VERSION ""

NS_ :

BS_:

BU_: PFAF_HS LVMPC_HS DCDC_HS AMP_HS VICM2_HS FICM_HS ARS_HS MCP_B_HS MCP_A_HS ICCM_OBD_HS SAS_HS ACCM_HS VLBS_HS EBCM_OBD_HS EDI_HS HPCC_HS VITM_OBD_HS PTAM_HS OBCM_HS VICM_HS HCP_HS FDCM_HS APPS_HS ICCM_HS EOCM_F_HS GPCM_HS FSCM_ITBC_HS SCM_HS ITBC_HS VCM_HS HMIM_HS FCP_HS VES_HS Dummy_HS MCP_C_HS RWS_HS ONSTAR_HS EPS_HS TestTool_HS MCP_HS BCP_HS ALC_HS AHL_AFL_HS SADS_HS EPB_HS FSCM_HS AFS_HS FCM_HS TCCM_HS RDCM_HS PTO_HS PCM_HS EBCM_HS ACC_HS BCM_HS TCM_HS ECM_HS

BO_ 417 ETEI_Engine_General_Status: 7 ECM_HS
  SG_ EngCrsCntrlMode: 29|3@0+ (1,0) [0|7] "" TCM_HS
  SG_ EngPstOxgSnsDgAstRq: 31|1@0+ (1,0) [0|1] "" TCM_HS
  SG_ CrsCtrlCnstSpdAct: 26|1@0+ (1,0) [0|1] "" TCM_HS
  SG_ WrmUpShftPtrnRq: 25|1@0+ (1,0) [0|1] "" TCM_HS
  SG_ EngIdlSpdRdcdRng: 39|8@0+ (8,0) [0|2040] "rpm" BCP_HS TCM_HS
  SG_ EngAlwCltAdp: 24|1@0+ (1,0) [0|1] "" TCM_HS
  SG_ BsTrgtEngIdlSpd: 47|8@0+ (8,0) [0|2040] "rpm" TCM_HS
  SG_ AccPdlPosPcntFullRngV: 17|1@0+ (1,0) [0|1] "" TCM_HS
  SG_ AccPdlPosPcntFullRng: 55|8@0+ (0.39215702,0) [0|100.00004] "%" TCM_HS
  SG_ DslPrtFltrIdlRgtnMdReq: 20|1@0+ (1,0) [0|1] "" TCM_HS
  SG_ DslPartFltrClngAlgActM: 18|1@0+ (1,0) [0|1] "" TCM_HS
  SG_ DslPartFltrClngAlgAct: 19|1@0+ (1,0) [0|1] "" TCM_HS
  SG_ EngCylDeactMd: 9|2@0+ (1,0) [0|3] "" BCP_HS
  SG_ ACCmCltEngd: 13|1@0+ (1,0) [0|1] "" TCM_HS
  SG_ ParkNeutralSwStatV: 21|1@0+ (1,0) [0|1] "" TCM_HS
  SG_ ParkNeutralSwStat: 22|1@0+ (1,0) [0|1] "" TCM_HS
  SG_ EngColdHiIdleActive: 23|1@0+ (1,0) [0|1] "" TCM_HS
  SG_ EngCyDactTqSmtAct: 6|1@0+ (1,0) [0|1] "" TCM_HS
  SG_ EngBrkStat: 15|2@0+ (1,0) [0|3] "" TCM_HS
  SG_ TracCntlSysPwrtrnInhbt: 12|1@0+ (1,0) [0|1] "" TCM_HS
  SG_ EngMtlProtAtv: 11|1@0+ (1,0) [0|1] "" TCM_HS
  SG_ EngDgTrqCnvClUnlkRqd: 7|1@0+ (1,0) [0|1] "" TCM_HS
  SG_ EngCyldrDeactReqd: 10|1@0+ (1,0) [0|1] "" TCM_HS
  SG_ ETGRReqdGear: 3|4@0+ (1,0) [0|15] "" TCM_HS
  SG_ ETGRReqType: 5|2@0+ (1,0) [0|3] "" TCM_HS

BO_ 1233 PPEI_Engine_General_Status_5: 8 ECM_HS
  SG_ EngShtdwnAct: 48|1@0+ (1,0) [0|1] "" Vector__XXX
  SG_ EngShtdwnPndgIO: 49|1@0+ (1,0) [0|1] "" FCP_HS ONSTAR_HS BCM_HS
  SG_ FuelFltChgNwIO: 51|1@0+ (1,0) [0|1] "" FCP_HS ONSTAR_HS BCM_HS
  SG_ PTExPrtclFltrWrn2IO: 50|1@0+ (1,0) [0|1] "" PTO_HS FCP_HS ONSTAR_HS BCM_HS
  SG_ PTHiElecLdReqd: 52|1@0+ (1,0) [0|1] "" BCM_HS
  SG_ PTExPrtclFltrWrnIO: 53|1@0+ (1,0) [0|1] "" PTO_HS FCP_HS ONSTAR_HS BCM_HS
  SG_ AirCndOffIO: 0|1@0+ (1,0) [0|1] "" BCM_HS
  SG_ DslGlwPlgIO: 55|1@0+ (1,0) [0|1] "" BCM_HS
  SG_ StgDisIO: 30|1@0+ (1,0) [0|1] "" BCM_HS
  SG_ RdcdPwrIO: 31|1@0+ (1,0) [0|1] "" FCP_HS ONSTAR_HS BCM_HS
  SG_ FuelTotCap: 27|12@0+ (0.125,0) [0|511.875] "liters" EDI_HS LVMPC_HS BCM_HS
  SG_ FlLvlPctV: 28|1@0+ (1,0) [0|1] "" EDI_HS LVMPC_HS AHL_AFL_HS PTO_HS FICM_HS BCM_HS
  SG_ FlLvlPct: 47|8@0+ (0.39215702,0) [0|100.00004] "%" EDI_HS LVMPC_HS PTO_HS AHL_AFL_HS FICM_HS BCM_HS
  SG_ EngWtrInFlIO: 54|1@0+ (1,0) [0|1] "" FCP_HS ONSTAR_HS BCM_HS
  SG_ EngOilTmpV: 7|1@0+ (1,0) [0|1] "" EDI_HS LVMPC_HS EPS_HS BCM_HS
  SG_ EngOilTmp: 15|8@0+ (1,-40) [-40|215] "deg C" EDI_HS LVMPC_HS EPS_HS BCM_HS
  SG_ EngOilPrsV: 6|1@0+ (1,0) [0|1] "" EDI_HS LVMPC_HS PTO_HS BCM_HS
  SG_ EngOilPrsLwIO: 5|1@0+ (1,0) [0|1] "" PTO_HS FCP_HS ONSTAR_HS BCM_HS
  SG_ EngOilPrs: 23|8@0+ (4,0) [0|1020] "kPa" EDI_HS LVMPC_HS PTO_HS BCM_HS
  SG_ EngOilLvlLwIO: 4|1@0+ (1,0) [0|1] "" PTO_HS FCP_HS ONSTAR_HS BCM_HS
  SG_ EngOilChngIO: 3|1@0+ (1,0) [0|1] "" BCM_HS
  SG_ EngHt_StpEngIO: 1|1@0+ (1,0) [0|1] "" PTO_HS FCP_HS ONSTAR_HS BCM_HS
  SG_ EngHotFuelEnrchmntIO: 2|1@0+ (1,0) [0|1] "" FCP_HS ONSTAR_HS BCM_HS
  SG_ CkFlFilrCapIO: 29|1@0+ (1,0) [0|1] "" BCM_HS

BO_ 1217 PPEI_Engine_General_Status_4: 8 ECM_HS
  SG_ LegPstDTCClrDrvCyCm: 40|1@0+ (1,0) [0|1] "" VICM2_HS EBCM_OBD_HS EBCM_HS VICM_HS OBCM_HS VITM_OBD_HS BCP_HS ICCM_OBD_HS ICCM_HS FSCM_ITBC_HS FSCM_HS TCM_HS
  SG_ LegDiagColdStCndMet: 47|1@0+ (1,0) [0|1] "" VICM2_HS FICM_HS ICCM_OBD_HS ICCM_HS FSCM_ITBC_HS FSCM_HS MCP_HS EBCM_OBD_HS EBCM_HS OBCM_HS BCP_HS TCCM_HS VITM_OBD_HS VICM_HS TCM_HS
  SG_ LegDiagColdStCndFltPr: 46|1@0+ (1,0) [0|1] "" VICM2_HS FICM_HS ICCM_OBD_HS ICCM_HS FSCM_ITBC_HS FSCM_HS MCP_HS EBCM_OBD_HS EBCM_HS OBCM_HS TCCM_HS VITM_OBD_HS VICM_HS TCM_HS BCP_HS
  SG_ EngEconMdCmnd: 44|1@0+ (1,0) [0|1] "" TCM_HS
  SG_ DslExhFldRmngDstHRsV: 41|1@0+ (1,0) [0|1] "" BCM_HS FCP_HS ONSTAR_HS
  SG_ DslExhFldRmngDstHRs: 54|15@0+ (2,0) [0|65534] "km" BCM_HS FCP_HS ONSTAR_HS
  SG_ EngOilHotIO: 45|1@0+ (1,0) [0|1] "" BCM_HS
  SG_ OAT_PT_EstV: 3|1@0+ (1,0) [0|1] "" FICM_HS TCM_HS TCCM_HS AHL_AFL_HS HCP_HS BCP_HS RDCM_HS BCM_HS EBCM_OBD_HS EBCM_HS
  SG_ LegDiagStndCndMet: 2|1@0+ (1,0) [0|1] "" VICM2_HS FICM_HS MCP_HS EBCM_OBD_HS EBCM_HS OBCM_HS VITM_OBD_HS VICM_HS BCP_HS FCP_HS ONSTAR_HS ICCM_OBD_HS ICCM_HS FSCM_ITBC_HS FSCM_HS TCM_HS TCCM_HS
  SG_ LegDiagStndCndFltPr: 1|1@0+ (1,0) [0|1] "" VICM2_HS FICM_HS MCP_HS EBCM_OBD_HS EBCM_HS VITM_OBD_HS VICM_HS OBCM_HS BCP_HS ICCM_OBD_HS ICCM_HS FSCM_ITBC_HS FSCM_HS TCM_HS TCCM_HS
  SG_ OAT_PT_EstM: 4|1@0+ (1,0) [0|1] "" FICM_HS HCP_HS TCM_HS TCCM_HS AHL_AFL_HS BCP_HS RDCM_HS BCM_HS EBCM_OBD_HS EBCM_HS
  SG_ OAT_PT_Est: 39|8@0+ (0.5,-40) [-40|87.5] "deg C" FICM_HS TCM_HS TCCM_HS AHL_AFL_HS HCP_HS BCP_HS RDCM_HS BCM_HS EBCM_OBD_HS EBCM_HS
  SG_ EngWrmUpAch: 0|1@0+ (1,0) [0|1] "" FICM_HS MCP_HS VITM_OBD_HS EBCM_OBD_HS EBCM_HS VICM_HS OBCM_HS BCP_HS ICCM_OBD_HS ICCM_HS FSCM_ITBC_HS FSCM_HS TCM_HS TCCM_HS
  SG_ EngIntAirTmpV: 5|1@0+ (1,0) [0|1] "" EDI_HS ICCM_OBD_HS ICCM_HS RDCM_HS VICM2_HS FICM_HS VICM_HS EBCM_OBD_HS EBCM_HS FCP_HS ONSTAR_HS SADS_HS BCP_HS TCCM_HS HCP_HS BCM_HS
  SG_ EngIntAirTmp: 31|8@0+ (1,-40) [-40|215] "deg C" EDI_HS ICCM_OBD_HS ICCM_HS RDCM_HS VICM2_HS FICM_HS VICM_HS EBCM_OBD_HS EBCM_HS FCP_HS ONSTAR_HS SADS_HS BCP_HS TCCM_HS HCP_HS BCM_HS
  SG_ EngCltTmpV: 6|1@0+ (1,0) [0|1] "" EDI_HS LVMPC_HS EPS_HS VCM_HS FICM_HS ICCM_OBD_HS ICCM_HS FSCM_HS VICM_HS FCP_HS ONSTAR_HS SADS_HS HCP_HS BCP_HS VICM2_HS BCM_HS EBCM_OBD_HS EBCM_HS
  SG_ EngCltTmp: 23|8@0+ (1,-40) [-40|215] "deg C" EDI_HS LVMPC_HS EPS_HS VCM_HS FICM_HS ICCM_OBD_HS ICCM_HS FSCM_HS VICM_HS FCP_HS ONSTAR_HS SADS_HS HCP_HS BCP_HS VICM2_HS BCM_HS EBCM_OBD_HS EBCM_HS
  SG_ BarPrsAbsV: 7|1@0+ (1,0) [0|1] "" EDI_HS VICM_HS FICM_HS EBCM_OBD_HS EBCM_HS BCP_HS HCP_HS ICCM_OBD_HS ICCM_HS FSCM_ITBC_HS FSCM_HS BCM_HS
  SG_ BarPrsAbs: 15|8@0+ (0.5,0) [0|127.5] "kPa" EDI_HS VICM_HS FICM_HS EBCM_OBD_HS EBCM_HS BCP_HS HCP_HS ICCM_OBD_HS ICCM_HS FSCM_ITBC_HS FSCM_HS BCM_HS

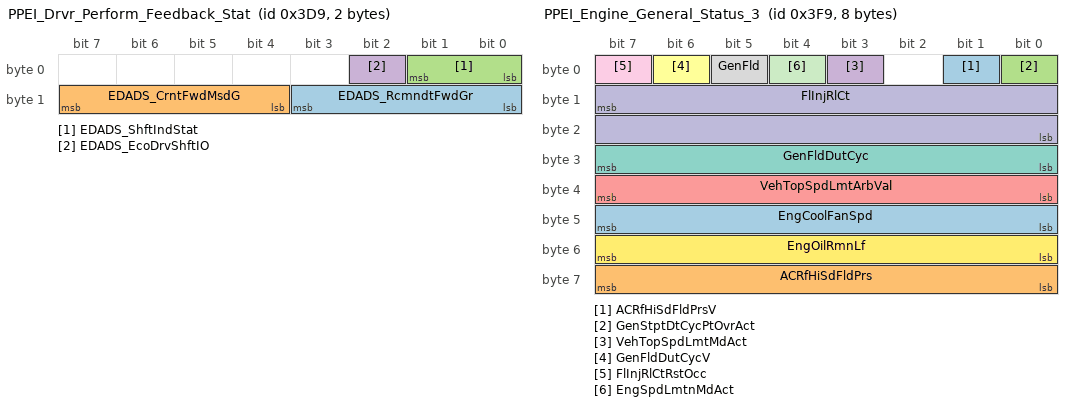
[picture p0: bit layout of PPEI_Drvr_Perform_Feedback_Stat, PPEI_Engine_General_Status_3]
BO_ 985 PPEI_Drvr_Perform_Feedback_Stat: 2 ECM_HS
  SG_ EDADS_RcmndtFwdGr: 11|4@0+ (1,0) [0|15] "" BCM_HS
  SG_ EDADS_CrntFwdMsdG: 15|4@0+ (1,0) [0|15] "" BCM_HS
  SG_ EDADS_ShftIndStat: 1|2@0+ (1,0) [0|3] "" BCM_HS
  SG_ EDADS_EcoDrvShftIO: 2|1@0+ (1,0) [0|1] "" BCM_HS

BO_ 1017 PPEI_Engine_General_Status_3: 8 ECM_HS
  SG_ ACRfHiSdFldPrsV: 1|1@0+ (1,0) [0|1] "" VICM2_HS ICCM_OBD_HS ICCM_HS FSCM_HS VICM_HS FCP_HS ONSTAR_HS BCM_HS
  SG_ ACRfHiSdFldPrs: 63|8@0+ (14,0) [0|3570] "kPaG" VICM2_HS ICCM_OBD_HS ICCM_HS FSCM_HS VICM_HS FCP_HS ONSTAR_HS BCM_HS
  SG_ GenStptDtCycPtOvrAct: 0|1@0+ (1,0) [0|1] "" BCM_HS
  SG_ VehTopSpdLmtMdAct: 3|1@0+ (1,0) [0|1] "" PTO_HS BCM_HS
  SG_ VehTopSpdLmtArbVal: 39|8@0+ (2,0) [0|510] "km / h" PTO_HS BCM_HS
  SG_ GenFldDutCycV: 6|1@0+ (1,0) [0|1] "" BCM_HS
  SG_ GenFldDutCyc: 31|8@0+ (0.39215702,0) [0|100.00004] "%" BCM_HS
  SG_ GenFld: 5|1@0+ (1,0) [0|1] "" FCP_HS ONSTAR_HS AFS_HS BCM_HS
  SG_ FlInjRlCtRstOcc: 7|1@0+ (1,0) [0|1] "" VICM_HS FCP_HS ONSTAR_HS BCM_HS
  SG_ FlInjRlCt: 15|16@0+ (3.05176e-05,0) [0|1.9999709] "liters" VICM_HS FCP_HS ONSTAR_HS BCM_HS
  SG_ EngSpdLmtnMdAct: 4|1@0+ (1,0) [0|1] "" BCM_HS
  SG_ EngOilRmnLf: 55|8@0+ (0.39215702,0) [0|100.00004] "%" BCM_HS
  SG_ EngCoolFanSpd: 47|8@0+ (0.39215702,0) [0|100.00004] "%" VICM_HS VICM2_HS ICCM_OBD_HS ICCM_HS FSCM_HS BCM_HS

BO_ 977 PPEI_Engine_General_Status_2: 8 ECM_HS
  SG_ AutoMdSpdLmtStat: 6|2@0+ (1,0) [0|3] "" BCM_HS
  SG_ FuelFltLifRstPerf: 38|1@0+ (1,0) [0|1] "" FCP_HS ONSTAR_HS BCM_HS
  SG_ SpdLmtrSpdWrngAct: 4|1@0+ (1,0) [0|1] "" TCM_HS BCM_HS
  SG_ CrsCntlDrSelSpdAct: 39|1@0+ (1,0) [0|1] "" BCM_HS
  SG_ ACCmpNrmLdGrdAld: 63|8@0+ (0.1,0) [0|25.5] "dm3/m/s" BCM_HS
  SG_ ACCompCmnd: 37|1@0+ (1,0) [0|1] "" VICM2_HS ICCM_OBD_HS ICCM_HS FSCM_HS BCM_HS
  SG_ EngBstPrsIndV: 23|1@0+ (1,0) [0|1] "" LVMPC_HS BCM_HS
  SG_ EngBstPrsInd: 55|8@0+ (0.39215702,0) [0|100.00004] "%" LVMPC_HS BCM_HS
  SG_ EngOilLifRstPerf: 36|1@0+ (1,0) [0|1] "" BCM_HS
  SG_ ThrPosV: 7|1@0+ (1,0) [0|1] "" EDI_HS ACC_HS EOCM_F_HS SADS_HS BCM_HS
  SG_ ThrPos: 15|8@0+ (0.39215702,0) [0|100.00004] "%" EDI_HS ACC_HS EOCM_F_HS SADS_HS BCM_HS
  SG_ InstFuelConsmpRate: 35|12@0+ (0.025000002,0) [0|102.375] "ltrs/hr" EDI_HS BCM_HS
  SG_ EngOilStrvtnIO: 21|1@0+ (1,0) [0|1] "" BCM_HS
  SG_ EngNEmsnsRelMalfAct: 3|1@0+ (1,0) [0|1] "" BCM_HS
  SG_ EngEmsRelMalfIndReq: 2|3@0+ (1,0) [0|7] "" BCM_HS
  SG_ EngCstFlCutAct: 22|1@0+ (1,0) [0|1] "" TCM_HS VICM_HS BCP_HS BCM_HS
  SG_ CrsSpdLmtrDrvSelSpd: 19|12@0+ (0.0625,0) [0|255.9375] "km / h" TCM_HS BCM_HS

BO_ 201 PPEI_Engine_General_Status_1: 8 ECM_HS
  SG_ PrsElvtdIdlCntlStat: 49|1@0+ (1,0) [0|1] "" BCM_HS
  SG_ Eng12vStrtrMtrCmmdOn: 53|1@0+ (1,0) [0|1] "" BCM_HS DCDC_HS RDCM_HS MCP_C_HS FICM_HS TCM_HS HCP_HS BCP_HS MCP_B_HS MCP_A_HS EPB_HS EBCM_OBD_HS EBCM_HS TCCM_HS VES_HS EPS_HS
  SG_ EngCntrlRunCrnkTrmSt: 52|1@0+ (1,0) [0|1] "" MCP_C_HS TCM_HS EBCM_OBD_HS EBCM_HS MCP_B_HS MCP_A_HS HCP_HS BCP_HS VITM_OBD_HS VICM_HS OBCM_HS FSCM_ITBC_HS ACCM_HS VICM2_HS FSCM_HS ICCM_OBD_HS ICCM_HS FICM_HS
  SG_ EngAirIntBstPrV: 51|1@0+ (1,0) [0|1] "" EDI_HS LVMPC_HS FICM_HS BCM_HS
  SG_ EngAirIntBstPr: 63|8@0- (1,0) [-128|127] "kPaG" EDI_HS LVMPC_HS FICM_HS BCM_HS
  SG_ SpdLmtrSpdWrngEnbld: 47|1@0+ (1,0) [0|1] "" PTO_HS BCM_HS
  SG_ EngCylDactEvntPndg: 54|1@0+ (1,0) [0|1] "" ICCM_OBD_HS ICCM_HS FSCM_ITBC_HS FSCM_HS AMP_HS
  SG_ EngCylDeactMd: 43|2@0+ (1,0) [0|3] "" FSCM_ITBC_HS FSCM_HS ICCM_OBD_HS ICCM_HS AMP_HS BCM_HS
  SG_ RmVhStrtEngRng: 55|1@0+ (1,0) [0|1] "" EBCM_OBD_HS EBCM_HS TCCM_HS BCP_HS HCP_HS EPB_HS BCM_HS
  SG_ PFEngSpdCmndSpcd: 45|1@0+ (1,0) [0|1] "" BCM_HS PTO_HS
  SG_ DrThrtlOvrrdDetProtVal: 25|2@0+ (1,0) [0|3] "" ACC_HS EBCM_OBD_HS EBCM_HS
  SG_ DrThrtlOvrdDetAlvRlCnt: 27|2@0+ (1,0) [0|3] "" EBCM_OBD_HS EBCM_HS ACC_HS
  SG_ PltfrmEngSpdCmdInhtRq: 44|1@0+ (1,0) [0|1] "" BCM_HS PTO_HS
  SG_ PT_BrkPedDscrtInpStatV: 41|1@0+ (1,0) [0|1] "" TCCM_HS BCP_HS PTO_HS ACC_HS EBCM_OBD_HS EBCM_HS
  SG_ PT_BrkPedDscrtInpStat: 40|1@0+ (1,0) [0|1] "" TCCM_HS BCP_HS PTO_HS ACC_HS EBCM_OBD_HS EBCM_HS
  SG_ AccActPos: 39|8@0+ (0.39215702,0) [0|100.00004] "%" LVMPC_HS EDI_HS ICCM_OBD_HS ICCM_HS VICM_HS PTAM_HS HCP_HS EBCM_OBD_HS EBCM_HS BCP_HS AHL_AFL_HS AFS_HS EPB_HS SADS_HS RDCM_HS BCM_HS TCM_HS TCCM_HS
  SG_ CrsCntEnbld: 29|1@0+ (1,0) [0|1] "" PTO_HS ACC_HS EOCM_F_HS BCM_HS
  SG_ CrsCntAtv: 30|1@0+ (1,0) [0|1] "" EBCM_OBD_HS EBCM_HS RDCM_HS PTO_HS BCP_HS EPB_HS BCM_HS TCM_HS
  SG_ DrvThrottlOvrrdDet: 28|1@0+ (1,0) [0|1] "" PTO_HS ACC_HS EBCM_OBD_HS EBCM_HS BCM_HS
  SG_ PT_CrnkAct: 6|1@0+ (1,0) [0|1] "" VCM_HS FICM_HS VES_HS EPS_HS EBCM_OBD_HS EBCM_HS HCP_HS PTO_HS BCP_HS ICCM_OBD_HS ICCM_HS FSCM_ITBC_HS FSCM_HS
  SG_ PTRunAbrt: 4|1@0+ (1,0) [0|1] "" BCP_HS BCM_HS
  SG_ PTO_PT_RunAbrtd: 3|1@0+ (1,0) [0|1] "" PTO_HS BCM_HS
  SG_ PTCrnkAbrted: 5|1@0+ (1,0) [0|1] "" BCP_HS PTO_HS BCM_HS
  SG_ EngSpdStat: 1|2@0+ (1,0) [0|3] "" PFAF_HS PTO_HS AHL_AFL_HS VICM2_HS FICM_HS AMP_HS VICM_HS VES_HS EPS_HS PTAM_HS TCCM_HS BCP_HS ICCM_OBD_HS ICCM_HS FSCM_ITBC_HS FSCM_HS RDCM_HS EBCM_OBD_HS EBCM_HS EPB_HS ACC_HS BCM_HS SADS_HS
  SG_ EngSpd: 15|16@0+ (0.25,0) [0|16383.75] "rpm" PFAF_HS EDI_HS LVMPC_HS DCDC_HS PTO_HS AHL_AFL_HS VICM2_HS EOCM_F_HS FICM_HS AMP_HS FCP_HS ONSTAR_HS VICM_HS PTAM_HS VES_HS EPS_HS TCCM_HS HCP_HS BCP_HS ICCM_OBD_HS ICCM_HS FSCM_ITBC_HS FSCM_HS EPB_HS RDCM_HS AFS_HS EBCM_OBD_HS EBCM_HS ACC_HS BCM_HS SADS_HS
  SG_ EngRunAtv: 7|1@0+ (1,0) [0|1] "" DCDC_HS VCM_HS RDCM_HS ARS_HS AMP_HS VICM2_HS ACC_HS VICM_HS APPS_HS EOCM_F_HS BCP_HS FCP_HS ONSTAR_HS FSCM_ITBC_HS FSCM_HS ICCM_OBD_HS ICCM_HS ALC_HS VES_HS EPS_HS EBCM_OBD_HS EBCM_HS AHL_AFL_HS EPB_HS SADS_HS AFS_HS BCM_HS TCCM_HS
  SG_ EngIdlAtv: 2|1@0+ (1,0) [0|1] "" PTO_HS FICM_HS AMP_HS EPB_HS BCM_HS
  SG_ AccActPosV: 31|1@0+ (1,0) [0|1] "" LVMPC_HS EDI_HS ICCM_OBD_HS ICCM_HS VICM_HS PTAM_HS HCP_HS EBCM_OBD_HS EBCM_HS BCP_HS AHL_AFL_HS EPB_HS AFS_HS SADS_HS BCM_HS RDCM_HS TCM_HS TCCM_HS

BO_ 501 PPEI_Trans_General_Status_2: 8 ECM_HS
  SG_ EngRecDwnshftIO: 54|1@0+ (1,0) [0|1] "" BCM_HS
  SG_ TrnsPattSelEcnMdOCm: 52|1@0+ (1,0) [0|1] "" ICCM_OBD_HS ICCM_HS PCM_HS ECM_HS
  SG_ CltStartSwAtvV: 38|1@0+ (1,0) [0|1] "" TCCM_HS PTAM_HS RDCM_HS BCM_HS
  SG_ CltStartSwAtv: 37|1@0+ (1,0) [0|1] "" TCCM_HS PTAM_HS BCM_HS RDCM_HS
  SG_ CltchPdlActPosV: 55|1@0+ (1,0) [0|1] "" TCCM_HS LVMPC_HS EDI_HS EBCM_OBD_HS EBCM_HS ICCM_OBD_HS ICCM_HS ECM_HS PTAM_HS EPB_HS RDCM_HS
  SG_ CltchPdlActPos: 63|8@0+ (0.39215702,0) [0|100.00004] "%" TCCM_HS LVMPC_HS EDI_HS EBCM_OBD_HS EBCM_HS ICCM_OBD_HS ICCM_HS ECM_HS PTAM_HS EPB_HS RDCM_HS
  SG_ TrnsEngdStateV: 50|1@0+ (1,0) [0|1] "" ICCM_OBD_HS ICCM_HS BCP_HS ACC_HS EBCM_OBD_HS EBCM_HS EPB_HS SADS_HS RDCM_HS AFS_HS AHL_AFL_HS BCM_HS
  SG_ TrnsEngdState: 49|2@0+ (1,0) [0|3] "" ICCM_OBD_HS ICCM_HS BCP_HS ACC_HS EBCM_OBD_HS EBCM_HS EPB_HS SADS_HS RDCM_HS AFS_HS AHL_AFL_HS BCM_HS
  SG_ TrnsShftLvrLckRqd: 47|1@0+ (1,0) [0|1] "" ICCM_OBD_HS ICCM_HS BCM_HS
  SG_ TransTUDMdStat: 41|2@0+ (1,0) [0|3] "" ICCM_OBD_HS ICCM_HS EBCM_OBD_HS EBCM_HS BCP_HS ACC_HS EOCM_F_HS BCM_HS PCM_HS ECM_HS
  SG_ TrnCrpMdAtv: 46|1@0+ (1,0) [0|1] "" ICCM_OBD_HS ICCM_HS PCM_HS ECM_HS BCM_HS
  SG_ TrnsSkpShftIO: 23|1@0+ (1,0) [0|1] "" ICCM_OBD_HS ICCM_HS BCM_HS
  SG_ TrnsSftMdStat: 34|3@0+ (1,0) [0|7] "" ICCM_OBD_HS ICCM_HS EBCM_OBD_HS EBCM_HS BCM_HS
  SG_ TrnsRngInhbtStat: 31|3@0+ (1,0) [0|7] "" ICCM_OBD_HS ICCM_HS BCM_HS
  SG_ TopTrvlCltchSwActV: 15|1@0+ (1,0) [0|1] "" PTO_HS PTAM_HS RDCM_HS BCM_HS ACC_HS EBCM_OBD_HS EBCM_HS EPB_HS
  SG_ TopTrvlCltchSwAct: 14|1@0+ (1,0) [0|1] "" PTO_HS PTAM_HS RDCM_HS BCM_HS EPB_HS ACC_HS EBCM_OBD_HS EBCM_HS
  SG_ EngRecmndUpshftIO: 22|1@0+ (1,0) [0|1] "" BCM_HS
  SG_ DrvtShftCntrlTrgtGear: 19|4@0+ (1,0) [0|15] "" ICCM_OBD_HS ICCM_HS BCM_HS
  SG_ DrShftCntrlReqDndIO: 21|1@0+ (1,0) [0|1] "" ICCM_OBD_HS ICCM_HS BCM_HS
  SG_ TrnShftPtrnActStat: 44|3@0+ (1,0) [0|7] "" ICCM_OBD_HS ICCM_HS ALC_HS ARS_HS AHL_AFL_HS VES_HS EPS_HS SADS_HS BCM_HS EBCM_OBD_HS EBCM_HS
  SG_ TrnsFldPrsPrsnt: 51|1@0+ (1,0) [0|1] "" PCM_HS ECM_HS
  SG_ TrnsShftLvrPos: 27|4@0+ (1,0) [0|15] "" EPS_HS PTO_HS ICCM_OBD_HS ICCM_HS HMIM_HS EOCM_F_HS VICM_HS HCP_HS BCP_HS EPB_HS BCM_HS EBCM_OBD_HS EBCM_HS PCM_HS ECM_HS
  SG_ TrnsShftLvrPosV: 28|1@0+ (1,0) [0|1] "" EPS_HS PTO_HS ICCM_OBD_HS ICCM_HS HMIM_HS EOCM_F_HS VICM_HS HCP_HS BCP_HS EPB_HS BCM_HS EBCM_OBD_HS EBCM_HS PCM_HS ECM_HS
  SG_ TrnsTrqCnvCltCmndMd: 7|3@0+ (1,0) [0|7] "" PTO_HS BCP_HS PCM_HS ECM_HS
  SG_ AutoTransComndGear: 11|4@0+ (1,0) [0|15] "" ICCM_OBD_HS ICCM_HS TCCM_HS EOCM_F_HS RDCM_HS BCP_HS EBCM_OBD_HS EBCM_HS ACC_HS BCM_HS SADS_HS PCM_HS ECM_HS
  SG_ AutoTransGrSftDirect: 13|2@0+ (1,0) [0|3] "" ICCM_OBD_HS ICCM_HS EOCM_F_HS ACC_HS BCP_HS RDCM_HS EBCM_OBD_HS EBCM_HS SADS_HS PCM_HS ECM_HS
  SG_ TransEstGear: 3|4@0+ (1,0) [0|15] "" PFAF_HS PTO_HS LVMPC_HS EDI_HS HMIM_HS FSCM_HS ARS_HS BCP_HS PTAM_HS EOCM_F_HS VES_HS ICCM_OBD_HS ICCM_HS ALC_HS SADS_HS FCP_HS ONSTAR_HS RDCM_HS AFS_HS EBCM_OBD_HS EBCM_HS EPB_HS EPS_HS ACC_HS BCM_HS TCCM_HS PCM_HS ECM_HS
  SG_ TransEstGearV: 4|1@0+ (1,0) [0|1] "" PFAF_HS PTO_HS LVMPC_HS EDI_HS HMIM_HS FSCM_HS ARS_HS BCP_HS PTAM_HS EOCM_F_HS ICCM_OBD_HS ICCM_HS ALC_HS VES_HS EPS_HS SADS_HS RDCM_HS AFS_HS FCP_HS ONSTAR_HS EBCM_OBD_HS EBCM_HS EPB_HS ACC_HS BCM_HS TCCM_HS PCM_HS ECM_HS

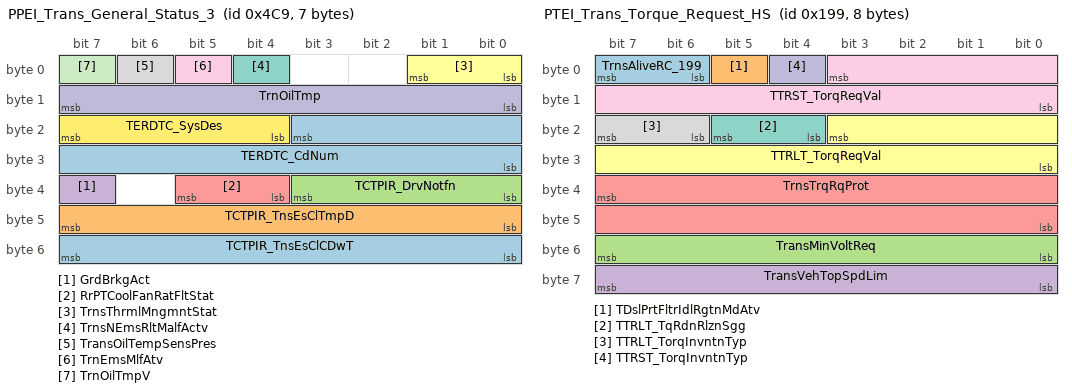
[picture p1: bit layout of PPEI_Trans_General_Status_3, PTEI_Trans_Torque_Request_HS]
BO_ 1225 PPEI_Trans_General_Status_3: 7 ECM_HS
  SG_ TCTPIR_TnsEsClCDwT: 55|8@0+ (0.39215702,0) [0|100.00004] "%" BCM_HS
  SG_ TCTPIR_TnsEsClTmpD: 47|8@0+ (0.39215702,0) [0|100.00004] "%" BCM_HS
  SG_ TCTPIR_DrvNotfn: 35|4@0+ (1,0) [0|15] "" BCM_HS
  SG_ GrdBrkgAct: 39|1@0+ (1,0) [0|1] "" BCM_HS
  SG_ RrPTCoolFanRatFltStat: 37|2@0+ (1,0) [0|4] "" ICCM_OBD_HS ICCM_HS
  SG_ TrnsThrmlMngmntStat: 1|2@0+ (1,0) [0|3] "" PTO_HS BCM_HS
  SG_ TrnsNEmsRltMalfActv: 4|1@0+ (1,0) [0|1] "" FCP_HS ONSTAR_HS BCM_HS
  SG_ TransOilTempSensPres: 6|1@0+ (1,0) [0|1] "" VICM_HS FCP_HS ONSTAR_HS TCCM_HS BCM_HS
  SG_ TrnEmsMlfAtv: 5|1@0+ (1,0) [0|1] "" BCM_HS PCM_HS ECM_HS
  SG_ TrnOilTmp: 15|8@0+ (1,-40) [-40|215] "deg C" LVMPC_HS EDI_HS VCM_HS VICM2_HS VICM_HS MCP_A_HS MCP_B_HS FCP_HS ONSTAR_HS TCCM_HS HCP_HS BCP_HS BCM_HS PCM_HS ECM_HS
  SG_ TrnOilTmpV: 7|1@0+ (1,0) [0|1] "" LVMPC_HS EDI_HS VCM_HS VICM2_HS VICM_HS MCP_A_HS MCP_B_HS FCP_HS ONSTAR_HS TCCM_HS HCP_HS BCP_HS BCM_HS PCM_HS ECM_HS
  SG_ TERDTC_SysDes: 23|4@0+ (1,0) [0|15] "" PCM_HS ECM_HS
  SG_ TERDTC_CdNum: 19|12@0+ (1,0) [0|4095] "" PCM_HS ECM_HS

BO_ 409 PTEI_Trans_Torque_Request_HS: 8 TCM_HS
  SG_ TrnsAliveRC_199: 7|2@0+ (1,0) [0|3] "" PCM_HS ECM_HS
  SG_ TDslPrtFltrIdlRgtnMdAtv: 5|1@0+ (1,0) [0|1] "" PCM_HS ECM_HS
  SG_ TransMinVoltReq: 55|8@0+ (0.078430012,0) [0|19.999651] "volts" PCM_HS ECM_HS
  SG_ TransVehTopSpdLim: 63|8@0+ (2,0) [0|510] "km / h" PCM_HS ECM_HS
  SG_ TrnsTrqRqProt: 39|16@0+ (1,0) [0|65535] "" PCM_HS ECM_HS
  SG_ TTRLT_TorqReqVal: 19|12@0+ (0.5,-848) [-848|1199.5] "Nm" PCM_HS ECM_HS
  SG_ TTRLT_TqRdnRlznSgg: 21|2@0+ (1,0) [0|3] "" PCM_HS ECM_HS
  SG_ TTRLT_TorqInvntnTyp: 23|2@0+ (1,0) [0|3] "" PCM_HS ECM_HS
  SG_ TTRST_TorqReqVal: 3|12@0+ (0.5,-848) [-848|1199.5] "Nm" PCM_HS ECM_HS
  SG_ TTRST_TorqInvntnTyp: 4|1@0+ (1,0) [0|1] "" PCM_HS ECM_HS

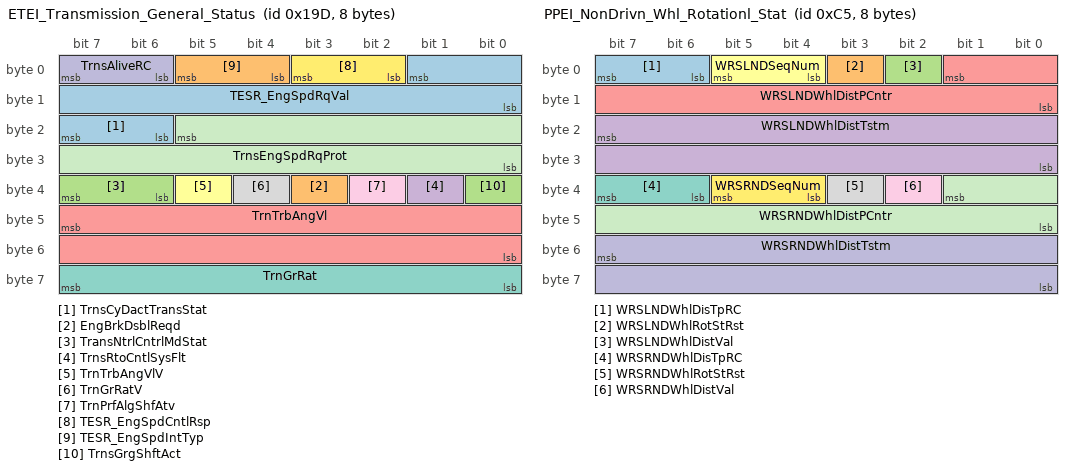
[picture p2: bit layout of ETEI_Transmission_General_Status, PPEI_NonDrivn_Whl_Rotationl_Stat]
BO_ 413 ETEI_Transmission_General_Status: 8 TCM_HS
  SG_ TrnsCyDactTransStat: 23|2@0+ (1,0) [0|3] "" PCM_HS ECM_HS
  SG_ EngBrkDsblReqd: 35|1@0+ (1,0) [0|1] "" PCM_HS ECM_HS
  SG_ TransNtrlCntrlMdStat: 39|2@0+ (1,0) [0|3] "" EBCM_OBD_HS EBCM_HS BCM_HS PCM_HS ECM_HS
  SG_ TrnsRtoCntlSysFlt: 33|1@0+ (1,0) [0|1] "" PCM_HS ECM_HS
  SG_ TrnTrbAngVl: 47|16@0+ (0.25,0) [0|16383.75] "rpm" BCP_HS PCM_HS ECM_HS
  SG_ TrnTrbAngVlV: 37|1@0+ (1,0) [0|1] "" BCP_HS PCM_HS ECM_HS
  SG_ TrnGrRat: 63|8@0+ (0.03125,0) [0|7.96875] "" EOCM_F_HS PTAM_HS BCP_HS PCM_HS ECM_HS
  SG_ TrnGrRatV: 36|1@0+ (1,0) [0|1] "" EOCM_F_HS PTAM_HS BCP_HS PCM_HS ECM_HS
  SG_ TrnPrfAlgShfAtv: 34|1@0+ (1,0) [0|1] "" PCM_HS ECM_HS
  SG_ TrnsAliveRC: 7|2@0+ (1,0) [0|3] "" PCM_HS ECM_HS
  SG_ TrnsEngSpdRqProt: 21|14@0+ (1,0) [0|16383] "" PCM_HS ECM_HS
  SG_ TESR_EngSpdCntlRsp: 3|2@0+ (1,0) [0|3] "" PCM_HS ECM_HS
  SG_ TESR_EngSpdRqVal: 1|10@0+ (8,0) [0|8184] "rpm" PCM_HS ECM_HS
  SG_ TESR_EngSpdIntTyp: 5|2@0+ (1,0) [0|3] "" PCM_HS ECM_HS
  SG_ TrnsGrgShftAct: 32|1@0+ (1,0) [0|1] "" PCM_HS ECM_HS

BO_ 257 USDT_Req_to_All_HS_ECUs: 8 TestTool_HS
  SG_ DgnInf: 7|64@0+ (1,0) [0|1.8446742e+19] "" FICM_HS PFAF_HS VCM_HS ARS_HS MCP_B_HS VLBS_HS EBCM_OBD_HS VITM_OBD_HS GPCM_HS MCP_A_HS MCP_HS TCCM_HS SAS_HS PTAM_HS HMIM_HS AMP_HS FDCM_HS VICM2_HS AHL_AFL_HS EPB_HS AFS_HS ICCM_HS HCP_HS BCP_HS ACCM_HS SADS_HS ICCM_OBD_HS FSCM_ITBC_HS FSCM_HS VICM_HS APPS_HS MCP_C_HS FCP_HS ONSTAR_HS EOCM_F_HS FCM_HS RDCM_HS PTO_HS HPCC_HS EBCM_HS ACC_HS ALC_HS DCDC_HS OBCM_HS Dummy_HS BCM_HS TCM_HS VES_HS EPS_HS PCM_HS ECM_HS

BO_ 2015 USDT_OBD_Functional_Request: 8 TestTool_HS
  SG_ DgnInf: 7|64@0+ (1,0) [0|1.8446742e+19] "" FICM_HS VICM_HS ICCM_OBD_HS FSCM_ITBC_HS FSCM_HS EBCM_OBD_HS VITM_OBD_HS GPCM_HS VICM2_HS HCP_HS BCP_HS TCM_HS PCM_HS ECM_HS

BO_ 2016 USDT_Req_to_ECM_HS: 8 TestTool_HS
  SG_ DgnInf: 7|64@0+ (1,0) [0|1.8446742e+19] "" PCM_HS ECM_HS

BO_ 197 PPEI_NonDrivn_Whl_Rotationl_Stat: 8 EBCM_HS
  SG_ WRSLNDWhlDisTpRC: 7|2@0+ (1,0) [0|3] "counts" PTO_HS HCP_HS ICCM_OBD_HS ICCM_HS HMIM_HS PTAM_HS AHL_AFL_HS FSCM_ITBC_HS BCP_HS VES_HS AFS_HS EPB_HS EPS_HS FCP_HS ONSTAR_HS RDCM_HS ACC_HS BCM_HS SADS_HS TCM_HS TCCM_HS PCM_HS ECM_HS
  SG_ WRSLNDWhlRotStRst: 3|1@0+ (1,0) [0|1] "" PTO_HS HCP_HS ICCM_OBD_HS ICCM_HS HMIM_HS PTAM_HS AHL_AFL_HS FSCM_ITBC_HS BCP_HS VES_HS AFS_HS EPB_HS EPS_HS FCP_HS ONSTAR_HS RDCM_HS ACC_HS BCM_HS SADS_HS TCM_HS TCCM_HS PCM_HS ECM_HS
  SG_ WRSLNDWhlDistVal: 2|1@0+ (1,0) [0|1] "" PTO_HS HCP_HS ICCM_OBD_HS ICCM_HS HMIM_HS PTAM_HS AHL_AFL_HS FSCM_ITBC_HS BCP_HS VES_HS AFS_HS EPB_HS EPS_HS FCP_HS ONSTAR_HS RDCM_HS ACC_HS BCM_HS SADS_HS TCM_HS TCCM_HS PCM_HS ECM_HS
  SG_ WRSLNDWhlDistTstm: 23|16@0+ (1,0) [0|65535] "counts" PTO_HS HCP_HS ICCM_OBD_HS ICCM_HS HMIM_HS PTAM_HS AHL_AFL_HS FSCM_ITBC_HS BCP_HS VES_HS AFS_HS EPB_HS EPS_HS FCP_HS ONSTAR_HS RDCM_HS ACC_HS BCM_HS SADS_HS TCM_HS TCCM_HS PCM_HS ECM_HS
  SG_ WRSLNDWhlDistPCntr: 1|10@0+ (1,0) [0|1023] "counts" PTO_HS HCP_HS ICCM_OBD_HS ICCM_HS HMIM_HS PTAM_HS AHL_AFL_HS FSCM_ITBC_HS BCP_HS VES_HS AFS_HS EPB_HS EPS_HS FCP_HS ONSTAR_HS RDCM_HS ACC_HS BCM_HS SADS_HS TCM_HS TCCM_HS PCM_HS ECM_HS
  SG_ WRSLNDSeqNum: 5|2@0+ (1,0) [0|3] "counts" PTO_HS HCP_HS ICCM_OBD_HS ICCM_HS HMIM_HS PTAM_HS AHL_AFL_HS FSCM_ITBC_HS BCP_HS VES_HS AFS_HS EPB_HS EPS_HS FCP_HS ONSTAR_HS RDCM_HS ACC_HS BCM_HS SADS_HS TCM_HS TCCM_HS PCM_HS ECM_HS
  SG_ WRSRNDWhlDisTpRC: 39|2@0+ (1,0) [0|3] "counts" PTO_HS HCP_HS ICCM_OBD_HS ICCM_HS HMIM_HS PTAM_HS AHL_AFL_HS FSCM_ITBC_HS BCP_HS VES_HS AFS_HS EPS_HS FCP_HS ONSTAR_HS RDCM_HS ACC_HS EPB_HS SADS_HS BCM_HS TCM_HS TCCM_HS PCM_HS ECM_HS
  SG_ WRSRNDWhlRotStRst: 35|1@0+ (1,0) [0|1] "" PTO_HS HCP_HS ICCM_OBD_HS ICCM_HS HMIM_HS PTAM_HS AHL_AFL_HS FSCM_ITBC_HS BCP_HS VES_HS AFS_HS EPS_HS FCP_HS ONSTAR_HS RDCM_HS ACC_HS EPB_HS SADS_HS BCM_HS TCM_HS TCCM_HS PCM_HS ECM_HS
  SG_ WRSRNDWhlDistVal: 34|1@0+ (1,0) [0|1] "" PTO_HS HCP_HS ICCM_OBD_HS ICCM_HS HMIM_HS PTAM_HS AHL_AFL_HS FSCM_ITBC_HS BCP_HS VES_HS AFS_HS EPS_HS FCP_HS ONSTAR_HS RDCM_HS ACC_HS EPB_HS SADS_HS BCM_HS TCM_HS TCCM_HS PCM_HS ECM_HS
  SG_ WRSRNDWhlDistTstm: 55|16@0+ (1,0) [0|65535] "counts" PTO_HS HCP_HS ICCM_OBD_HS ICCM_HS HMIM_HS PTAM_HS AHL_AFL_HS FSCM_ITBC_HS BCP_HS VES_HS AFS_HS EPS_HS FCP_HS ONSTAR_HS RDCM_HS ACC_HS EPB_HS SADS_HS BCM_HS TCM_HS TCCM_HS PCM_HS ECM_HS
  SG_ WRSRNDWhlDistPCntr: 33|10@0+ (1,0) [0|1023] "counts" PTO_HS HCP_HS ICCM_OBD_HS ICCM_HS HMIM_HS PTAM_HS AHL_AFL_HS FSCM_ITBC_HS BCP_HS VES_HS AFS_HS EPS_HS FCP_HS ONSTAR_HS RDCM_HS ACC_HS EPB_HS SADS_HS BCM_HS TCM_HS TCCM_HS PCM_HS ECM_HS
  SG_ WRSRNDSeqNum: 37|2@0+ (1,0) [0|3] "counts" PTO_HS HCP_HS ICCM_OBD_HS ICCM_HS HMIM_HS PTAM_HS AHL_AFL_HS FSCM_ITBC_HS BCP_HS VES_HS AFS_HS EPS_HS FCP_HS ONSTAR_HS RDCM_HS ACC_HS EPB_HS SADS_HS BCM_HS TCM_HS TCCM_HS PCM_HS ECM_HS

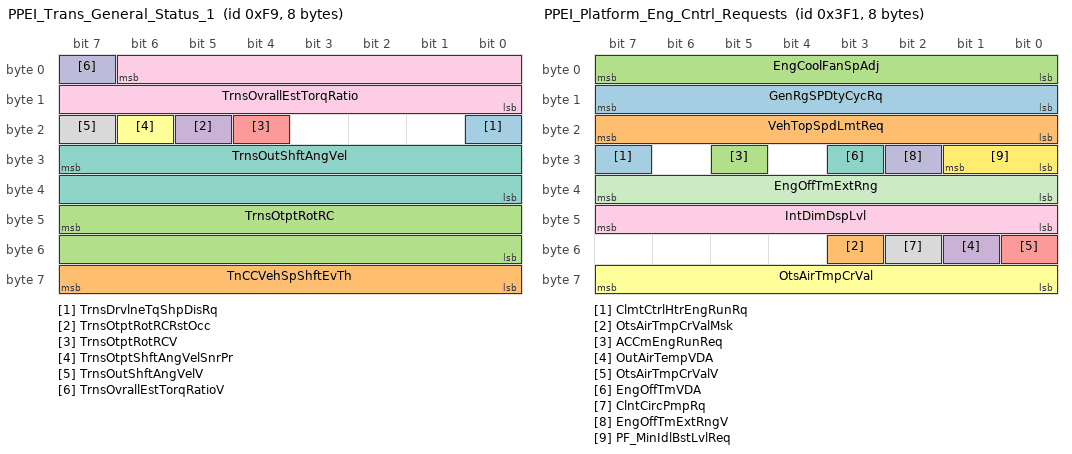
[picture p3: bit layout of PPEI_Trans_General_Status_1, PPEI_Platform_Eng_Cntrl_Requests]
BO_ 249 PPEI_Trans_General_Status_1: 8 ECM_HS
  SG_ TrnsDrvlneTqShpDisRq: 16|1@0+ (1,0) [0|1] "" PCM_HS ECM_HS
  SG_ TnCCVehSpShftEvTh: 63|8@0+ (2,0) [0|510] "km / h" PCM_HS ECM_HS
  SG_ TrnsOtptRotRC: 47|16@0+ (0.0078125,0) [0|511.99219] "rot" EBCM_OBD_HS EBCM_HS PCM_HS ECM_HS
  SG_ TrnsOtptRotRCRstOcc: 21|1@0+ (1,0) [0|1] "" EBCM_OBD_HS EBCM_HS PCM_HS ECM_HS
  SG_ TrnsOtptRotRCV: 20|1@0+ (1,0) [0|1] "" EBCM_OBD_HS EBCM_HS PCM_HS ECM_HS
  SG_ TrnsOtptShftAngVelSnrPr: 22|1@0+ (1,0) [0|1] "" TCCM_HS PCM_HS ECM_HS
  SG_ TrnsOutShftAngVel: 31|16@0+ (0.25,0) [0|16383.75] "rpm" EBCM_OBD_HS EBCM_HS TCCM_HS PCM_HS ECM_HS
  SG_ TrnsOutShftAngVelV: 23|1@0+ (1,0) [0|1] "" EBCM_OBD_HS EBCM_HS TCCM_HS PCM_HS ECM_HS
  SG_ TrnsOvrallEstTorqRatio: 6|15@0- (0.00390625,0) [-64|63.996098] "" TCCM_HS SADS_HS RDCM_HS EBCM_OBD_HS EBCM_HS PCM_HS ECM_HS
  SG_ TrnsOvrallEstTorqRatioV: 7|1@0+ (1,0) [0|1] "" TCCM_HS SADS_HS RDCM_HS EBCM_OBD_HS EBCM_HS PCM_HS ECM_HS

BO_ 1009 PPEI_Platform_Eng_Cntrl_Requests: 8 BCM_HS
  SG_ ClmtCtrlHtrEngRunRq: 31|1@0+ (1,0) [0|1] "" ECM_HS
  SG_ OtsAirTmpCrValMsk: 51|1@0+ (1,0) [0|1] "" ALC_HS EPS_HS ICCM_OBD_HS ICCM_HS RDCM_HS ECM_HS SADS_HS
  SG_ ACCmEngRunReq: 29|1@0+ (1,0) [0|1] "" ECM_HS BCP_HS
  SG_ OutAirTempVDA: 49|1@0+ (1,0) [0|1] "" SADS_HS ICCM_OBD_HS ICCM_HS RDCM_HS PCM_HS ECM_HS
  SG_ OtsAirTmpCrValV: 48|1@0+ (1,0) [0|1] "" ALC_HS EPS_HS VCM_HS ICCM_OBD_HS ICCM_HS RDCM_HS SADS_HS PCM_HS ECM_HS
  SG_ OtsAirTmpCrVal: 63|8@0+ (0.5,-40) [-40|87.5] "deg C" ALC_HS EPS_HS VCM_HS ICCM_OBD_HS ICCM_HS RDCM_HS PCM_HS ECM_HS SADS_HS
  SG_ EngOffTmVDA: 27|1@0+ (1,0) [0|1] "" EBCM_OBD_HS EBCM_HS ICCM_OBD_HS ICCM_HS ALC_HS SADS_HS VES_HS EPS_HS EPB_HS TCCM_HS
  SG_ ClntCircPmpRq: 50|1@0+ (1,0) [0|1] "" VICM_HS PCM_HS ECM_HS
  SG_ IntDimDspLvl: 47|8@0+ (0.39215702,0) [0|100.00004] "%" TCCM_HS
  SG_ EngOffTmExtRngV: 26|1@0+ (1,0) [0|1] "" ECM_HS ICCM_OBD_HS ICCM_HS ALC_HS VES_HS EPS_HS EPB_HS EBCM_OBD_HS EBCM_HS RDCM_HS SADS_HS TCCM_HS
  SG_ EngOffTmExtRng: 39|8@0+ (4,0) [0|1020] "min" ECM_HS ICCM_OBD_HS ICCM_HS ALC_HS VES_HS EPS_HS EPB_HS SADS_HS EBCM_OBD_HS EBCM_HS RDCM_HS TCCM_HS
  SG_ PF_MinIdlBstLvlReq: 25|2@0+ (1,0) [0|3] "" PCM_HS ECM_HS
  SG_ GenRgSPDtyCycRq: 15|8@0+ (0.39215702,0) [0|100.00004] "%" PCM_HS ECM_HS
  SG_ VehTopSpdLmtReq: 23|8@0+ (2,0) [0|510] "km / h" PTO_HS PCM_HS ECM_HS
  SG_ EngCoolFanSpAdj: 7|8@0- (0.78124994,0) [-100|99.218758] "%" PCM_HS ECM_HS

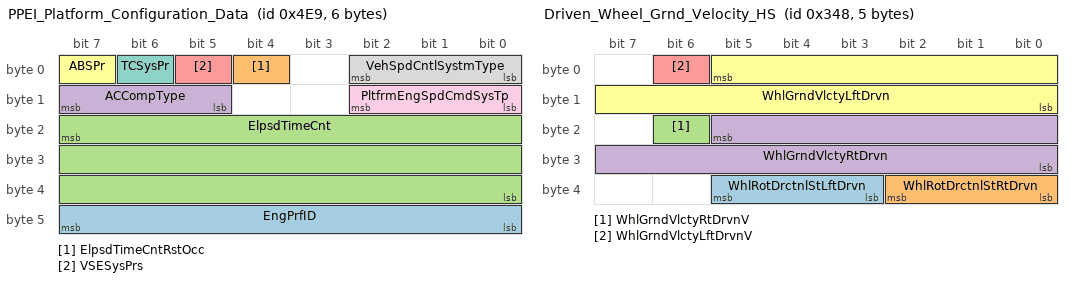
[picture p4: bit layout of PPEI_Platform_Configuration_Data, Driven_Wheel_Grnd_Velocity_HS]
BO_ 1257 PPEI_Platform_Configuration_Data: 6 BCM_HS
  SG_ EngPrfID: 47|8@0+ (2,0) [0|510] "kW" PCM_HS ECM_HS
  SG_ ElpsdTimeCntRstOcc: 4|1@0+ (1,0) [0|1] "" Vector__XXX
  SG_ ElpsdTimeCnt: 23|24@0+ (1,0) [0|16777215] "min" ECM_HS
  SG_ ACCompType: 15|3@0+ (1,0) [0|7] "" PCM_HS ECM_HS
  SG_ VSESysPrs: 5|1@0+ (1,0) [0|1] "" TCM_HS TCCM_HS PCM_HS ECM_HS
  SG_ ABSPr: 7|1@0+ (1,0) [0|1] "" TCM_HS TCCM_HS PCM_HS ECM_HS
  SG_ TCSysPr: 6|1@0+ (1,0) [0|1] "" TCM_HS TCCM_HS PCM_HS ECM_HS
  SG_ VehSpdCntlSystmType: 2|3@0+ (1,0) [0|7] "" PCM_HS ECM_HS
  SG_ PltfrmEngSpdCmdSysTp: 10|3@0+ (1,0) [0|7] "" PTO_HS TCM_HS PCM_HS ECM_HS

BO_ 505 PPEI_PTO_Command_Data: 8 PTO_HS
  SG_ AllNodesVNA_1F9: 43|1@0+ (1,0) [0|1] "" BCM_HS
  SG_ PTOVehTopSpdLimVal: 63|8@0+ (2,0) [0|510] "km / h" BCM_HS
  SG_ AccPdlPwrTkOffOvrAct: 4|1@0+ (1,0) [0|1] "" PCM_HS ECM_HS
  SG_ PTOTGRReqdGear: 35|4@0+ (1,0) [0|15] "" TCM_HS
  SG_ PTOTGRReqType: 37|2@0+ (1,0) [0|3] "" TCM_HS
  SG_ PTORmtEngStrtReq: 44|1@0+ (1,0) [0|1] "" BCM_HS
  SG_ TrnsPTOCltchRelRqd: 38|1@0+ (1,0) [0|1] "" TCM_HS
  SG_ FstIdlMdAct: 47|1@0+ (1,0) [0|1] "" PCM_HS ECM_HS
  SG_ PTOMdAct: 46|1@0+ (1,0) [0|1] "" PCM_HS ECM_HS
  SG_ PTOEngTrqLmtRchd: 45|1@0+ (1,0) [0|1] "" PCM_HS ECM_HS
  SG_ PTOEngTrqLmtValER: 55|8@0+ (8,0) [0|2040] "Nm" PCM_HS ECM_HS
  SG_ PltfrmEngSpdCmdMdAct: 3|1@0+ (1,0) [0|1] "" ACC_HS TCM_HS PCM_HS ECM_HS
  SG_ PltfrmEngSpdReq: 2|11@0+ (4,0) [0|8188] "rpm" ACC_HS TCM_HS PCM_HS ECM_HS
  SG_ PFESpdCmdOnSwAct: 7|1@0+ (1,0) [0|1] "" PCM_HS ECM_HS
  SG_ PFESpdCmdDeSwAct: 5|1@0+ (1,0) [0|1] "" PCM_HS ECM_HS
  SG_ PFESpdCmdInSwAct: 6|1@0+ (1,0) [0|1] "" PCM_HS ECM_HS
  SG_ PFESpdCmdSwDIntg: 21|2@0+ (1,0) [0|3] "" PCM_HS ECM_HS
  SG_ PFEngSpdCmdAlvRlgCnt: 23|2@0+ (1,0) [0|3] "" TCM_HS PCM_HS ECM_HS
  SG_ PltfrmEngSpdCmdProtVal: 19|12@0+ (1,0) [0|4095] "" PCM_HS ECM_HS
  SG_ PTORmtEngShtdwnReqd: 39|1@0+ (1,0) [0|1] "" BCM_HS PCM_HS ECM_HS

BO_ 497 PPEI_Platform_General_Status: 8 BCM_HS
  SG_ FuelFltLfRstRqd: 56|1@0+ (1,0) [0|1] "" TCCM_HS PCM_HS ECM_HS
  SG_ ACCompSysVDA: 9|1@0+ (1,0) [0|1] "" VCM_HS BCP_HS PCM_HS ECM_HS
  SG_ BkupPwrModeMstrVDA: 7|1@0+ (1,0) [0|1] "" HMIM_HS APPS_HS EBCM_OBD_HS EBCM_HS TCCM_HS
  SG_ PrkBrkVDA: 35|1@0+ (1,0) [0|1] "" RDCM_HS TCCM_HS
  SG_ PrkBrkVDM: 62|1@0+ (1,0) [0|1] "" Vector__XXX
  SG_ BkupPwrModeMstrVDM: 61|1@0+ (1,0) [0|1] "" Vector__XXX
  SG_ ACCompSysVDM: 60|1@0+ (1,0) [0|1] "" VCM_HS
  SG_ AirbgVDA: 57|1@0+ (1,0) [0|1] "" HMIM_HS PCM_HS ECM_HS AFS_HS ACC_HS TCCM_HS FSCM_ITBC_HS BCP_HS
  SG_ SysBkupPwrMdEn: 6|1@0+ (1,0) [0|1] "" PFAF_HS DCDC_HS ARS_HS ICCM_OBD_HS SAS_HS VLBS_HS EBCM_OBD_HS PTAM_HS HCP_HS FDCM_HS ICCM_HS EOCM_F_HS FSCM_ITBC_HS SCM_HS ITBC_HS VCM_HS HMIM_HS VES_HS MCP_C_HS RWS_HS EPS_HS BCP_HS ALC_HS AHL_AFL_HS SADS_HS FSCM_HS AFS_HS FCM_HS TCCM_HS RDCM_HS EBCM_HS ACC_HS TCM_HS ECM_HS APPS_HS EPB_HS
  SG_ SysBkUpPwrMd: 5|2@0+ (1,0) [0|3] "" PFAF_HS DCDC_HS ARS_HS ICCM_OBD_HS SAS_HS VLBS_HS EBCM_OBD_HS PTAM_HS HCP_HS FDCM_HS ICCM_HS EOCM_F_HS FSCM_ITBC_HS SCM_HS ITBC_HS VCM_HS HMIM_HS VES_HS MCP_C_HS RWS_HS EPS_HS BCP_HS ALC_HS AHL_AFL_HS SADS_HS FSCM_HS AFS_HS FCM_HS TCCM_HS RDCM_HS EBCM_HS ACC_HS TCM_HS ECM_HS APPS_HS EPB_HS
  SG_ SysPwrMd: 1|2@0+ (1,0) [0|3] "" VICM2_HS VICM_HS PFAF_HS DCDC_HS ARS_HS ICCM_OBD_HS SAS_HS VLBS_HS PTAM_HS HCP_HS FDCM_HS ICCM_HS EOCM_F_HS FSCM_ITBC_HS SCM_HS ITBC_HS VCM_HS HMIM_HS VES_HS MCP_C_HS RWS_HS EPS_HS BCP_HS ALC_HS AHL_AFL_HS SADS_HS FSCM_HS AFS_HS FCM_HS TCCM_HS RDCM_HS ACC_HS TCM_HS ECM_HS EBCM_OBD_HS EBCM_HS APPS_HS EPB_HS
  SG_ TrStLgMdAtv: 34|1@0+ (1,0) [0|1] "" PFAF_HS DCDC_HS VICM2_HS MCP_B_HS MCP_A_HS ICCM_OBD_HS SAS_HS ACCM_HS VLBS_HS VITM_OBD_HS PTAM_HS OBCM_HS VICM_HS FDCM_HS ICCM_HS EOCM_F_HS FSCM_ITBC_HS SCM_HS ITBC_HS VCM_HS HMIM_HS VES_HS MCP_C_HS RWS_HS EPS_HS MCP_HS ALC_HS AHL_AFL_HS SADS_HS EPB_HS FSCM_HS AFS_HS FCM_HS TCCM_HS RDCM_HS PTO_HS PCM_HS ACC_HS TCM_HS ECM_HS EBCM_OBD_HS EBCM_HS
  SG_ DispMeasSys: 59|1@0+ (1,0) [0|1] "" TCCM_HS ACC_HS PCM_HS ECM_HS
  SG_ ACCmpsrFldOn: 63|1@0+ (1,0) [0|1] "" TCCM_HS PCM_HS ECM_HS
  SG_ ACCompModReq: 12|2@0+ (1,0) [0|3] "" TCCM_HS PCM_HS ECM_HS
  SG_ ACCompNormLd: 55|8@0+ (0.1,0) [0|25.5] "l/min" TCCM_HS BCP_HS PCM_HS ECM_HS
  SG_ ACCompNormLdV: 10|1@0+ (1,0) [0|1] "" TCCM_HS BCP_HS PCM_HS ECM_HS
  SG_ PTORSMstrEngShtReq: 13|1@0+ (1,0) [0|1] "" TCCM_HS PTO_HS PCM_HS ECM_HS
  SG_ EngOilLfRstRq: 37|1@0+ (1,0) [0|1] "" TCCM_HS PCM_HS ECM_HS
  SG_ SIRDpl: 58|1@0+ (1,0) [0|1] "" HMIM_HS FSCM_ITBC_HS TCCM_HS BCP_HS ACC_HS AFS_HS PCM_HS ECM_HS
  SG_ PTORmStMsEngStRq: 14|1@0+ (1,0) [0|1] "" PTO_HS TCM_HS TCCM_HS PCM_HS ECM_HS
  SG_ RmVehStrRq: 15|1@0+ (1,0) [0|1] "" BCP_HS VICM_HS HCP_HS APPS_HS EPB_HS TCCM_HS PCM_HS ECM_HS
  SG_ ThrtlPrgrsnReq: 39|2@0+ (1,0) [0|3] "" TCCM_HS PCM_HS ECM_HS
  SG_ PrkBrkSwAtv: 36|1@0+ (1,0) [0|1] "" PTO_HS ICCM_OBD_HS ICCM_HS EOCM_F_HS RDCM_HS ACC_HS EBCM_OBD_HS EBCM_HS TCCM_HS PCM_HS ECM_HS
  SG_ PMMAccTrmSt: 2|1@0+ (1,0) [0|1] "" TCM_HS TCCM_HS PCM_HS ECM_HS
  SG_ PMMRunCrkTrmSt: 3|1@0+ (1,0) [0|1] "" TCM_HS TCCM_HS PCM_HS ECM_HS
  SG_ ImmblzrPreRelPswdStat: 8|1@0+ (1,0) [0|1] "" HCP_HS TCCM_HS PCM_HS ECM_HS
  SG_ ImmblzrPreRelPswrd: 23|16@0+ (1,0) [0|65535] "passwrd" HCP_HS TCCM_HS PCM_HS ECM_HS

BO_ 969 PPEI_Platform_Immobilizer_Data: 8 BCM_HS
  SG_ ImoInf: 7|64@0+ (1,0) [0|1.8446742e+19] "" HCP_HS PCM_HS ECM_HS

BO_ 1249 PPEI_VIN_Digits_10_to_17: 8 BCM_HS
  SG_ VehIdNmDig10_17: 7|64@0+ (1,0) [0|1] "" EBCM_OBD_HS EBCM_HS VES_HS EPS_HS VLBS_HS BCP_HS ACC_HS EPB_HS AFS_HS RDCM_HS TCCM_HS TCM_HS PCM_HS ECM_HS

BO_ 2024 USDT_Resp_From_ECM_HS: 8 ECM_HS
  SG_ DgnInf: 7|64@0+ (1,0) [0|1.8446742e+19] "" FCP_HS ONSTAR_HS TestTool_HS

BO_ 1512 UUDT_Resp_From_ECM: 8 ECM_HS
  SG_ DgnInf: 7|64@0+ (1,0) [0|1.8446742e+19] "" FCP_HS ONSTAR_HS TestTool_HS

BO_ 840 Driven_Wheel_Grnd_Velocity_HS: 5 EBCM_HS
  SG_ WhlRotDrctnlStLftDrvn: 37|3@0+ (1,0) [0|7] "" VICM_HS EDI_HS EOCM_F_HS HMIM_HS
  SG_ WhlRotDrctnlStRtDrvn: 34|3@0+ (1,0) [0|7] "" VICM_HS EDI_HS EOCM_F_HS HMIM_HS
  SG_ WhlGrndVlctyRtDrvnV: 22|1@0+ (1,0) [0|1] "" EDI_HS HMIM_HS TCCM_HS ARS_HS FCM_HS APPS_HS EOCM_F_HS EPB_HS BCM_HS RDCM_HS ACC_HS AFS_HS VES_HS EPS_HS SADS_HS
  SG_ WhlGrndVlctyRtDrvn: 21|14@0+ (0.03125,0) [0|511.96875] "km / h" EDI_HS HMIM_HS TCCM_HS ARS_HS FCM_HS APPS_HS EOCM_F_HS BCM_HS RDCM_HS ACC_HS EPB_HS AFS_HS VES_HS EPS_HS SADS_HS
  SG_ WhlGrndVlctyLftDrvnV: 6|1@0+ (1,0) [0|1] "" EDI_HS HMIM_HS TCCM_HS ARS_HS FCM_HS APPS_HS EOCM_F_HS EPB_HS BCM_HS RDCM_HS ACC_HS VES_HS EPS_HS AFS_HS SADS_HS
  SG_ WhlGrndVlctyLftDrvn: 5|14@0+ (0.03125,0) [0|511.96875] "km / h" EDI_HS HMIM_HS TCCM_HS ARS_HS FCM_HS APPS_HS EOCM_F_HS BCM_HS RDCM_HS ACC_HS EPB_HS VES_HS EPS_HS AFS_HS SADS_HS

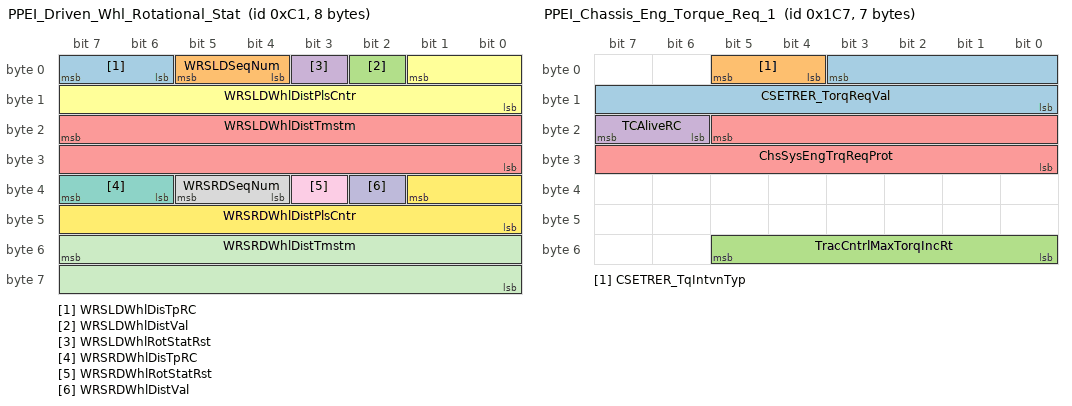
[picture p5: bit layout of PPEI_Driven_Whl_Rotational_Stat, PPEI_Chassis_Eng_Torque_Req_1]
BO_ 193 PPEI_Driven_Whl_Rotational_Stat: 8 EBCM_HS
  SG_ WRSLDWhlDisTpRC: 7|2@0+ (1,0) [0|3] "counts" PTO_HS HCP_HS ICCM_OBD_HS ICCM_HS HMIM_HS PTAM_HS FSCM_ITBC_HS BCP_HS VES_HS AFS_HS EPB_HS EPS_HS FCP_HS ONSTAR_HS RDCM_HS ACC_HS BCM_HS SADS_HS TCM_HS TCCM_HS PCM_HS ECM_HS
  SG_ WRSLDSeqNum: 5|2@0+ (1,0) [0|3] "counts" PTO_HS HCP_HS ICCM_OBD_HS ICCM_HS HMIM_HS PTAM_HS FSCM_ITBC_HS BCP_HS VES_HS AFS_HS EPB_HS EPS_HS FCP_HS ONSTAR_HS RDCM_HS ACC_HS BCM_HS SADS_HS TCM_HS TCCM_HS PCM_HS ECM_HS
  SG_ WRSLDWhlDistVal: 2|1@0+ (1,0) [0|1] "" PTO_HS HCP_HS ICCM_OBD_HS ICCM_HS HMIM_HS PTAM_HS FSCM_ITBC_HS BCP_HS VES_HS AFS_HS EPB_HS EPS_HS FCP_HS ONSTAR_HS RDCM_HS ACC_HS BCM_HS SADS_HS TCM_HS TCCM_HS PCM_HS ECM_HS
  SG_ WRSLDWhlRotStatRst: 3|1@0+ (1,0) [0|1] "" PTO_HS HCP_HS ICCM_OBD_HS ICCM_HS HMIM_HS PTAM_HS FSCM_ITBC_HS BCP_HS VES_HS AFS_HS EPB_HS EPS_HS FCP_HS ONSTAR_HS RDCM_HS ACC_HS BCM_HS SADS_HS TCM_HS TCCM_HS PCM_HS ECM_HS
  SG_ WRSLDWhlDistTmstm: 23|16@0+ (1,0) [0|65535] "counts" PTO_HS HCP_HS ICCM_OBD_HS ICCM_HS HMIM_HS PTAM_HS FSCM_ITBC_HS BCP_HS VES_HS AFS_HS EPB_HS EPS_HS FCP_HS ONSTAR_HS RDCM_HS ACC_HS BCM_HS SADS_HS TCM_HS TCCM_HS PCM_HS ECM_HS
  SG_ WRSLDWhlDistPlsCntr: 1|10@0+ (1,0) [0|1023] "counts" PTO_HS HCP_HS ICCM_OBD_HS ICCM_HS HMIM_HS PTAM_HS FSCM_ITBC_HS BCP_HS VES_HS AFS_HS EPB_HS EPS_HS FCP_HS ONSTAR_HS RDCM_HS ACC_HS BCM_HS SADS_HS TCM_HS TCCM_HS PCM_HS ECM_HS
  SG_ WRSRDWhlDisTpRC: 39|2@0+ (1,0) [0|3] "counts" PTO_HS HCP_HS ICCM_OBD_HS ICCM_HS HMIM_HS PTAM_HS FSCM_ITBC_HS BCP_HS VES_HS AFS_HS EPS_HS FCP_HS ONSTAR_HS RDCM_HS ACC_HS EPB_HS BCM_HS SADS_HS TCM_HS TCCM_HS PCM_HS ECM_HS
  SG_ WRSRDSeqNum: 37|2@0+ (1,0) [0|3] "counts" PTO_HS HCP_HS ICCM_OBD_HS ICCM_HS HMIM_HS PTAM_HS FSCM_ITBC_HS BCP_HS VES_HS AFS_HS EPS_HS FCP_HS ONSTAR_HS RDCM_HS ACC_HS EPB_HS BCM_HS SADS_HS TCM_HS TCCM_HS PCM_HS ECM_HS
  SG_ WRSRDWhlRotStatRst: 35|1@0+ (1,0) [0|1] "" PTO_HS HCP_HS ICCM_OBD_HS ICCM_HS HMIM_HS PTAM_HS FSCM_ITBC_HS BCP_HS VES_HS AFS_HS EPS_HS FCP_HS ONSTAR_HS RDCM_HS ACC_HS EPB_HS BCM_HS SADS_HS TCM_HS TCCM_HS PCM_HS ECM_HS
  SG_ WRSRDWhlDistVal: 34|1@0+ (1,0) [0|1] "" PTO_HS HCP_HS ICCM_OBD_HS ICCM_HS HMIM_HS PTAM_HS FSCM_ITBC_HS BCP_HS VES_HS AFS_HS EPS_HS FCP_HS ONSTAR_HS RDCM_HS ACC_HS EPB_HS BCM_HS SADS_HS TCM_HS TCCM_HS PCM_HS ECM_HS
  SG_ WRSRDWhlDistTmstm: 55|16@0+ (1,0) [0|65535] "counts" PTO_HS HCP_HS ICCM_OBD_HS ICCM_HS HMIM_HS PTAM_HS FSCM_ITBC_HS BCP_HS VES_HS AFS_HS EPS_HS FCP_HS ONSTAR_HS RDCM_HS ACC_HS EPB_HS BCM_HS SADS_HS TCM_HS TCCM_HS PCM_HS ECM_HS
  SG_ WRSRDWhlDistPlsCntr: 33|10@0+ (1,0) [0|1023] "counts" PTO_HS HCP_HS ICCM_OBD_HS ICCM_HS HMIM_HS PTAM_HS FSCM_ITBC_HS BCP_HS VES_HS AFS_HS EPS_HS FCP_HS ONSTAR_HS RDCM_HS ACC_HS EPB_HS BCM_HS SADS_HS TCM_HS TCCM_HS PCM_HS ECM_HS

BO_ 481 PPEI_Cruise_Control_Sw_Status: 7 BCM_HS
  SG_ CrsSecSwStatPVal: 51|4@0+ (1,0) [0|15] "" ECM_HS EOCM_F_HS ACC_HS PTO_HS
  SG_ CrsSecSwStatARC: 41|2@0+ (1,0) [0|3] "" ECM_HS EOCM_F_HS ACC_HS PTO_HS
  SG_ CrsSecSwStat: 27|4@0+ (1,0) [0|15] "" ECM_HS EOCM_F_HS ACC_HS PTO_HS
  SG_ DrvSelMdSw3Sta: 37|1@0+ (1,0) [0|1] "" ECM_HS
  SG_ DrvSelMdSw2Sta: 38|1@0+ (1,0) [0|1] "" ECM_HS
  SG_ AuxHtrRq: 31|1@0+ (1,0) [0|1] "" PCM_HS ECM_HS
  SG_ AuxHtrAtv: 30|1@0+ (1,0) [0|1] "" PCM_HS ECM_HS
  SG_ DrvSelMdSwStaARC: 33|2@0+ (1,0) [0|3] "" PCM_HS ECM_HS
  SG_ DrvSelMdSw1Sta: 39|1@0+ (1,0) [0|1] "" PCM_HS ECM_HS
  SG_ CrsSpdLmtrSwStatPVal: 55|4@0+ (1,0) [0|15] "" PTO_HS EOCM_F_HS PCM_HS ECM_HS ACC_HS
  SG_ CrsSpdLmtrSwStatARC: 43|2@0+ (1,0) [0|3] "" PTO_HS EOCM_F_HS PCM_HS ECM_HS ACC_HS
  SG_ FuelMdSwActV: 29|1@0+ (1,0) [0|1] "" FICM_HS PCM_HS ECM_HS
  SG_ FuelMdSwAct: 28|1@0+ (1,0) [0|1] "" FICM_HS PCM_HS ECM_HS
  SG_ CrsSpdLmtrSwStat: 47|4@0+ (1,0) [0|15] "" PTO_HS EOCM_F_HS PCM_HS ECM_HS ACC_HS
  SG_ AdptCrsGapSwAct: 23|2@0+ (1,0) [0|3] "" EOCM_F_HS ACC_HS
  SG_ CrsCntrlSwStCanSwAct: 7|1@0+ (1,0) [0|1] "" EOCM_F_HS ACC_HS PCM_HS ECM_HS
  SG_ CrsCntrlSwStSwDataIntgty: 1|2@0+ (1,0) [0|3] "" EOCM_F_HS ACC_HS PCM_HS ECM_HS
  SG_ CrsCntrlSwStSpdInSwAct: 3|1@0+ (1,0) [0|1] "" EOCM_F_HS ACC_HS PCM_HS ECM_HS
  SG_ CrsCntrlSwStSpDcSwAct: 2|1@0+ (1,0) [0|1] "" EOCM_F_HS ACC_HS PCM_HS ECM_HS
  SG_ CrsCntrlSwStSetSwAct: 4|1@0+ (1,0) [0|1] "" EOCM_F_HS ACC_HS PCM_HS ECM_HS
  SG_ CrsCntrlSwStResSwAct: 5|1@0+ (1,0) [0|1] "" EOCM_F_HS ACC_HS PCM_HS ECM_HS
  SG_ CrsCntrlSwStOnSwAct: 6|1@0+ (1,0) [0|1] "" EOCM_F_HS ACC_HS PCM_HS ECM_HS
  SG_ CrsCntrlSwStatProtValue: 15|8@0+ (1,0) [0|255] "" EOCM_F_HS ACC_HS PCM_HS ECM_HS
  SG_ CrsCntrlSwStAlvRollCnt: 17|2@0+ (1,0) [0|3] "" EOCM_F_HS ACC_HS PCM_HS ECM_HS
  SG_ CrsCntCncRq: 18|1@0+ (1,0) [0|1] "" PCM_HS ECM_HS

BO_ 455 PPEI_Chassis_Eng_Torque_Req_1: 7 EBCM_HS
  SG_ CSETRER_TorqReqVal: 3|12@0+ (0.5,-848) [-848|1199.5] "Nm" ICCM_OBD_HS ICCM_HS EOCM_F_HS ACC_HS PCM_HS ECM_HS
  SG_ CSETRER_TqIntvnTyp: 5|2@0+ (1,0) [0|3] "" ICCM_OBD_HS ICCM_HS EOCM_F_HS ACC_HS PCM_HS ECM_HS
  SG_ TracCntrlMaxTorqIncRt: 53|6@0+ (16,0) [0|1008] "Nm/s" PCM_HS ECM_HS
  SG_ TCAliveRC: 23|2@0+ (1,0) [0|3] "" PCM_HS ECM_HS
  SG_ ChsSysEngTrqReqProt: 21|14@0+ (1,0) [0|16383] "" PCM_HS ECM_HS

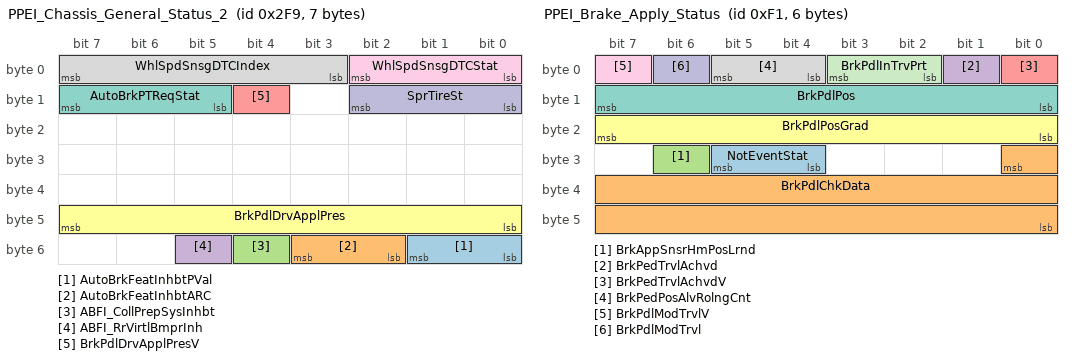
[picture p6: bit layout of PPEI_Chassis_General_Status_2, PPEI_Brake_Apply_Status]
BO_ 761 PPEI_Chassis_General_Status_2: 7 EBCM_HS
  SG_ AutoBrkFeatInhbtPVal: 49|2@0+ (1,0) [0|3] "" ECM_HS
  SG_ AutoBrkFeatInhbtARC: 51|2@0+ (1,0) [0|3] "" ECM_HS
  SG_ ABFI_CollPrepSysInhbt: 52|1@0+ (1,0) [0|1] "" PCM_HS ECM_HS
  SG_ ABFI_RrVirtlBmprInh: 53|1@0+ (1,0) [0|1] "" PCM_HS ECM_HS
  SG_ BrkPdlDrvApplPresV: 12|1@0+ (1,0) [0|1] "" ICCM_OBD_HS ICCM_HS BCP_HS PCM_HS ECM_HS TCCM_HS TCM_HS VES_HS EPS_HS
  SG_ BrkPdlDrvApplPres: 47|8@0+ (75,0) [0|19125] "kPa" ICCM_OBD_HS ICCM_HS BCP_HS PCM_HS ECM_HS TCCM_HS TCM_HS VES_HS EPS_HS
  SG_ AutoBrkPTReqStat: 15|3@0+ (1,0) [0|7] "" ECM_HS
  SG_ WhlSpdSnsgDTCIndex: 7|5@0+ (1,0) [0|31] "" PCM_HS ECM_HS
  SG_ WhlSpdSnsgDTCStat: 2|3@0+ (1,0) [0|7] "" PCM_HS ECM_HS
  SG_ SprTireSt: 10|3@0+ (1,0) [0|7] "" ICCM_OBD_HS ICCM_HS ARS_HS VES_HS EPS_HS BCM_HS RDCM_HS TCCM_HS

BO_ 489 PPEI_Chassis_General_Status_1: 8 EBCM_HS
  SG_ EnhDrvMdSwChUseRq: 53|1@0+ (1,0) [0|1] "" ECM_HS
  SG_ IMUDataMsk: 25|1@0+ (1,0) [0|1] "" FCP_HS ONSTAR_HS
  SG_ DrvIndpntBrkAppAct: 55|1@0+ (1,0) [0|1] "" RDCM_HS TCM_HS PCM_HS ECM_HS
  SG_ WhlSlpSt: 52|2@0+ (1,0) [0|3] "" PCM_HS ECM_HS TCM_HS
  SG_ BSTGRReqdGear: 19|4@0+ (1,0) [0|15] "" TCM_HS
  SG_ BSTGRReqType: 21|2@0+ (1,0) [0|3] "" TCM_HS
  SG_ VehDynOvrUndrStr: 49|10@0- (0.5,0) [-256|255.5] "%" EPS_HS RDCM_HS TCCM_HS
  SG_ VSELatAccV: 4|1@0+ (1,0) [0|1] "" EDI_HS FCM_HS EPS_HS ICCM_OBD_HS ICCM_HS ALC_HS SADS_HS RDCM_HS BCM_HS ACC_HS EPB_HS TCM_HS TCCM_HS PCM_HS ECM_HS
  SG_ VSELatAcc: 3|12@0- (0.015625,0) [-32|31.984375] "m/s^2" EDI_HS FCM_HS EPS_HS ICCM_OBD_HS ICCM_HS ALC_HS SADS_HS BCM_HS RDCM_HS ACC_HS EPB_HS TCM_HS TCCM_HS PCM_HS ECM_HS
  SG_ VSEAct: 24|1@0+ (1,0) [0|1] "" LVMPC_HS ICCM_OBD_HS ICCM_HS ARS_HS EOCM_F_HS VES_HS BCM_HS EPB_HS RDCM_HS EPS_HS ACC_HS TCCM_HS PCM_HS ECM_HS
  SG_ VhDynCntlSysSt: 39|3@0+ (1,0) [0|7] "" HMIM_HS ARS_HS VES_HS ECM_HS AFS_HS EPB_HS EPS_HS ACC_HS TCCM_HS
  SG_ VehDynYawRateV: 36|1@0+ (1,0) [0|1] "" ICCM_OBD_HS ICCM_HS EDI_HS FCM_HS HMIM_HS RDCM_HS BCM_HS VES_HS EPS_HS FCP_HS ONSTAR_HS AHL_AFL_HS ACC_HS TCCM_HS
  SG_ VehDynYawRate: 35|12@0- (0.0625,0) [-128|127.93751] "deg/sec" ICCM_OBD_HS ICCM_HS EDI_HS FCM_HS HMIM_HS RDCM_HS BCM_HS VES_HS EPS_HS AHL_AFL_HS FCP_HS ONSTAR_HS ACC_HS TCCM_HS
  SG_ TrnsBrkSysCltchRelRqd: 5|1@0+ (1,0) [0|1] "" TCCM_HS TCM_HS
  SG_ TracCntrlSysDrIntnt: 26|1@0+ (1,0) [0|1] "" PCM_HS ECM_HS
  SG_ VehDynOvrUndrStrV: 50|1@0+ (1,0) [0|1] "" EPS_HS RDCM_HS TCCM_HS
  SG_ TCSysEnbld: 27|1@0+ (1,0) [0|1] "" EOCM_F_HS ACC_HS BCP_HS VES_HS EPS_HS TCM_HS PCM_HS ECM_HS
  SG_ TCSysAtv: 28|1@0+ (1,0) [0|1] "" LVMPC_HS EDI_HS PTO_HS TCCM_HS EOCM_F_HS VES_HS RDCM_HS EPB_HS EPS_HS ACC_HS BCM_HS TCM_HS PCM_HS ECM_HS
  SG_ BrkPdlDrvAppPrsDetcdV: 7|1@0+ (1,0) [0|1] "" EOCM_F_HS ACC_HS VES_HS EPS_HS RDCM_HS TCM_HS TCCM_HS PCM_HS ECM_HS
  SG_ BrkPdlDrvAppPrsDetcd: 6|1@0+ (1,0) [0|1] "" EOCM_F_HS ACC_HS VES_HS EPS_HS RDCM_HS TCM_HS TCCM_HS PCM_HS ECM_HS
  SG_ ACCBrkngAct: 31|1@0+ (1,0) [0|1] "" EOCM_F_HS ACC_HS TCM_HS PCM_HS ECM_HS
  SG_ ABSFld: 29|1@0+ (1,0) [0|1] "" ICCM_OBD_HS ICCM_HS ARS_HS EOCM_F_HS ACC_HS VES_HS EPS_HS EPB_HS AFS_HS TCM_HS PCM_HS ECM_HS
  SG_ ABSAtv: 30|1@0+ (1,0) [0|1] "" LVMPC_HS EDI_HS ICCM_OBD_HS ICCM_HS ARS_HS EOCM_F_HS APPS_HS FSCM_ITBC_HS SADS_HS VES_HS RDCM_HS AFS_HS EPB_HS EPS_HS ACC_HS BCM_HS TCM_HS TCCM_HS PCM_HS ECM_HS

BO_ 381 Antilock_Brake_and_TC_Status_HS: 6 EBCM_HS
  SG_ HillDesCtrlRedVehSpIO: 39|1@0+ (1,0) [0|1] "" BCM_HS
  SG_ EBDFailed: 23|1@0+ (1,0) [0|1] "" BCM_HS
  SG_ StWhAnVDA: 17|1@0+ (1,0) [0|1] "" HMIM_HS RDCM_HS FCP_HS ONSTAR_HS ACC_HS AHL_AFL_HS EPB_HS BCM_HS
  SG_ TirePrsLowIO: 9|1@0+ (1,0) [0|1] "" BCM_HS
  SG_ VaccBoostFailure: 16|1@0+ (1,0) [0|1] "" BCM_HS
  SG_ VSESysPrs: 1|1@0+ (1,0) [0|1] "" EPB_HS BCM_HS
  SG_ HalfSysFail: 18|1@0+ (1,0) [0|1] "" BCM_HS
  SG_ ActVehAccel: 35|12@0- (0.010000001,0) [-20.48|20.469999] "m/s^2" VICM_HS BCP_HS BCM_HS EOCM_F_HS ACC_HS AHL_AFL_HS EPB_HS
  SG_ ActVehAccelV: 20|1@0+ (1,0) [0|1] "" VICM_HS BCP_HS BCM_HS EOCM_F_HS ACC_HS AHL_AFL_HS EPB_HS
  SG_ BksOvht: 8|1@0+ (1,0) [0|1] "" EOCM_F_HS BCM_HS ACC_HS
  SG_ TCSysPr: 10|1@0+ (1,0) [0|1] "" EPB_HS BCM_HS
  SG_ ABSPr: 22|1@0+ (1,0) [0|1] "" BCP_HS APPS_HS BCM_HS EPB_HS
  SG_ TreInfMonSysRstPrfmd: 11|1@0+ (1,0) [0|1] "" BCM_HS
  SG_ ABSIO: 12|1@0+ (1,0) [0|1] "" FCM_HS EOCM_F_HS BCM_HS
  SG_ BrkPadWrnIO: 0|1@0+ (1,0) [0|1] "" BCM_HS
  SG_ VehStabEnhmntMd: 15|3@0+ (1,0) [0|7] "" EDI_HS ICCM_OBD_HS ICCM_HS FSCM_HS SADS_HS PTAM_HS ACC_HS EOCM_F_HS TCCM_HS RDCM_HS BCM_HS
  SG_ VehStabEnhmntStat: 4|3@0+ (1,0) [0|7] "" EDI_HS FCM_HS FCP_HS ONSTAR_HS PTAM_HS ACC_HS EOCM_F_HS AFS_HS BCM_HS EPB_HS
  SG_ TCSysOpMd: 7|3@0+ (1,0) [0|7] "" EDI_HS SADS_HS PTAM_HS ACC_HS EOCM_F_HS TCCM_HS RDCM_HS BCM_HS
  SG_ TCSysOpStat: 38|3@0+ (1,0) [0|7] "" EDI_HS SADS_HS FCP_HS ONSTAR_HS PTAM_HS ACC_HS EOCM_F_HS EPB_HS BCM_HS
  SG_ BrkSysVTopSpdLimVal: 31|8@0+ (2,0) [0|510] "km / h" BCM_HS
  SG_ BrkSysRedBrkTlltlReq: 19|1@0+ (1,0) [0|1] "" FCP_HS ONSTAR_HS BCM_HS
  SG_ BrkSysBrkLtsReqd: 21|1@0+ (1,0) [0|1] "" AHL_AFL_HS BCM_HS

BO_ 241 PPEI_Brake_Apply_Status: 6 BCM_HS
  SG_ NotEventStat: 29|2@0+ (1,0) [0|3] "" EBCM_OBD_HS EBCM_HS ECM_HS VES_HS EPS_HS
  SG_ BrkPdlChkData: 24|17@0+ (1,0) [0|131071] "" EOCM_F_HS ACC_HS
  SG_ BrkAppSnsrHmPosLrnd: 30|1@0+ (1,0) [0|1] "" EOCM_F_HS ACC_HS PCM_HS ECM_HS VES_HS EPS_HS EBCM_OBD_HS EBCM_HS
  SG_ BrkPedTrvlAchvd: 1|1@0+ (1,0) [0|1] "" PTO_HS VICM_HS BCP_HS APPS_HS VES_HS EPS_HS EOCM_F_HS FSCM_ITBC_HS ICCM_OBD_HS ICCM_HS ALC_HS EPB_HS ACC_HS RDCM_HS SADS_HS EBCM_OBD_HS EBCM_HS TCM_HS TCCM_HS PCM_HS ECM_HS
  SG_ BrkPedTrvlAchvdV: 0|1@0+ (1,0) [0|1] "" PTO_HS VICM_HS BCP_HS APPS_HS VES_HS EPS_HS EOCM_F_HS FSCM_ITBC_HS ICCM_OBD_HS ICCM_HS ALC_HS EPB_HS ACC_HS RDCM_HS SADS_HS EBCM_OBD_HS EBCM_HS TCM_HS TCCM_HS PCM_HS ECM_HS
  SG_ BrkPdlPosGrad: 23|8@0- (40,0) [-5120|5080] "%/s" ACC_HS VES_HS EPS_HS EOCM_F_HS SADS_HS EBCM_OBD_HS EBCM_HS
  SG_ BrkPdlPos: 15|8@0+ (0.39215702,0) [0|100.00004] "% full" EDI_HS LVMPC_HS TCCM_HS ACC_HS EOCM_F_HS TCM_HS SADS_HS VES_HS EPS_HS EPB_HS EBCM_OBD_HS EBCM_HS
  SG_ BrkPedPosAlvRolngCnt: 5|2@0+ (1,0) [0|3] "" PTO_HS TCCM_HS RDCM_HS VES_HS EPS_HS EOCM_F_HS FSCM_ITBC_HS EPB_HS ACC_HS EBCM_OBD_HS EBCM_HS TCM_HS PCM_HS ECM_HS
  SG_ BrkPdlModTrvlV: 7|1@0+ (1,0) [0|1] "" SADS_HS EBCM_OBD_HS EBCM_HS ACC_HS EOCM_F_HS EPB_HS TCCM_HS VES_HS EPS_HS TCM_HS PCM_HS ECM_HS
  SG_ BrkPdlModTrvl: 6|1@0+ (1,0) [0|1] "" EBCM_OBD_HS EBCM_HS SADS_HS ACC_HS EOCM_F_HS EPB_HS TCCM_HS VES_HS EPS_HS TCM_HS PCM_HS ECM_HS
  SG_ BrkPdlInTrvPrt: 3|2@0+ (1,0) [0|3] "" PTO_HS EOCM_F_HS FSCM_ITBC_HS ICCM_OBD_HS ICCM_HS ALC_HS RDCM_HS ACC_HS VES_HS EPS_HS SADS_HS EBCM_OBD_HS EBCM_HS EPB_HS TCM_HS TCCM_HS PCM_HS ECM_HS

BO_ 2025 USDT_Resp_From_BCP_HS: 8 BCP_HS
  SG_ DgnInf: 7|64@0+ (1,0) [0|1.8446742e+19] "" FCP_HS ONSTAR_HS TestTool_HS

BO_ 2029 USDT_Resp_From_OBD_Device5: 8 EBCM_OBD_HS
  SG_ DgnInf: 7|64@0+ (1,0) [0|1.8446742e+19] "" FCP_HS ONSTAR_HS TestTool_HS

BO_ 2031 USDT_Resp_From_VITM_HS: 8 VITM_OBD_HS
  SG_ DgnInf: 7|64@0+ (1,0) [0|1.8446742e+19] "" FCP_HS ONSTAR_HS TestTool_HS

BO_ 1513 UUDT_Resp_From_BCP_HS: 8 BCP_HS
  SG_ DgnInf: 7|64@0+ (1,0) [0|1.8446742e+19] "" FCP_HS ONSTAR_HS TestTool_HS

BO_ 1517 UUDT_Resp_From_OBD_Device5: 8 EBCM_OBD_HS
  SG_ DgnInf: 7|64@0+ (1,0) [0|1.8446742e+19] "" FCP_HS ONSTAR_HS TestTool_HS

BO_ 1519 UUDT_Resp_From_VITM_HS: 8 VITM_OBD_HS
  SG_ DgnInf: 7|64@0+ (1,0) [0|1.8446742e+19] "" FCP_HS ONSTAR_HS TestTool_HS

BO_ 2030 USDT_Resp_From_OBD_Device6: 8 GPCM_HS
  SG_ DgnInf: 7|64@0+ (1,0) [0|1.8446742e+19] "" FCP_HS ONSTAR_HS TestTool_HS

BO_ 1518 UUDT_Resp_From_OBD_Device6: 8 GPCM_HS
  SG_ DgnInf: 7|64@0+ (1,0) [0|1.8446742e+19] "" FCP_HS ONSTAR_HS TestTool_HS

BO_ 1346 UUDT_Resp_From_EHPS_EPS_HS: 8 EPS_HS
  SG_ DgnInf_HS542: 7|64@0+ (1,0) [0|1.8446742e+19] "" FCP_HS ONSTAR_HS TestTool_HS

BO_ 1353 UUDT_Resp_From_AHL_AFL_HS: 8 AHL_AFL_HS
  SG_ DgnInf_HS549: 7|64@0+ (1,0) [0|1.8446742e+19] "" FCP_HS ONSTAR_HS TestTool_HS

BO_ 1609 USDT_Resp_From_AHL_AFL_HS: 8 AHL_AFL_HS
  SG_ DgnInf: 7|64@0+ (1,0) [0|1.8446742e+19] "" FCP_HS ONSTAR_HS TestTool_HS

BO_ 1602 USDT_Resp_From_EHPS_EPS_HS: 8 EPS_HS
  SG_ DgnInf: 7|64@0+ (1,0) [0|1.8446742e+19] "" FCP_HS ONSTAR_HS TestTool_HS

BO_ 2027 USDT_Resp_From_FSCM_HS: 8 FSCM_HS
  SG_ DgnInf: 7|64@0+ (1,0) [0|1.8446742e+19] "" FCP_HS ONSTAR_HS TestTool_HS

BO_ 1515 UUDT_Resp_From_FSCM_HS: 8 FSCM_HS
  SG_ DgnInf: 7|64@0+ (1,0) [0|1.8446742e+19] "" FCP_HS ONSTAR_HS TestTool_HS

BO_ 1614 USDT_Resp_From_SADS_HS: 8 SADS_HS
  SG_ DgnInf: 7|64@0+ (1,0) [0|1.8446742e+19] "" FCP_HS ONSTAR_HS TestTool_HS

BO_ 1348 UUDT_Resp_From_OBCM_HS: 8 OBCM_HS
  SG_ DgnInf_HS544: 7|64@0+ (1,0) [0|1.8446742e+19] "" FCP_HS ONSTAR_HS TestTool_HS

BO_ 1349 UUDT_Resp_From_ALC_HS: 8 ALC_HS
  SG_ DgnInf_HS545: 7|64@0+ (1,0) [0|1.8446742e+19] "" FCP_HS ONSTAR_HS TestTool_HS

BO_ 1352 UUDT_Resp_From_Free_48_HS: 8 Dummy_HS
  SG_ DgnInf_HS548: 7|64@0+ (1,0) [0|1.8446742e+19] "" FCP_HS ONSTAR_HS TestTool_HS

BO_ 1354 UUDT_Resp_From_SAS_HS: 8 SAS_HS
  SG_ DgnInf_HS54A: 7|64@0+ (1,0) [0|1.8446742e+19] "" FCP_HS ONSTAR_HS TestTool_HS

BO_ 1605 USDT_Resp_From_ALC_HS: 8 ALC_HS
  SG_ DgnInf: 7|64@0+ (1,0) [0|1.8446742e+19] "" FCP_HS ONSTAR_HS TestTool_HS

BO_ 1620 USDT_Resp_From_EPB_HS: 8 EPB_HS
  SG_ DgnInf: 7|64@0+ (1,0) [0|1.8446742e+19] "" FCP_HS ONSTAR_HS TestTool_HS

BO_ 1604 USDT_Resp_From_OBCM_HS: 8 OBCM_HS
  SG_ DgnInf: 7|64@0+ (1,0) [0|1.8446742e+19] "" FCP_HS ONSTAR_HS TestTool_HS

BO_ 1612 USDT_Resp_From_PFAF_HS: 8 PFAF_HS
  SG_ DgnInf: 7|64@0+ (1,0) [0|1.8446742e+19] "" FCP_HS ONSTAR_HS TestTool_HS

BO_ 1615 USDT_Resp_From_RDCM_HS: 8 RDCM_HS
  SG_ DgnInf: 7|64@0+ (1,0) [0|1.8446742e+19] "" FCP_HS ONSTAR_HS TestTool_HS

BO_TX_BU_ 417:PCM_HS,ECM_HS;
BO_TX_BU_ 1233:PCM_HS,ECM_HS;
BO_TX_BU_ 1217:PCM_HS,ECM_HS;
BO_TX_BU_ 1017:PCM_HS,ECM_HS;
BO_TX_BU_ 977:PCM_HS,ECM_HS;
BO_TX_BU_ 201:PCM_HS,ECM_HS;
BO_TX_BU_ 501:PCM_HS,TCM_HS,ECM_HS;
BO_TX_BU_ 1225:PCM_HS,TCM_HS,ECM_HS;
BO_TX_BU_ 257:FCP_HS,ONSTAR_HS,TestTool_HS;
BO_TX_BU_ 2015:FCP_HS,ONSTAR_HS,TestTool_HS;
BO_TX_BU_ 2016:FCP_HS,ONSTAR_HS,TestTool_HS;
BO_TX_BU_ 197:EBCM_OBD_HS,EBCM_HS;
BO_TX_BU_ 249:PCM_HS,TCM_HS,ECM_HS;
BO_TX_BU_ 505:BCM_HS,PTO_HS;
BO_TX_BU_ 2024:PCM_HS,ECM_HS;
BO_TX_BU_ 1512:PCM_HS,ECM_HS;
BO_TX_BU_ 840:EBCM_OBD_HS,EBCM_HS;
BO_TX_BU_ 193:EBCM_OBD_HS,EBCM_HS;
BO_TX_BU_ 455:EBCM_OBD_HS,EBCM_HS;
BO_TX_BU_ 761:EBCM_OBD_HS,EBCM_HS;
BO_TX_BU_ 489:EBCM_OBD_HS,EBCM_HS;
BO_TX_BU_ 381:EBCM_OBD_HS,EBCM_HS;
BO_TX_BU_ 2025:HCP_HS,BCP_HS;
BO_TX_BU_ 1513:HCP_HS,BCP_HS;
BO_TX_BU_ 2030:VICM2_HS,FICM_HS,GPCM_HS;
BO_TX_BU_ 1518:VICM2_HS,FICM_HS,GPCM_HS;
BO_TX_BU_ 1346:VES_HS,EPS_HS;
BO_TX_BU_ 1602:VES_HS,EPS_HS;
BO_TX_BU_ 2027:ICCM_OBD_HS,FSCM_ITBC_HS,FSCM_HS;
BO_TX_BU_ 1515:ICCM_OBD_HS,FSCM_ITBC_HS,FSCM_HS;
BO_TX_BU_ 1348:DCDC_HS,OBCM_HS;
BO_TX_BU_ 1604:DCDC_HS,OBCM_HS;
VAL_ 417 EngCrsCntrlMode 0 "Inactive" 1 "Engaged" 2 "Resume" 3 "Accel" 4 "Coast" 5 "Tap";
VAL_ 417 EngPstOxgSnsDgAstRq 0 "false" 1 "true";
VAL_ 417 CrsCtrlCnstSpdAct 0 "false" 1 "true";
VAL_ 417 WrmUpShftPtrnRq 0 "Inactive" 1 "Active";
VAL_ 417 EngAlwCltAdp 0 "false" 1 "true";
VAL_ 417 AccPdlPosPcntFullRngV 0 "Valid" 1 "Invalid";
VAL_ 417 DslPrtFltrIdlRgtnMdReq 0 "false" 1 "true";
VAL_ 417 DslPartFltrClngAlgActM 0 "Don't Use Data" 1 "Use Data";
VAL_ 417 DslPartFltrClngAlgAct 0 "false" 1 "true";
VAL_ 417 EngCylDeactMd 0 "All Cylinders Active" 1 "Deactivation In Progress" 2 "Half of Total Cylinders Active" 3 "Reactivation In Progress";
VAL_ 417 ACCmCltEngd 0 "false" 1 "true";
VAL_ 417 ParkNeutralSwStatV 0 "Valid" 1 "Invalid";
VAL_ 417 ParkNeutralSwStat 0 "Park/Neutral" 1 "Not Park/Neutral";
VAL_ 417 EngColdHiIdleActive 0 "false" 1 "true";
VAL_ 417 EngCyDactTqSmtAct 0 "false" 1 "true";
VAL_ 417 EngBrkStat 0 "Inactive" 1 "Active Not Absorbing Torque" 2 "Active Absorbing Torque";
VAL_ 417 TracCntlSysPwrtrnInhbt 0 "false" 1 "true";
VAL_ 417 EngMtlProtAtv 0 "false" 1 "true";
VAL_ 417 EngDgTrqCnvClUnlkRqd 0 "false" 1 "true";
VAL_ 417 EngCyldrDeactReqd 0 "false" 1 "true";
VAL_ 417 ETGRReqdGear 0 "No Action" 1 "First Gear" 2 "Second Gear" 3 "Third Gear" 4 "Fourth Gear" 5 "Fifth Gear" 6 "Sixth Gear" 7 "Seventh Gear" 8 "Eighth Gear";
VAL_ 417 ETGRReqType 0 "No Action" 1 "Max Gear Request" 2 "Min Gear Request" 3 "Hold Gear";
VAL_ 1233 EngShtdwnAct 0 "false" 1 "true";
VAL_ 1233 EngShtdwnPndgIO 0 "false" 1 "true";
VAL_ 1233 FuelFltChgNwIO 0 "false" 1 "true";
VAL_ 1233 PTExPrtclFltrWrn2IO 0 "false" 1 "true";
VAL_ 1233 PTHiElecLdReqd 0 "false" 1 "true";
VAL_ 1233 PTExPrtclFltrWrnIO 0 "false" 1 "true";
VAL_ 1233 AirCndOffIO 0 "false" 1 "true";
VAL_ 1233 DslGlwPlgIO 0 "false" 1 "true";
VAL_ 1233 StgDisIO 0 "false" 1 "true";
VAL_ 1233 RdcdPwrIO 0 "false" 1 "true";
VAL_ 1233 FlLvlPctV 0 "Valid" 1 "Invalid";
VAL_ 1233 EngWtrInFlIO 0 "false" 1 "true";
VAL_ 1233 EngOilTmpV 0 "Valid" 1 "Invalid";
VAL_ 1233 EngOilPrsV 0 "Valid" 1 "Invalid";
VAL_ 1233 EngOilPrsLwIO 0 "false" 1 "true";
VAL_ 1233 EngOilLvlLwIO 0 "false" 1 "true";
VAL_ 1233 EngOilChngIO 0 "false" 1 "true";
VAL_ 1233 EngHt_StpEngIO 0 "false" 1 "true";
VAL_ 1233 EngHotFuelEnrchmntIO 0 "false" 1 "true";
VAL_ 1233 CkFlFilrCapIO 0 "false" 1 "true";
VAL_ 1217 LegPstDTCClrDrvCyCm 0 "false" 1 "true";
VAL_ 1217 LegDiagColdStCndMet 0 "false" 1 "true";
VAL_ 1217 LegDiagColdStCndFltPr 0 "false" 1 "true";
VAL_ 1217 EngEconMdCmnd 0 "false" 1 "true";
VAL_ 1217 DslExhFldRmngDstHRsV 0 "Valid" 1 "Invalid";
VAL_ 1217 EngOilHotIO 0 "false" 1 "true";
VAL_ 1217 OAT_PT_EstV 0 "Valid" 1 "Invalid";
VAL_ 1217 LegDiagStndCndMet 0 "false" 1 "true";
VAL_ 1217 LegDiagStndCndFltPr 0 "false" 1 "true";
VAL_ 1217 OAT_PT_EstM 0 "Don't Use Data" 1 "Use Data";
VAL_ 1217 EngWrmUpAch 0 "false" 1 "true";
VAL_ 1217 EngIntAirTmpV 0 "Valid" 1 "Invalid";
VAL_ 1217 EngCltTmpV 0 "Valid" 1 "Invalid";
VAL_ 1217 BarPrsAbsV 0 "Valid" 1 "Invalid";
VAL_ 985 EDADS_RcmndtFwdGr 0 "None" 1 "First Gear" 2 "Second Gear" 3 "Third Gear" 4 "Fourth Gear" 5 "Fifth Gear" 6 "Sixth Gear" 7 "Seventh Gear" 8 "Eighth Gear" 9 "Unused and Reserved 1" 10 "Unused and Reserved 2" 11 "Unused and Reserved 3" 12 "Unused and Reserved 4" 13 "Unused and Reserved 5" 14 "Unused and Reserved 6" 15 "Unused and Reserved 7";
VAL_ 985 EDADS_CrntFwdMsdG 0 "None" 1 "First Gear" 2 "Second Gear" 3 "Third Gear" 4 "Fourth Gear" 5 "Fifth Gear" 6 "Sixth Gear" 7 "Seventh Gear" 8 "Eighth Gear" 9 "Unused and Reserved 1" 10 "Unused and Reserved 2" 11 "Unused and Reserved 3" 12 "Unused and Reserved 4" 13 "Unused and Reserved 5" 14 "Unused and Reserved 6" 15 "Unused and Reserved 7";
VAL_ 985 EDADS_ShftIndStat 0 "Shift Down" 1 "Shift Up" 2 "No Shift";
VAL_ 985 EDADS_EcoDrvShftIO 0 "false" 1 "true";
VAL_ 1017 ACRfHiSdFldPrsV 0 "Valid" 1 "Invalid";
VAL_ 1017 GenStptDtCycPtOvrAct 0 "false" 1 "true";
VAL_ 1017 VehTopSpdLmtMdAct 0 "false" 1 "true";
VAL_ 1017 GenFldDutCycV 0 "Valid" 1 "Invalid";
VAL_ 1017 GenFld 0 "false" 1 "true";
VAL_ 1017 FlInjRlCtRstOcc 0 "false" 1 "true";
VAL_ 1017 EngSpdLmtnMdAct 0 "false" 1 "true";
VAL_ 977 AutoMdSpdLmtStat 0 "No Speed Limit Change" 1 "Proposed Speed Limit Change" 2 "Accepted Speed Limit Change" 3 "Declined Speed Limit Change";
VAL_ 977 FuelFltLifRstPerf 0 "false" 1 "true";
VAL_ 977 SpdLmtrSpdWrngAct 0 "false" 1 "true";
VAL_ 977 CrsCntlDrSelSpdAct 0 "false" 1 "true";
VAL_ 977 ACCompCmnd 0 "Off" 1 "On";
VAL_ 977 EngBstPrsIndV 0 "Valid" 1 "Invalid";
VAL_ 977 EngOilLifRstPerf 0 "false" 1 "true";
VAL_ 977 ThrPosV 0 "Valid" 1 "Invalid";
VAL_ 977 EngOilStrvtnIO 0 "false" 1 "true";
VAL_ 977 EngNEmsnsRelMalfAct 0 "false" 1 "true";
VAL_ 977 EngEmsRelMalfIndReq 0 "Continuous Indication" 1 "No Indication" 2 "Flashing 1 Hertz Indication" 3 "Flashing 2 Hertz Indication" 4 "Flashing 0.5 Hertz Indication";
VAL_ 977 EngCstFlCutAct 0 "false" 1 "true";
VAL_ 201 PrsElvtdIdlCntlStat 0 "Disabled" 1 "Enabled";
VAL_ 201 Eng12vStrtrMtrCmmdOn 0 "false" 1 "true";
VAL_ 201 EngCntrlRunCrnkTrmSt 0 "Inactive" 1 "Active";
VAL_ 201 EngAirIntBstPrV 0 "Valid" 1 "Invalid";
VAL_ 201 SpdLmtrSpdWrngEnbld 0 "false" 1 "true";
VAL_ 201 EngCylDactEvntPndg 0 "false" 1 "true";
VAL_ 201 EngCylDeactMd 0 "All Cylinders Active" 1 "Deactivation In Progress" 2 "Half of Total Cylinders Active" 3 "Reactivation In Progress";
VAL_ 201 RmVhStrtEngRng 0 "false" 1 "true";
VAL_ 201 PFEngSpdCmndSpcd 0 "false" 1 "true";
VAL_ 201 PltfrmEngSpdCmdInhtRq 0 "Allow Platform Engine Speed Control" 1 "Inhibit Platform Eng. Speed Control";
VAL_ 201 PT_BrkPedDscrtInpStatV 0 "Valid" 1 "Invalid";
VAL_ 201 PT_BrkPedDscrtInpStat 0 "Brake Not Applied" 1 "Brake Applied";
VAL_ 201 CrsCntEnbld 0 "false" 1 "true";
VAL_ 201 CrsCntAtv 0 "false" 1 "true";
VAL_ 201 DrvThrottlOvrrdDet 0 "false" 1 "true";
VAL_ 201 PT_CrnkAct 0 "false" 1 "true";
VAL_ 201 PTRunAbrt 0 "false" 1 "true";
VAL_ 201 PTO_PT_RunAbrtd 0 "false" 1 "true";
VAL_ 201 PTCrnkAbrted 0 "false" 1 "true";
VAL_ 201 EngSpdStat 0 "Normal Operation" 1 "Degraded Operation" 3 "Invalid";
VAL_ 201 EngRunAtv 0 "false" 1 "true";
VAL_ 201 EngIdlAtv 0 "false" 1 "true";
VAL_ 201 AccActPosV 0 "Valid" 1 "Invalid";
VAL_ 501 EngRecDwnshftIO 0 "false" 1 "true";
VAL_ 501 TrnsPattSelEcnMdOCm 0 "false" 1 "true";
VAL_ 501 CltStartSwAtvV 0 "Valid" 1 "Invalid";
VAL_ 501 CltStartSwAtv 0 "false" 1 "true";
VAL_ 501 CltchPdlActPosV 0 "Valid" 1 "Invalid";
VAL_ 501 TrnsEngdStateV 0 "Valid" 1 "Invalid";
VAL_ 501 TrnsEngdState 0 "Transmission Not Engaged" 1 "Transmission Engaged in Forward" 2 "Transmission Engaged in Reverse" 3 "Operating State Not Reached";
VAL_ 501 TrnsShftLvrLckRqd 0 "false" 1 "true";
VAL_ 501 TransTUDMdStat 0 "No Activation" 1 "Driver Shift Control Active" 2 "Electronic Range Select Active";
VAL_ 501 TrnCrpMdAtv 0 "false" 1 "true";
VAL_ 501 TrnsSkpShftIO 0 "false" 1 "true";
VAL_ 501 TrnsSftMdStat 0 "No Override Mode" 1 "Performance Mode" 2 "Lift-Foot Cornering Mode" 3 "Automatic Grade Braking Mode";
VAL_ 501 TrnsRngInhbtStat 0 "No Range Inhibit Active" 1 "Transmission Inhibit Active" 2 "Transmission Range Re-Selection Req" 3 "Driveline Not Engaged" 4 "Diagnostic Inhibit Active";
VAL_ 501 TopTrvlCltchSwActV 0 "Valid" 1 "Invalid";
VAL_ 501 TopTrvlCltchSwAct 0 "false" 1 "true";
VAL_ 501 EngRecmndUpshftIO 0 "false" 1 "true";
VAL_ 501 DrvtShftCntrlTrgtGear 0 "Not Supported" 1 "First Gear" 2 "Second Gear" 3 "Third Gear" 4 "Fourth Gear" 5 "Fifth Gear" 6 "Sixth Gear" 7 "Seventh Gear" 8 "Eighth Gear";
VAL_ 501 DrShftCntrlReqDndIO 0 "false" 1 "true";
VAL_ 501 TrnShftPtrnActStat 0 "Default Shift Pattern Active" 1 "Shift Pattern 1 Active" 2 "Shift Pattern 2 Active" 3 "Shift Pattern 3 Active" 4 "Shift Pattern 4 Active" 5 "PT Non-Protection Pattern Active" 6 "PT Protection Pattern Active";
VAL_ 501 TrnsFldPrsPrsnt 0 "false" 1 "true";
VAL_ 501 TrnsShftLvrPos 0 "Between Ranges" 1 "Park Range" 2 "Reverse Range" 3 "Neutral Range" 4 "Forward Range A" 5 "Forward Range B" 6 "Forward Range C" 7 "Forward Range D" 8 "Forward Range E" 9 "Forward Range F" 10 "Forward Range G" 11 "Forward Range H" 15 "Lever Position Unknown";
VAL_ 501 TrnsShftLvrPosV 0 "Valid" 1 "Invalid";
VAL_ 501 TrnsTrqCnvCltCmndMd 0 "Unlocked" 1 "Transitioning" 2 "Controlled Slip" 3 "Locked" 7 "Not Supported";
VAL_ 501 AutoTransComndGear 0 "Not Supported" 1 "First Gear" 2 "Second Gear" 3 "Third Gear" 4 "Fourth Gear" 5 "Fifth Gear" 6 "Sixth Gear" 7 "Seventh Gear" 8 "Eighth Gear" 10 "EVT Mode 1" 11 "EVT Mode 2" 12 "CVT Forward Gear" 13 "Neutral Gear" 14 "Reverse Gear" 15 "Park Gear";
VAL_ 501 AutoTransGrSftDirect 0 "No Shift in Progress" 1 "Upshift in Progress" 2 "Downshift in Progress";
VAL_ 501 TransEstGear 0 "Not Supported" 1 "First Gear" 2 "Second Gear" 3 "Third Gear" 4 "Fourth Gear" 5 "Fifth Gear" 6 "Sixth Gear" 7 "Seventh Gear" 8 "Eighth Gear" 10 "EVT Mode 1" 11 "EVT Mode 2" 12 "CVT Forward Gear" 13 "Neutral Gear" 14 "Reverse Gear" 15 "Park Gear";
VAL_ 501 TransEstGearV 0 "Valid" 1 "Invalid";
VAL_ 1225 TCTPIR_DrvNotfn 0 "No Indication" 1 "Indication 1" 2 "Indication 2" 3 "Indication 3" 4 "Indication 4" 5 "Indication 5" 6 "Indication 6" 7 "Indication 7" 8 "Indication 8" 9 "Indication 9" 10 "Indication 10" 11 "Indication 11" 12 "Indication 12" 13 "Indication 13" 14 "Indication 14" 15 "Indication 15";
VAL_ 1225 GrdBrkgAct 0 "false" 1 "true";
VAL_ 1225 RrPTCoolFanRatFltStat 0 "Indeterminate" 1 "Pass" 2 "Fail" 3 "Reserved and Unused";
VAL_ 1225 TrnsThrmlMngmntStat 0 "Normal" 1 "Countermeasures Active" 2 "Driver Intervention Requested";
VAL_ 1225 TrnsNEmsRltMalfActv 0 "false" 1 "true";
VAL_ 1225 TransOilTempSensPres 0 "false" 1 "true";
VAL_ 1225 TrnEmsMlfAtv 0 "false" 1 "true";
VAL_ 1225 TrnOilTmpV 0 "Valid" 1 "Invalid";
VAL_ 1225 TERDTC_SysDes 0 "P0-Powertrain Codes SAE Controlled" 1 "P1-Powertrain Codes MFG Controlled" 2 "P2-Powertrain Codes Reserved" 3 "P3-Powertrain Codes Reserved" 4 "C0-Chassis Codes SAE Controlled" 5 "C1-Chassis Codes MFG Controlled" 6 "C2-Chassis Codes Reserved" 7 "C3-Chassis Codes Reserved" 8 "B0-Body Codes SAE Controlled" 9 "B1-Body Codes MFG Controlled" 10 "B2-Body Codes Reserved" 11 "B3-Body Codes Reserved" 12 "U0-Network Codes SAE Controlled" 13 "U1-Network Codes MFG Controlled" 14 "U2-Network Codes Reserved" 15 "U3-Network Codes Reserved";
VAL_ 409 TDslPrtFltrIdlRgtnMdAtv 0 "false" 1 "true";
VAL_ 409 TTRLT_TqRdnRlznSgg 0 "No Suggestion" 1 "Transient Optimized" 2 "Stability Optimized 1" 3 "Stability Optimized 2";
VAL_ 409 TTRLT_TorqInvntnTyp 0 "No Intervention" 1 "Maximum Limit" 2 "Minimum Limit";
VAL_ 409 TTRST_TorqInvntnTyp 0 "No Intervention" 1 "Maximum Limit";
VAL_ 413 TrnsCyDactTransStat 0 "Not Ready" 1 "Ready for All Cylinders" 2 "Ready for Half of TotalCylinders";
VAL_ 413 EngBrkDsblReqd 0 "false" 1 "true";
VAL_ 413 TransNtrlCntrlMdStat 0 "Neutral Control Not Active" 1 "Entering Neutral Control" 2 "Neutral Control Active" 3 "Exiting Neutral Control";
VAL_ 413 TrnsRtoCntlSysFlt 0 "false" 1 "true";
VAL_ 413 TrnTrbAngVlV 0 "Valid" 1 "Invalid";
VAL_ 413 TrnGrRatV 0 "Valid" 1 "Invalid";
VAL_ 413 TrnPrfAlgShfAtv 0 "false" 1 "true";
VAL_ 413 TESR_EngSpdCntlRsp 0 "No Suggestion" 1 "Transient Optimized" 2 "Stability Optimized Condition 1" 3 "Stability Optimized Condition 2";
VAL_ 413 TESR_EngSpdIntTyp 0 "No Intervention" 1 "Engine Speed Max Limit" 2 "Engine Speed Min Limit";
VAL_ 413 TrnsGrgShftAct 0 "false" 1 "true";
VAL_ 197 WRSLNDWhlRotStRst 0 "false" 1 "true";
VAL_ 197 WRSLNDWhlDistVal 0 "Valid" 1 "Invalid";
VAL_ 197 WRSRNDWhlRotStRst 0 "false" 1 "true";
VAL_ 197 WRSRNDWhlDistVal 0 "Valid" 1 "Invalid";
VAL_ 249 TrnsDrvlneTqShpDisRq 0 "false" 1 "true";
VAL_ 249 TrnsOtptRotRCRstOcc 0 "false" 1 "true";
VAL_ 249 TrnsOtptRotRCV 0 "Valid" 1 "Invalid";
VAL_ 249 TrnsOtptShftAngVelSnrPr 0 "false" 1 "true";
VAL_ 249 TrnsOutShftAngVelV 0 "Valid" 1 "Invalid";
VAL_ 249 TrnsOvrallEstTorqRatioV 0 "Valid" 1 "Invalid";
VAL_ 1009 ClmtCtrlHtrEngRunRq 0 "No Action" 1 "Engine Run Requested";
VAL_ 1009 OtsAirTmpCrValMsk 0 "Don't Use Data" 1 "Use Data";
VAL_ 1009 ACCmEngRunReq 0 "No Action" 1 "Engine Run Requested";
VAL_ 1009 OutAirTempVDA 0 "VirtualDeviceUnavailable" 1 "VirtualDeviceAvailable";
VAL_ 1009 OtsAirTmpCrValV 0 "Valid" 1 "Invalid";
VAL_ 1009 EngOffTmVDA 0 "VirtualDeviceUnavailable" 1 "VirtualDeviceAvailable";
VAL_ 1009 ClntCircPmpRq 0 "Off" 1 "On";
VAL_ 1009 EngOffTmExtRngV 0 "Valid" 1 "Invalid";
VAL_ 1009 PF_MinIdlBstLvlReq 0 "No Boost Requested" 1 "Boost Level 1" 2 "Boost Level 2" 3 "Boost Level 3";
VAL_ 1257 ElpsdTimeCntRstOcc 0 "false" 1 "true";
VAL_ 1257 ACCompType 0 "None" 1 "Fixed Displacement Clutched" 2 "Variable Displacement Mechanical" 3 "Variable Displacement Electronic" 4 "Electric Driven Motor";
VAL_ 1257 VSESysPrs 0 "false" 1 "true";
VAL_ 1257 ABSPr 0 "false" 1 "true";
VAL_ 1257 TCSysPr 0 "false" 1 "true";
VAL_ 1257 VehSpdCntlSystmType 0 "No Vehicle Speed Control" 1 "Conventional Cruise Control" 2 "Adaptive Cruise Control";
VAL_ 1257 PltfrmEngSpdCmdSysTp 0 "No Platform Eng. Speed Command Sys." 1 "Stationary PTO" 2 "Stationary Variable PTO" 3 "Mobile Variable PTO" 4 "Fast Idle" 5 "Enhanced Fast Idle" 6 "Auto Elevated Idle";
VAL_ 505 AllNodesVNA_1F9 0 "No Activation" 1 "Activate Virtual Network";
VAL_ 505 AccPdlPwrTkOffOvrAct 0 "false" 1 "true";
VAL_ 505 PTOTGRReqdGear 0 "No Action" 1 "First Gear" 2 "Second Gear" 3 "Third Gear" 4 "Fourth Gear" 5 "Fifth Gear" 6 "Sixth Gear" 7 "Seventh Gear" 8 "Eighth Gear";
VAL_ 505 PTOTGRReqType 0 "No Action" 1 "Max Gear Request" 2 "Min Gear Request" 3 "Hold Gear";
VAL_ 505 PTORmtEngStrtReq 0 "PTO Remote Start Not Requested" 1 "PTO Remote Start Requested";
VAL_ 505 TrnsPTOCltchRelRqd 0 "false" 1 "true";
VAL_ 505 FstIdlMdAct 0 "false" 1 "true";
VAL_ 505 PTOMdAct 0 "false" 1 "true";
VAL_ 505 PTOEngTrqLmtRchd 0 "false" 1 "true";
VAL_ 505 PltfrmEngSpdCmdMdAct 0 "false" 1 "true";
VAL_ 505 PFESpdCmdOnSwAct 0 "false" 1 "true";
VAL_ 505 PFESpdCmdDeSwAct 0 "false" 1 "true";
VAL_ 505 PFESpdCmdInSwAct 0 "false" 1 "true";
VAL_ 505 PFESpdCmdSwDIntg 0 "Data Valid" 1 "Data Invalid" 2 "Failure Detected";
VAL_ 505 PTORmtEngShtdwnReqd 0 "false" 1 "true";
VAL_ 497 FuelFltLfRstRqd 0 "false" 1 "true";
VAL_ 497 ACCompSysVDA 0 "VirtualDeviceUnavailable" 1 "VirtualDeviceAvailable";
VAL_ 497 BkupPwrModeMstrVDA 0 "VirtualDeviceUnavailable" 1 "VirtualDeviceAvailable";
VAL_ 497 PrkBrkVDA 0 "VirtualDeviceUnavailable" 1 "VirtualDeviceAvailable";
VAL_ 497 PrkBrkVDM 0 "Don't Use Data" 1 "Use Data";
VAL_ 497 BkupPwrModeMstrVDM 0 "Don't Use Data" 1 "Use Data";
VAL_ 497 ACCompSysVDM 0 "Don't Use Data" 1 "Use Data";
VAL_ 497 AirbgVDA 0 "VirtualDeviceUnavailable" 1 "VirtualDeviceAvailable";
VAL_ 497 SysBkupPwrMdEn 0 "false" 1 "true";
VAL_ 497 SysBkUpPwrMd 0 "Off" 1 "Accessory" 2 "Run" 3 "Crank Request";
VAL_ 497 SysPwrMd 0 "Off" 1 "Accessory" 2 "Run" 3 "Crank Request";
VAL_ 497 TrStLgMdAtv 0 "false" 1 "true";
VAL_ 497 DispMeasSys 0 "Metric" 1 "English";
VAL_ 497 ACCmpsrFldOn 0 "false" 1 "true";
VAL_ 497 ACCompModReq 0 "Disengage Immediately" 1 "Disengage" 2 "Engage" 3 "No Action";
VAL_ 497 ACCompNormLdV 0 "Valid" 1 "Invalid";
VAL_ 497 PTORSMstrEngShtReq 0 "false" 1 "true";
VAL_ 497 EngOilLfRstRq 0 "false" 1 "true";
VAL_ 497 SIRDpl 0 "false" 1 "true";
VAL_ 497 PTORmStMsEngStRq 0 "PTO Remote Start Not Requested" 1 "PTO Remote Start Requested";
VAL_ 497 RmVehStrRq 0 "Remote Start Not Requested" 1 "Remote Start Requested";
VAL_ 497 ThrtlPrgrsnReq 0 "Map A" 1 "Map B" 2 "Map C";
VAL_ 497 PrkBrkSwAtv 0 "false" 1 "true";
VAL_ 497 PMMAccTrmSt 0 "Inactive" 1 "Active";
VAL_ 497 PMMRunCrkTrmSt 0 "Inactive" 1 "Active";
VAL_ 497 ImmblzrPreRelPswdStat 0 "No Information" 1 "Information Valid";
VAL_ 840 WhlRotDrctnlStLftDrvn 0 "Unknown" 1 "Forward" 2 "Reverse" 3 "Not Supported" 4 "Failed" 5 "Reserved 1" 6 "Reserved 2" 7 "Reserved 3";
VAL_ 840 WhlRotDrctnlStRtDrvn 0 "Unknown" 1 "Forward" 2 "Reverse" 3 "Not Supported" 4 "Failed" 5 "Reserved 1" 6 "Reserved 2" 7 "Reserved 3";
VAL_ 840 WhlGrndVlctyRtDrvnV 0 "Valid" 1 "Invalid";
VAL_ 840 WhlGrndVlctyLftDrvnV 0 "Valid" 1 "Invalid";
VAL_ 193 WRSLDWhlDistVal 0 "Valid" 1 "Invalid";
VAL_ 193 WRSLDWhlRotStatRst 0 "false" 1 "true";
VAL_ 193 WRSRDWhlRotStatRst 0 "false" 1 "true";
VAL_ 193 WRSRDWhlDistVal 0 "Valid" 1 "Invalid";
VAL_ 481 CrsSecSwStat 0 "Indeterminate" 1 "No Activation" 2 "Unused and Reserved 1" 3 "Gap Down" 4 "Gap Up" 5 "Speed Increase High" 6 "Speed Decrease High" 7 "Open/Short to Ground" 8 "Short to Power" 9 "Between Ranges" 10 "Unused and Reserved 2" 11 "Unused and Reserved 3" 12 "Unused and Reserved 4" 13 "Unused and Reserved 5" 14 "Unused and Reserved 6" 15 "Unused and Reserved 7";
VAL_ 481 DrvSelMdSw3Sta 0 "Inactive" 1 "Active";
VAL_ 481 DrvSelMdSw2Sta 0 "Inactive" 1 "Active";
VAL_ 481 AuxHtrRq 0 "Off" 1 "On";
VAL_ 481 AuxHtrAtv 0 "false" 1 "true";
VAL_ 481 DrvSelMdSw1Sta 0 "Inactive" 1 "Active";
VAL_ 481 FuelMdSwActV 0 "Valid" 1 "Invalid";
VAL_ 481 FuelMdSwAct 0 "False" 1 "True";
VAL_ 481 CrsSpdLmtrSwStat 0 "Indeterminate" 1 "No Activation" 2 "Resume" 3 "Set" 4 "SL/SW On/Off/GAP" 5 "Cruise On/Off" 6 "Cancel" 7 "Open/Short to Ground" 8 "Short to Power" 9 "Between Ranges";
VAL_ 481 AdptCrsGapSwAct 0 "No Activation" 1 "Decrease Gap" 2 "Increase Gap";
VAL_ 481 CrsCntrlSwStCanSwAct 0 "false" 1 "true";
VAL_ 481 CrsCntrlSwStSwDataIntgty 0 "Data Valid" 1 "Data Invalid" 2 "Failure Detected" 3 "Illegal Range";
VAL_ 481 CrsCntrlSwStSpdInSwAct 0 "false" 1 "true";
VAL_ 481 CrsCntrlSwStSpDcSwAct 0 "false" 1 "true";
VAL_ 481 CrsCntrlSwStSetSwAct 0 "false" 1 "true";
VAL_ 481 CrsCntrlSwStResSwAct 0 "false" 1 "true";
VAL_ 481 CrsCntrlSwStOnSwAct 0 "false" 1 "true";
VAL_ 481 CrsCntCncRq 0 "Do Not Cancel" 1 "Cancel";
VAL_ 455 CSETRER_TqIntvnTyp 0 "No Intervention" 1 "Reduce Torque" 2 "Increase Torque";
VAL_ 761 ABFI_CollPrepSysInhbt 0 "false" 1 "true";
VAL_ 761 ABFI_RrVirtlBmprInh 0 "false" 1 "true";
VAL_ 761 BrkPdlDrvApplPresV 0 "Valid" 1 "Invalid";
VAL_ 761 AutoBrkPTReqStat 0 "Inactive" 1 "Active" 2 "Failed" 3 "Serial Communication Failure" 4 "Unused and Reserved 1" 5 "Unused and Reserved 2" 6 "Unused and Reserved 3" 7 "Unused and Reserved 4";
VAL_ 761 WhlSpdSnsgDTCStat 0 "Not Supported" 1 "Critically Disabled" 2 "No Status to Report" 3 "Diagnostic Passed" 4 "Diagnostic Failed";
VAL_ 761 SprTireSt 0 "Undetermined" 1 "No Spare Detected" 2 "Spare Detected";
VAL_ 489 EnhDrvMdSwChUseRq 0 "false" 1 "true";
VAL_ 489 IMUDataMsk 0 "false" 1 "true";
VAL_ 489 DrvIndpntBrkAppAct 0 "false" 1 "true";
VAL_ 489 WhlSlpSt 0 "No Slip Detected" 1 "Negative Slip Detected" 2 "Positive Slip Detected" 3 "Slip Detection Fault";
VAL_ 489 BSTGRReqdGear 0 "No Action" 1 "First Gear" 2 "Second Gear" 3 "Third Gear" 4 "Fourth Gear" 5 "Fifth Gear" 6 "Sixth Gear" 7 "Seventh Gear" 8 "Eighth Gear";
VAL_ 489 BSTGRReqType 0 "No Action" 1 "Max Gear Request" 2 "Min Gear Request" 3 "Hold Gear";
VAL_ 489 VSELatAccV 0 "Valid" 1 "Invalid";
VAL_ 489 VSEAct 0 "false" 1 "true";
VAL_ 489 VhDynCntlSysSt 0 "Normal Operation" 1 "Reduced Function" 2 "Temporarily Inhibited" 3 "Permanently Failed" 4 "Warming Up" 5 "Calibrating" 6 "Enhanced Operation" 7 "Driver Disabled";
VAL_ 489 VehDynYawRateV 0 "Valid" 1 "Invalid";
VAL_ 489 TrnsBrkSysCltchRelRqd 0 "false" 1 "true";
VAL_ 489 TracCntrlSysDrIntnt 0 "Disabled" 1 "Enabled";
VAL_ 489 VehDynOvrUndrStrV 0 "Valid" 1 "Invalid";
VAL_ 489 TCSysEnbld 0 "false" 1 "true";
VAL_ 489 TCSysAtv 0 "false" 1 "true";
VAL_ 489 BrkPdlDrvAppPrsDetcdV 0 "Valid" 1 "Invalid";
VAL_ 489 BrkPdlDrvAppPrsDetcd 0 "false" 1 "true";
VAL_ 489 ACCBrkngAct 0 "false" 1 "true";
VAL_ 489 ABSFld 0 "false" 1 "true";
VAL_ 489 ABSAtv 0 "false" 1 "true";
VAL_ 381 HillDesCtrlRedVehSpIO 0 "false" 1 "true";
VAL_ 381 EBDFailed 0 "false" 1 "true";
VAL_ 381 StWhAnVDA 0 "VirtualDeviceUnavailable" 1 "VirtualDeviceAvailable";
VAL_ 381 TirePrsLowIO 0 "false" 1 "true";
VAL_ 381 VaccBoostFailure 0 "false" 1 "true";
VAL_ 381 VSESysPrs 0 "false" 1 "true";
VAL_ 381 HalfSysFail 0 "false" 1 "true";
VAL_ 381 ActVehAccelV 0 "Valid" 1 "Invalid";
VAL_ 381 BksOvht 0 "false" 1 "true";
VAL_ 381 TCSysPr 0 "false" 1 "true";
VAL_ 381 ABSPr 0 "false" 1 "true";
VAL_ 381 TreInfMonSysRstPrfmd 0 "false" 1 "true";
VAL_ 381 ABSIO 0 "false" 1 "true";
VAL_ 381 BrkPadWrnIO 0 "false" 1 "true";
VAL_ 381 VehStabEnhmntMd 0 "Off" 1 "Normal" 2 "Competitive";
VAL_ 381 VehStabEnhmntStat 0 "Inactive" 1 "Active" 2 "Fault" 3 "Warming Up" 4 "Not Ready";
VAL_ 381 TCSysOpMd 0 "Off" 1 "Normal" 2 "Off Road";
VAL_ 381 TCSysOpStat 0 "Inactive" 1 "Active" 2 "Fault";
VAL_ 381 BrkSysRedBrkTlltlReq 0 "false" 1 "true";
VAL_ 381 BrkSysBrkLtsReqd 0 "false" 1 "true";
VAL_ 241 NotEventStat 0 "No Event" 1 "Near Deployment Event" 2 "Pretensioner Deployment Event" 3 "Airbag Deployment Event";
VAL_ 241 BrkAppSnsrHmPosLrnd 0 "false" 1 "true";
VAL_ 241 BrkPedTrvlAchvd 0 "false" 1 "true";
VAL_ 241 BrkPedTrvlAchvdV 0 "Valid" 1 "Invalid";
VAL_ 241 BrkPdlModTrvlV 0 "Valid" 1 "Invalid";
VAL_ 241 BrkPdlModTrvl 0 "false" 1 "true";
CM_ SG_ 417 TracCntlSysPwrtrnInhbt "ETEI 3.1";
CM_ SG_ 977 ACCmpNrmLdGrdAld "dm3/m/s = dm3/minute/second";
CM_ BO_ 201 "Changed for PPEI 3.6";
CM_ SG_ 201 EngRunAtv "Indication from powertrain that the engine is running (Has RPM > 0)";
CM_ SG_ 501 TrnShftPtrnActStat "(PT = Powertrain)";
CM_ SG_ 1249 VehIdNmDig10_17 "Desc: 8 ASCII Characters";
CM_ SG_ 481 AuxHtrRq "Auxiliary Heater shall be used to denote a heater function that uses some kind of power, electrical or mechanical,  that was generated by the engine.";
CM_ SG_ 481 AuxHtrAtv "Auxiliary Heater shall be used to denote a heater function that uses some kind of power, electrical or mechanical,  that was generated by the engine.";
CM_ BO_ 489 "Changed for PPEI 3.6";
CM_ SG_ 381 BrkSysRedBrkTlltlReq "Added acc to Bj??rn 0410";
CM_ SG_ 241 BrkPdlModTrvlV "Indicates that the brake pedal position has passed a threshold for brake torque management and some 2 channel Vehicle Dynamics Control systems.";
CM_ SG_ 241 BrkPdlModTrvl "Indicates that the brake pedal position has passed a threshold for brake torque management and some 2 channel Vehicle Dynamics Control systems.";
BA_DEF_ SG_ "VNSigSLHS_VNReq" ENUM "No","Yes";
BA_DEF_ SG_ "VNSigSLHSSharedDiagnostic" ENUM "No","Yes";
BA_DEF_ SG_ "SignalType" STRING;
BA_DEF_ SG_ "PacketOrder" INT 0 65535;
BA_DEF_ SG_ "SignalLongName" STRING;
BA_DEF_ SG_ "GenSigStartValue" INT 0 65535;
BA_DEF_ SG_ "VNSigAllNodes" ENUM "No","Yes";
BA_DEF_ SG_ "GenSigDeltaValue" INT 0 0;
BA_DEF_ SG_ "GenSigSendType" ENUM "not used","not used","not used","not used","not used","not used","not used","NoSigSendType","not used","not used","OnAnyChange","OnChangeIfActive","OnDelta";
BA_DEF_ SG_ "GenSigSendOnInit" ENUM "Not Initialized","Application","Handler";
BA_DEF_ BO_ "AppGenMsgCycleTime" INT 0 0;
BA_DEF_ BO_ "GenMsgILSupport" ENUM "No","Yes";
BA_DEF_ BO_ "TpApplType" STRING;
BA_DEF_ BO_ "Prio" INT 0 7;
BA_DEF_ BO_ "MessageSubnet" ENUM "LS","MS","HS","CE","PE","HV","FO";
BA_DEF_ BO_ "DiagState" ENUM "No","Yes";
BA_DEF_ BO_ "GenMsgDelayTime" INT 0 100000;
BA_DEF_ BO_ "GenMsgCycleTime" INT 0 100000;
BA_DEF_ BO_ "GenMsgSendType" ENUM "cyclicX","spontanX","cyclicIfActiveX","spontanWithDelay","cyclicAndSpontanX","cyclicAndSpontanWithDelay","spontanWithRepitition","cyclicIfActiveAndSpontanWD";
BA_DEF_ BO_ "DiagResponse" ENUM "No","Yes";
BA_DEF_ BO_ "DiagRequest" ENUM "No","Yes";
BA_DEF_ BO_ "NmMessage" ENUM "No","Yes";
BA_DEF_DEF_ "VNSigSLHS_VNReq" "No";
BA_DEF_DEF_ "VNSigSLHSSharedDiagnostic" "No";
BA_DEF_DEF_ "SignalType" "";
BA_DEF_DEF_ "PacketOrder" 0;
BA_DEF_DEF_ "SignalLongName" "";
BA_DEF_DEF_ "GenSigStartValue" 0;
BA_DEF_DEF_ "VNSigAllNodes" "No";
BA_DEF_DEF_ "GenSigDeltaValue" 0;
BA_DEF_DEF_ "GenSigSendType" "NoSigSendType";
BA_DEF_DEF_ "GenSigSendOnInit" "Not Initialized";
BA_DEF_DEF_ "AppGenMsgCycleTime" 0;
BA_DEF_DEF_ "GenMsgILSupport" "Yes";
BA_DEF_DEF_ "TpApplType" "";
BA_DEF_DEF_ "Prio" 4;
BA_DEF_DEF_ "MessageSubnet" "FO";
BA_DEF_DEF_ "DiagState" "No";
BA_DEF_DEF_ "GenMsgDelayTime" 0;
BA_DEF_DEF_ "GenMsgCycleTime" 0;
BA_DEF_DEF_ "GenMsgSendType" "spontanX";
BA_DEF_DEF_ "DiagResponse" "No";
BA_DEF_DEF_ "DiagRequest" "No";
BA_DEF_DEF_ "NmMessage" "No";
BA_ "Prio" BO_ 417 0;
BA_ "GenMsgSendType" BO_ 417 0;
BA_ "GenMsgCycleTime" BO_ 417 25;
BA_ "MessageSubnet" BO_ 417 2;
BA_ "VNSigAllNodes" SG_ 417 EngCrsCntrlMode 1;
BA_ "SignalLongName" SG_ 417 EngCrsCntrlMode "Engine Cruise Control Mode";
BA_ "SignalType" SG_ 417 EngCrsCntrlMode "ENM";
BA_ "VNSigAllNodes" SG_ 417 EngPstOxgSnsDgAstRq 1;
BA_ "SignalLongName" SG_ 417 EngPstOxgSnsDgAstRq "Engine Post Oxygen Sensor Diagnostic Assistance Requested";
BA_ "SignalType" SG_ 417 EngPstOxgSnsDgAstRq "BLN";
BA_ "VNSigAllNodes" SG_ 417 CrsCtrlCnstSpdAct 1;
BA_ "SignalLongName" SG_ 417 CrsCtrlCnstSpdAct "Cruise Control Constant Speed Active";
BA_ "SignalType" SG_ 417 CrsCtrlCnstSpdAct "BLN";
BA_ "VNSigAllNodes" SG_ 417 WrmUpShftPtrnRq 1;
BA_ "SignalLongName" SG_ 417 WrmUpShftPtrnRq "Warm Up Shift Pattern Request";
BA_ "SignalType" SG_ 417 WrmUpShftPtrnRq "ENM";
BA_ "VNSigAllNodes" SG_ 417 EngIdlSpdRdcdRng 1;
BA_ "SignalLongName" SG_ 417 EngIdlSpdRdcdRng "Engine Idle Speed Reduced Range";
BA_ "SignalType" SG_ 417 EngIdlSpdRdcdRng "UNM";
BA_ "VNSigAllNodes" SG_ 417 EngAlwCltAdp 1;
BA_ "SignalLongName" SG_ 417 EngAlwCltAdp "Engine Allowed Clutch Adaptation";
BA_ "SignalType" SG_ 417 EngAlwCltAdp "BLN";
BA_ "VNSigAllNodes" SG_ 417 BsTrgtEngIdlSpd 1;
BA_ "SignalLongName" SG_ 417 BsTrgtEngIdlSpd "Base Target Engine Idle Speed";
BA_ "SignalType" SG_ 417 BsTrgtEngIdlSpd "UNM";
BA_ "VNSigAllNodes" SG_ 417 AccPdlPosPcntFullRngV 1;
BA_ "SignalLongName" SG_ 417 AccPdlPosPcntFullRngV "Accelerator Pedal Position Percent Full Range  Validity";
BA_ "SignalType" SG_ 417 AccPdlPosPcntFullRngV "ENM";
BA_ "VNSigAllNodes" SG_ 417 AccPdlPosPcntFullRng 1;
BA_ "SignalLongName" SG_ 417 AccPdlPosPcntFullRng "Accelerator Pedal Position Percent Full Range";
BA_ "SignalType" SG_ 417 AccPdlPosPcntFullRng "UNM";
BA_ "VNSigAllNodes" SG_ 417 DslPrtFltrIdlRgtnMdReq 1;
BA_ "SignalLongName" SG_ 417 DslPrtFltrIdlRgtnMdReq "Diesel Particulate Filter Idle Regeneration Mode Request";
BA_ "SignalType" SG_ 417 DslPrtFltrIdlRgtnMdReq "BLN";
BA_ "VNSigAllNodes" SG_ 417 DslPartFltrClngAlgActM 1;
BA_ "SignalLongName" SG_ 417 DslPartFltrClngAlgActM "Diesel Particle Filter Cleaning Algorithm Active Mask";
BA_ "SignalType" SG_ 417 DslPartFltrClngAlgActM "ENM";
BA_ "VNSigAllNodes" SG_ 417 DslPartFltrClngAlgAct 1;
BA_ "SignalLongName" SG_ 417 DslPartFltrClngAlgAct "Diesel Particle Filter Cleaning Algorithm Active";
BA_ "SignalType" SG_ 417 DslPartFltrClngAlgAct "BLN";
BA_ "VNSigAllNodes" SG_ 417 EngCylDeactMd 1;
BA_ "SignalLongName" SG_ 417 EngCylDeactMd "Engine Cylinder Deactivation Mode";
BA_ "SignalType" SG_ 417 EngCylDeactMd "ENM";
BA_ "VNSigAllNodes" SG_ 417 ACCmCltEngd 1;
BA_ "SignalLongName" SG_ 417 ACCmCltEngd "Air Conditioning Compressor Clutch Engaged";
BA_ "SignalType" SG_ 417 ACCmCltEngd "BLN";
BA_ "VNSigAllNodes" SG_ 417 ParkNeutralSwStatV 1;
BA_ "SignalLongName" SG_ 417 ParkNeutralSwStatV "Park Neutral Switch Status Validity";
BA_ "SignalType" SG_ 417 ParkNeutralSwStatV "ENM";
BA_ "VNSigAllNodes" SG_ 417 ParkNeutralSwStat 1;
BA_ "SignalLongName" SG_ 417 ParkNeutralSwStat "Park Neutral Switch Status";
BA_ "SignalType" SG_ 417 ParkNeutralSwStat "ENM";
BA_ "VNSigAllNodes" SG_ 417 EngColdHiIdleActive 1;
BA_ "SignalLongName" SG_ 417 EngColdHiIdleActive "Engine Cold High Idle Active";
BA_ "SignalType" SG_ 417 EngColdHiIdleActive "BLN";
BA_ "VNSigAllNodes" SG_ 417 EngCyDactTqSmtAct 1;
BA_ "SignalLongName" SG_ 417 EngCyDactTqSmtAct "Engine Cylinder Deactivation Torque Smoothing Active";
BA_ "SignalType" SG_ 417 EngCyDactTqSmtAct "BLN";
BA_ "VNSigAllNodes" SG_ 417 EngBrkStat 1;
BA_ "SignalLongName" SG_ 417 EngBrkStat "Engine Brake Status";
BA_ "SignalType" SG_ 417 EngBrkStat "ENM";
BA_ "VNSigAllNodes" SG_ 417 TracCntlSysPwrtrnInhbt 1;
BA_ "SignalLongName" SG_ 417 TracCntlSysPwrtrnInhbt "Traction Control System Powertrain Inhibit";
BA_ "SignalType" SG_ 417 TracCntlSysPwrtrnInhbt "BLN";
BA_ "VNSigAllNodes" SG_ 417 EngMtlProtAtv 1;
BA_ "SignalLongName" SG_ 417 EngMtlProtAtv "Engine Metal Protection Active";
BA_ "SignalType" SG_ 417 EngMtlProtAtv "BLN";
BA_ "VNSigAllNodes" SG_ 417 EngDgTrqCnvClUnlkRqd 1;
BA_ "SignalLongName" SG_ 417 EngDgTrqCnvClUnlkRqd "Engine Diagnostic Torque Converter Clutch Unlock Requested";
BA_ "SignalType" SG_ 417 EngDgTrqCnvClUnlkRqd "BLN";
BA_ "VNSigAllNodes" SG_ 417 EngCyldrDeactReqd 1;
BA_ "SignalLongName" SG_ 417 EngCyldrDeactReqd "Engine Cylinder Deactivation Requested";
BA_ "SignalType" SG_ 417 EngCyldrDeactReqd "BLN";
BA_ "VNSigAllNodes" SG_ 417 ETGRReqdGear 1;
BA_ "PacketOrder" SG_ 417 ETGRReqdGear 2;
BA_ "SignalLongName" SG_ 417 ETGRReqdGear "Engine Transmission Gear Request : Requested Gear";
BA_ "SignalType" SG_ 417 ETGRReqdGear "ENM";
BA_ "VNSigAllNodes" SG_ 417 ETGRReqType 1;
BA_ "PacketOrder" SG_ 417 ETGRReqType 1;
BA_ "SignalLongName" SG_ 417 ETGRReqType "Engine Transmission Gear Request : Request Type";
BA_ "SignalType" SG_ 417 ETGRReqType "ENM";
BA_ "Prio" BO_ 1233 0;
BA_ "GenMsgSendType" BO_ 1233 0;
BA_ "GenMsgCycleTime" BO_ 1233 500;
BA_ "MessageSubnet" BO_ 1233 2;
BA_ "VNSigAllNodes" SG_ 1233 EngShtdwnAct 1;
BA_ "SignalLongName" SG_ 1233 EngShtdwnAct "Engine Shutdown Active";
BA_ "SignalType" SG_ 1233 EngShtdwnAct "BLN";
BA_ "VNSigAllNodes" SG_ 1233 EngShtdwnPndgIO 1;
BA_ "SignalLongName" SG_ 1233 EngShtdwnPndgIO "Engine Shutdown Pending Indication On";
BA_ "SignalType" SG_ 1233 EngShtdwnPndgIO "BLN";
BA_ "VNSigAllNodes" SG_ 1233 FuelFltChgNwIO 1;
BA_ "SignalLongName" SG_ 1233 FuelFltChgNwIO "Fuel Filter Change Now Indication On";
BA_ "SignalType" SG_ 1233 FuelFltChgNwIO "BLN";
BA_ "VNSigAllNodes" SG_ 1233 PTExPrtclFltrWrn2IO 1;
BA_ "SignalLongName" SG_ 1233 PTExPrtclFltrWrn2IO "Powertrain Exhaust Particle Filter Warning 2 Indication On";
BA_ "SignalType" SG_ 1233 PTExPrtclFltrWrn2IO "BLN";
BA_ "VNSigAllNodes" SG_ 1233 PTHiElecLdReqd 1;
BA_ "SignalLongName" SG_ 1233 PTHiElecLdReqd "Powertrain High Electrical Load Requested";
BA_ "SignalType" SG_ 1233 PTHiElecLdReqd "BLN";
BA_ "VNSigAllNodes" SG_ 1233 PTExPrtclFltrWrnIO 1;
BA_ "SignalLongName" SG_ 1233 PTExPrtclFltrWrnIO "Powertrain Exhaust Particle Filter Warning Indication On";
BA_ "SignalType" SG_ 1233 PTExPrtclFltrWrnIO "BLN";
BA_ "VNSigAllNodes" SG_ 1233 AirCndOffIO 1;
BA_ "SignalLongName" SG_ 1233 AirCndOffIO "Air Conditioning Off Indication On";
BA_ "SignalType" SG_ 1233 AirCndOffIO "BLN";
BA_ "VNSigAllNodes" SG_ 1233 DslGlwPlgIO 1;
BA_ "SignalLongName" SG_ 1233 DslGlwPlgIO "Diesel Glow Plug Indication On";
BA_ "SignalType" SG_ 1233 DslGlwPlgIO "BLN";
BA_ "VNSigAllNodes" SG_ 1233 StgDisIO 1;
BA_ "SignalLongName" SG_ 1233 StgDisIO "Starting Disabled Indication On";
BA_ "SignalType" SG_ 1233 StgDisIO "BLN";
BA_ "VNSigAllNodes" SG_ 1233 RdcdPwrIO 1;
BA_ "SignalLongName" SG_ 1233 RdcdPwrIO "Reduced Power Indication On";
BA_ "SignalType" SG_ 1233 RdcdPwrIO "BLN";
BA_ "VNSigAllNodes" SG_ 1233 FuelTotCap 1;
BA_ "SignalLongName" SG_ 1233 FuelTotCap "Fuel Total Capacity";
BA_ "SignalType" SG_ 1233 FuelTotCap "UNM";
BA_ "VNSigAllNodes" SG_ 1233 FlLvlPctV 1;
BA_ "SignalLongName" SG_ 1233 FlLvlPctV "Fuel Level Percent Validity";
BA_ "SignalType" SG_ 1233 FlLvlPctV "ENM";
BA_ "VNSigAllNodes" SG_ 1233 FlLvlPct 1;
BA_ "SignalLongName" SG_ 1233 FlLvlPct "Fuel Level Percent";
BA_ "SignalType" SG_ 1233 FlLvlPct "UNM";
BA_ "VNSigAllNodes" SG_ 1233 EngWtrInFlIO 1;
BA_ "SignalLongName" SG_ 1233 EngWtrInFlIO "Engine Water In Fuel Indication On";
BA_ "SignalType" SG_ 1233 EngWtrInFlIO "BLN";
BA_ "VNSigAllNodes" SG_ 1233 EngOilTmpV 1;
BA_ "SignalLongName" SG_ 1233 EngOilTmpV "Engine Oil Temperature Validity";
BA_ "SignalType" SG_ 1233 EngOilTmpV "ENM";
BA_ "VNSigAllNodes" SG_ 1233 EngOilTmp 1;
BA_ "SignalLongName" SG_ 1233 EngOilTmp "Engine Oil Temperature";
BA_ "SignalType" SG_ 1233 EngOilTmp "UNM";
BA_ "VNSigAllNodes" SG_ 1233 EngOilPrsV 1;
BA_ "SignalLongName" SG_ 1233 EngOilPrsV "Engine Oil Pressure Validity";
BA_ "SignalType" SG_ 1233 EngOilPrsV "ENM";
BA_ "VNSigAllNodes" SG_ 1233 EngOilPrsLwIO 1;
BA_ "SignalLongName" SG_ 1233 EngOilPrsLwIO "Engine Oil Pressure Low Indication On";
BA_ "SignalType" SG_ 1233 EngOilPrsLwIO "BLN";
BA_ "VNSigAllNodes" SG_ 1233 EngOilPrs 1;
BA_ "SignalLongName" SG_ 1233 EngOilPrs "Engine Oil Pressure";
BA_ "SignalType" SG_ 1233 EngOilPrs "UNM";
BA_ "VNSigAllNodes" SG_ 1233 EngOilLvlLwIO 1;
BA_ "SignalLongName" SG_ 1233 EngOilLvlLwIO "Engine Oil Level Low Indication On";
BA_ "SignalType" SG_ 1233 EngOilLvlLwIO "BLN";
BA_ "VNSigAllNodes" SG_ 1233 EngOilChngIO 1;
BA_ "SignalLongName" SG_ 1233 EngOilChngIO "Engine Oil Change Indication On";
BA_ "SignalType" SG_ 1233 EngOilChngIO "BLN";
BA_ "VNSigAllNodes" SG_ 1233 EngHt_StpEngIO 1;
BA_ "SignalLongName" SG_ 1233 EngHt_StpEngIO "Engine Hot / Stop Engine Indication On";
BA_ "SignalType" SG_ 1233 EngHt_StpEngIO "BLN";
BA_ "VNSigAllNodes" SG_ 1233 EngHotFuelEnrchmntIO 1;
BA_ "SignalLongName" SG_ 1233 EngHotFuelEnrchmntIO "Engine Hot Fuel Enrichment Indication On";
BA_ "SignalType" SG_ 1233 EngHotFuelEnrchmntIO "BLN";
BA_ "VNSigAllNodes" SG_ 1233 CkFlFilrCapIO 1;
BA_ "SignalLongName" SG_ 1233 CkFlFilrCapIO "Check Fuel Filler Cap Indication On";
BA_ "SignalType" SG_ 1233 CkFlFilrCapIO "BLN";
BA_ "Prio" BO_ 1217 0;
BA_ "GenMsgSendType" BO_ 1217 0;
BA_ "GenMsgCycleTime" BO_ 1217 500;
BA_ "MessageSubnet" BO_ 1217 2;
BA_ "VNSigAllNodes" SG_ 1217 LegPstDTCClrDrvCyCm 1;
BA_ "SignalLongName" SG_ 1217 LegPstDTCClrDrvCyCm "Legislated Post DTC Clear Drive Cycle Complete";
BA_ "SignalType" SG_ 1217 LegPstDTCClrDrvCyCm "BLN";
BA_ "VNSigAllNodes" SG_ 1217 LegDiagColdStCndMet 1;
BA_ "SignalLongName" SG_ 1217 LegDiagColdStCndMet "Legislated Diagnostics Cold Start Conditions Met";
BA_ "SignalType" SG_ 1217 LegDiagColdStCndMet "BLN";
BA_ "VNSigAllNodes" SG_ 1217 LegDiagColdStCndFltPr 1;
BA_ "SignalLongName" SG_ 1217 LegDiagColdStCndFltPr "Legislated Diagnostics Cold Start Conditions Fault Present";
BA_ "SignalType" SG_ 1217 LegDiagColdStCndFltPr "BLN";
BA_ "VNSigAllNodes" SG_ 1217 EngEconMdCmnd 1;
BA_ "SignalLongName" SG_ 1217 EngEconMdCmnd "Engine Economy Mode Commanded";
BA_ "SignalType" SG_ 1217 EngEconMdCmnd "BLN";
BA_ "VNSigAllNodes" SG_ 1217 DslExhFldRmngDstHRsV 1;
BA_ "SignalLongName" SG_ 1217 DslExhFldRmngDstHRsV "Diesel Exhaust Fluid Remaining Distance High Resolution Validity";
BA_ "SignalType" SG_ 1217 DslExhFldRmngDstHRsV "ENM";
BA_ "VNSigAllNodes" SG_ 1217 DslExhFldRmngDstHRs 1;
BA_ "SignalLongName" SG_ 1217 DslExhFldRmngDstHRs "Diesel Exhaust Fluid Remaining Distance High Resolution";
BA_ "SignalType" SG_ 1217 DslExhFldRmngDstHRs "UNM";
BA_ "VNSigAllNodes" SG_ 1217 EngOilHotIO 1;
BA_ "SignalLongName" SG_ 1217 EngOilHotIO "Engine Oil Hot Indication On";
BA_ "SignalType" SG_ 1217 EngOilHotIO "BLN";
BA_ "VNSigAllNodes" SG_ 1217 OAT_PT_EstV 1;
BA_ "SignalLongName" SG_ 1217 OAT_PT_EstV "Outside Air Temperature Powertrain Estimated Validity";
BA_ "SignalType" SG_ 1217 OAT_PT_EstV "ENM";
BA_ "VNSigAllNodes" SG_ 1217 LegDiagStndCndMet 1;
BA_ "SignalLongName" SG_ 1217 LegDiagStndCndMet "Legislated Diagnostics Standard Conditions Met";
BA_ "SignalType" SG_ 1217 LegDiagStndCndMet "BLN";
BA_ "VNSigAllNodes" SG_ 1217 LegDiagStndCndFltPr 1;
BA_ "SignalLongName" SG_ 1217 LegDiagStndCndFltPr "Legislated Diagnostics Standard Conditions Fault Present";
BA_ "SignalType" SG_ 1217 LegDiagStndCndFltPr "BLN";
BA_ "VNSigAllNodes" SG_ 1217 OAT_PT_EstM 1;
BA_ "SignalLongName" SG_ 1217 OAT_PT_EstM "Outside Air Temperature Powertrain Estimated Mask";
BA_ "SignalType" SG_ 1217 OAT_PT_EstM "ENM";
BA_ "VNSigAllNodes" SG_ 1217 OAT_PT_Est 1;
BA_ "SignalLongName" SG_ 1217 OAT_PT_Est "Outside Air Temperature Powertrain Estimated";
BA_ "SignalType" SG_ 1217 OAT_PT_Est "UNM";
BA_ "VNSigAllNodes" SG_ 1217 EngWrmUpAch 1;
BA_ "SignalLongName" SG_ 1217 EngWrmUpAch "Engine Warm Up Cycle Achieved";
BA_ "SignalType" SG_ 1217 EngWrmUpAch "BLN";
BA_ "VNSigAllNodes" SG_ 1217 EngIntAirTmpV 1;
BA_ "SignalLongName" SG_ 1217 EngIntAirTmpV "Engine Intake Air Temperature Validity";
BA_ "SignalType" SG_ 1217 EngIntAirTmpV "ENM";
BA_ "VNSigAllNodes" SG_ 1217 EngIntAirTmp 1;
BA_ "SignalLongName" SG_ 1217 EngIntAirTmp "Engine Intake Air Temperature";
BA_ "SignalType" SG_ 1217 EngIntAirTmp "UNM";
BA_ "VNSigAllNodes" SG_ 1217 EngCltTmpV 1;
BA_ "SignalLongName" SG_ 1217 EngCltTmpV "Engine Coolant Temperature Validity";
BA_ "SignalType" SG_ 1217 EngCltTmpV "ENM";
BA_ "VNSigAllNodes" SG_ 1217 EngCltTmp 1;
BA_ "SignalLongName" SG_ 1217 EngCltTmp "Engine Coolant Temperature";
BA_ "SignalType" SG_ 1217 EngCltTmp "UNM";
BA_ "VNSigAllNodes" SG_ 1217 BarPrsAbsV 1;
BA_ "SignalLongName" SG_ 1217 BarPrsAbsV "Barometric Pressure Absolute Validity";
BA_ "SignalType" SG_ 1217 BarPrsAbsV "ENM";
BA_ "VNSigAllNodes" SG_ 1217 BarPrsAbs 1;
BA_ "SignalLongName" SG_ 1217 BarPrsAbs "Barometric Pressure Absolute";
BA_ "SignalType" SG_ 1217 BarPrsAbs "UNM";
BA_ "Prio" BO_ 985 0;
BA_ "GenMsgSendType" BO_ 985 0;
BA_ "GenMsgCycleTime" BO_ 985 100;
BA_ "MessageSubnet" BO_ 985 2;
BA_ "VNSigAllNodes" SG_ 985 EDADS_RcmndtFwdGr 1;
BA_ "PacketOrder" SG_ 985 EDADS_RcmndtFwdGr 4;
BA_ "SignalLongName" SG_ 985 EDADS_RcmndtFwdGr "ECO Drive Assist Display Status : Recommended Forward Gear";
BA_ "SignalType" SG_ 985 EDADS_RcmndtFwdGr "ENM";
BA_ "VNSigAllNodes" SG_ 985 EDADS_CrntFwdMsdG 1;
BA_ "PacketOrder" SG_ 985 EDADS_CrntFwdMsdG 3;
BA_ "SignalLongName" SG_ 985 EDADS_CrntFwdMsdG "ECO Drive Assist Display Status : Current Forward Measured Gear";
BA_ "SignalType" SG_ 985 EDADS_CrntFwdMsdG "ENM";
BA_ "VNSigAllNodes" SG_ 985 EDADS_ShftIndStat 1;
BA_ "PacketOrder" SG_ 985 EDADS_ShftIndStat 2;
BA_ "SignalLongName" SG_ 985 EDADS_ShftIndStat "ECO Drive Assist Display Status : Shift Indication Status";
BA_ "SignalType" SG_ 985 EDADS_ShftIndStat "ENM";
BA_ "VNSigAllNodes" SG_ 985 EDADS_EcoDrvShftIO 1;
BA_ "PacketOrder" SG_ 985 EDADS_EcoDrvShftIO 1;
BA_ "SignalLongName" SG_ 985 EDADS_EcoDrvShftIO "ECO Drive Assist Display Status : ECO Drive Assist Shift Indication On";
BA_ "SignalType" SG_ 985 EDADS_EcoDrvShftIO "BLN";
BA_ "Prio" BO_ 1017 0;
BA_ "GenMsgSendType" BO_ 1017 0;
BA_ "GenMsgCycleTime" BO_ 1017 250;
BA_ "MessageSubnet" BO_ 1017 2;
BA_ "VNSigAllNodes" SG_ 1017 ACRfHiSdFldPrsV 1;
BA_ "SignalLongName" SG_ 1017 ACRfHiSdFldPrsV "Air Conditioning Refrigerant High Side Fluid Pressure Validity";
BA_ "SignalType" SG_ 1017 ACRfHiSdFldPrsV "ENM";
BA_ "VNSigAllNodes" SG_ 1017 ACRfHiSdFldPrs 1;
BA_ "SignalLongName" SG_ 1017 ACRfHiSdFldPrs "Air Conditioning Refrigerant High Side Fluid Pressure";
BA_ "SignalType" SG_ 1017 ACRfHiSdFldPrs "UNM";
BA_ "VNSigAllNodes" SG_ 1017 GenStptDtCycPtOvrAct 1;
BA_ "SignalLongName" SG_ 1017 GenStptDtCycPtOvrAct "Generator Setpoint Duty Cycle Powertrain Override Active";
BA_ "SignalType" SG_ 1017 GenStptDtCycPtOvrAct "BLN";
BA_ "VNSigAllNodes" SG_ 1017 VehTopSpdLmtMdAct 1;
BA_ "SignalLongName" SG_ 1017 VehTopSpdLmtMdAct "Vehicle Top Speed Limit Mode Active";
BA_ "SignalType" SG_ 1017 VehTopSpdLmtMdAct "BLN";
BA_ "VNSigAllNodes" SG_ 1017 VehTopSpdLmtArbVal 1;
BA_ "SignalLongName" SG_ 1017 VehTopSpdLmtArbVal "Vehicle Top Speed Limit Arbitrated Value";
BA_ "SignalType" SG_ 1017 VehTopSpdLmtArbVal "UNM";
BA_ "VNSigAllNodes" SG_ 1017 GenFldDutCycV 1;
BA_ "SignalLongName" SG_ 1017 GenFldDutCycV "Generator Field Duty Cycle Validity";
BA_ "SignalType" SG_ 1017 GenFldDutCycV "ENM";
BA_ "VNSigAllNodes" SG_ 1017 GenFldDutCyc 1;
BA_ "SignalLongName" SG_ 1017 GenFldDutCyc "Generator Field Duty Cycle";
BA_ "SignalType" SG_ 1017 GenFldDutCyc "UNM";
BA_ "VNSigAllNodes" SG_ 1017 GenFld 1;
BA_ "SignalLongName" SG_ 1017 GenFld "Generator Failed";
BA_ "SignalType" SG_ 1017 GenFld "BLN";
BA_ "VNSigAllNodes" SG_ 1017 FlInjRlCtRstOcc 1;
BA_ "SignalLongName" SG_ 1017 FlInjRlCtRstOcc "Fuel Injected Rolling Count Reset Occurred";
BA_ "SignalType" SG_ 1017 FlInjRlCtRstOcc "BLN";
BA_ "VNSigAllNodes" SG_ 1017 FlInjRlCt 1;
BA_ "SignalLongName" SG_ 1017 FlInjRlCt "Fuel Injected Rolling Count";
BA_ "SignalType" SG_ 1017 FlInjRlCt "UNM";
BA_ "VNSigAllNodes" SG_ 1017 EngSpdLmtnMdAct 1;
BA_ "SignalLongName" SG_ 1017 EngSpdLmtnMdAct "Engine Speed Limitation Mode Active";
BA_ "SignalType" SG_ 1017 EngSpdLmtnMdAct "BLN";
BA_ "VNSigAllNodes" SG_ 1017 EngOilRmnLf 1;
BA_ "SignalLongName" SG_ 1017 EngOilRmnLf "Engine Oil Remaining Life";
BA_ "SignalType" SG_ 1017 EngOilRmnLf "UNM";
BA_ "VNSigAllNodes" SG_ 1017 EngCoolFanSpd 1;
BA_ "SignalLongName" SG_ 1017 EngCoolFanSpd "Engine Cooling Fan Speed";
BA_ "SignalType" SG_ 1017 EngCoolFanSpd "UNM";
BA_ "Prio" BO_ 977 0;
BA_ "GenMsgSendType" BO_ 977 0;
BA_ "GenMsgCycleTime" BO_ 977 100;
BA_ "MessageSubnet" BO_ 977 2;
BA_ "VNSigAllNodes" SG_ 977 AutoMdSpdLmtStat 1;
BA_ "SignalLongName" SG_ 977 AutoMdSpdLmtStat "Auto Mode Speed Limit Status";
BA_ "SignalType" SG_ 977 AutoMdSpdLmtStat "ENM";
BA_ "VNSigAllNodes" SG_ 977 FuelFltLifRstPerf 1;
BA_ "SignalLongName" SG_ 977 FuelFltLifRstPerf "Fuel Filter Life Reset Performed";
BA_ "SignalType" SG_ 977 FuelFltLifRstPerf "BLN";
BA_ "VNSigAllNodes" SG_ 977 SpdLmtrSpdWrngAct 1;
BA_ "SignalLongName" SG_ 977 SpdLmtrSpdWrngAct "Speed Limiter/Speed Warning Active";
BA_ "SignalType" SG_ 977 SpdLmtrSpdWrngAct "BLN";
BA_ "VNSigAllNodes" SG_ 977 CrsCntlDrSelSpdAct 1;
BA_ "SignalLongName" SG_ 977 CrsCntlDrSelSpdAct "Cruise Control Driver Selected Speed Active";
BA_ "SignalType" SG_ 977 CrsCntlDrSelSpdAct "BLN";
BA_ "VNSigAllNodes" SG_ 977 ACCmpNrmLdGrdAld 1;
BA_ "SignalLongName" SG_ 977 ACCmpNrmLdGrdAld "Air Conditioning Compressor Normalized Load Gradient Allowed";
BA_ "SignalType" SG_ 977 ACCmpNrmLdGrdAld "UNM";
BA_ "VNSigAllNodes" SG_ 977 ACCompCmnd 1;
BA_ "SignalLongName" SG_ 977 ACCompCmnd "Air Conditioning Compressor Command";
BA_ "SignalType" SG_ 977 ACCompCmnd "ENM";
BA_ "VNSigAllNodes" SG_ 977 EngBstPrsIndV 1;
BA_ "SignalLongName" SG_ 977 EngBstPrsIndV "Engine Boost Pressure Indication Validity";
BA_ "SignalType" SG_ 977 EngBstPrsIndV "ENM";
BA_ "VNSigAllNodes" SG_ 977 EngBstPrsInd 1;
BA_ "SignalLongName" SG_ 977 EngBstPrsInd "Engine Boost Pressure Indication";
BA_ "SignalType" SG_ 977 EngBstPrsInd "UNM";
BA_ "VNSigAllNodes" SG_ 977 EngOilLifRstPerf 1;
BA_ "SignalLongName" SG_ 977 EngOilLifRstPerf "Engine Oil Life Reset Performed";
BA_ "SignalType" SG_ 977 EngOilLifRstPerf "BLN";
BA_ "VNSigAllNodes" SG_ 977 ThrPosV 1;
BA_ "SignalLongName" SG_ 977 ThrPosV "Throttle Position Validity";
BA_ "SignalType" SG_ 977 ThrPosV "ENM";
BA_ "VNSigAllNodes" SG_ 977 ThrPos 1;
BA_ "SignalLongName" SG_ 977 ThrPos "Throttle Position";
BA_ "SignalType" SG_ 977 ThrPos "UNM";
BA_ "VNSigAllNodes" SG_ 977 InstFuelConsmpRate 1;
BA_ "SignalLongName" SG_ 977 InstFuelConsmpRate "Instantaneous Fuel Consumption Rate";
BA_ "SignalType" SG_ 977 InstFuelConsmpRate "UNM";
BA_ "VNSigAllNodes" SG_ 977 EngOilStrvtnIO 1;
BA_ "SignalLongName" SG_ 977 EngOilStrvtnIO "Engine Oil Starvation Indication On";
BA_ "SignalType" SG_ 977 EngOilStrvtnIO "BLN";
BA_ "VNSigAllNodes" SG_ 977 EngNEmsnsRelMalfAct 1;
BA_ "SignalLongName" SG_ 977 EngNEmsnsRelMalfAct "Engine Non Emissions Related Malfunction Active";
BA_ "SignalType" SG_ 977 EngNEmsnsRelMalfAct "BLN";
BA_ "VNSigAllNodes" SG_ 977 EngEmsRelMalfIndReq 1;
BA_ "SignalLongName" SG_ 977 EngEmsRelMalfIndReq "Engine Emissions Related Malfunction Indication Request";
BA_ "SignalType" SG_ 977 EngEmsRelMalfIndReq "ENM";
BA_ "VNSigAllNodes" SG_ 977 EngCstFlCutAct 1;
BA_ "SignalLongName" SG_ 977 EngCstFlCutAct "Engine Coast Fuel Cut Off Active";
BA_ "SignalType" SG_ 977 EngCstFlCutAct "BLN";
BA_ "VNSigAllNodes" SG_ 977 CrsSpdLmtrDrvSelSpd 1;
BA_ "SignalLongName" SG_ 977 CrsSpdLmtrDrvSelSpd "Cruise and Speed Limiter Driver Selected Speed";
BA_ "SignalType" SG_ 977 CrsSpdLmtrDrvSelSpd "UNM";
BA_ "Prio" BO_ 201 0;
BA_ "GenMsgSendType" BO_ 201 0;
BA_ "GenMsgCycleTime" BO_ 201 12;
BA_ "MessageSubnet" BO_ 201 2;
BA_ "VNSigAllNodes" SG_ 201 PrsElvtdIdlCntlStat 1;
BA_ "SignalLongName" SG_ 201 PrsElvtdIdlCntlStat "Personalization Elevated Idle Control Status";
BA_ "SignalType" SG_ 201 PrsElvtdIdlCntlStat "ENM";
BA_ "VNSigAllNodes" SG_ 201 Eng12vStrtrMtrCmmdOn 1;
BA_ "SignalLongName" SG_ 201 Eng12vStrtrMtrCmmdOn "Engine 12 Volt Starter Motor Commanded On";
BA_ "SignalType" SG_ 201 Eng12vStrtrMtrCmmdOn "BLN";
BA_ "VNSigAllNodes" SG_ 201 EngCntrlRunCrnkTrmSt 1;
BA_ "SignalLongName" SG_ 201 EngCntrlRunCrnkTrmSt "Engine Controller Run Crank Terminal Status";
BA_ "SignalType" SG_ 201 EngCntrlRunCrnkTrmSt "ENM";
BA_ "VNSigAllNodes" SG_ 201 EngAirIntBstPrV 1;
BA_ "SignalLongName" SG_ 201 EngAirIntBstPrV "Engine Intake Air Boost Pressure Validity";
BA_ "SignalType" SG_ 201 EngAirIntBstPrV "ENM";
BA_ "VNSigAllNodes" SG_ 201 EngAirIntBstPr 1;
BA_ "SignalLongName" SG_ 201 EngAirIntBstPr "Engine Intake Air Boost Pressure";
BA_ "SignalType" SG_ 201 EngAirIntBstPr "SNM";
BA_ "VNSigAllNodes" SG_ 201 SpdLmtrSpdWrngEnbld 1;
BA_ "SignalLongName" SG_ 201 SpdLmtrSpdWrngEnbld "Speed Limiter/Speed Warning Enabled";
BA_ "SignalType" SG_ 201 SpdLmtrSpdWrngEnbld "BLN";
BA_ "VNSigAllNodes" SG_ 201 EngCylDactEvntPndg 1;
BA_ "SignalLongName" SG_ 201 EngCylDactEvntPndg "Engine Cylinder Deactivation Event Pending";
BA_ "SignalType" SG_ 201 EngCylDactEvntPndg "BLN";
BA_ "VNSigAllNodes" SG_ 201 EngCylDeactMd 1;
BA_ "SignalLongName" SG_ 201 EngCylDeactMd "Engine Cylinder Deactivation Mode";
BA_ "SignalType" SG_ 201 EngCylDeactMd "ENM";
BA_ "VNSigAllNodes" SG_ 201 RmVhStrtEngRng 1;
BA_ "SignalLongName" SG_ 201 RmVhStrtEngRng "Remote Vehicle Start Engine Running";
BA_ "SignalType" SG_ 201 RmVhStrtEngRng "BLN";
BA_ "VNSigAllNodes" SG_ 201 PFEngSpdCmndSpcd 1;
BA_ "SignalLongName" SG_ 201 PFEngSpdCmndSpcd "Platform Engine Speed Command Superceded";
BA_ "SignalType" SG_ 201 PFEngSpdCmndSpcd "BLN";
BA_ "VNSigAllNodes" SG_ 201 DrThrtlOvrrdDetProtVal 1;
BA_ "SignalLongName" SG_ 201 DrThrtlOvrrdDetProtVal "Driver Throttle Override Detected Protection Value";
BA_ "SignalType" SG_ 201 DrThrtlOvrrdDetProtVal "UNM";
BA_ "VNSigAllNodes" SG_ 201 DrThrtlOvrdDetAlvRlCnt 1;
BA_ "SignalLongName" SG_ 201 DrThrtlOvrdDetAlvRlCnt "Driver Throttle Override Detection Alive Rolling Count";
BA_ "SignalType" SG_ 201 DrThrtlOvrdDetAlvRlCnt "UNM";
BA_ "VNSigAllNodes" SG_ 201 PltfrmEngSpdCmdInhtRq 1;
BA_ "SignalLongName" SG_ 201 PltfrmEngSpdCmdInhtRq "Platform Engine Speed Command Inhibit Request";
BA_ "SignalType" SG_ 201 PltfrmEngSpdCmdInhtRq "ENM";
BA_ "VNSigAllNodes" SG_ 201 PT_BrkPedDscrtInpStatV 1;
BA_ "SignalLongName" SG_ 201 PT_BrkPedDscrtInpStatV "Powertrain Brake Pedal Discrete Input Status Validity";
BA_ "SignalType" SG_ 201 PT_BrkPedDscrtInpStatV "ENM";
BA_ "VNSigAllNodes" SG_ 201 PT_BrkPedDscrtInpStat 1;
BA_ "SignalLongName" SG_ 201 PT_BrkPedDscrtInpStat "Powertrain Brake Pedal Discrete Input Status";
BA_ "SignalType" SG_ 201 PT_BrkPedDscrtInpStat "ENM";
BA_ "VNSigAllNodes" SG_ 201 AccActPos 1;
BA_ "SignalLongName" SG_ 201 AccActPos "Accelerator Actual Position";
BA_ "SignalType" SG_ 201 AccActPos "UNM";
BA_ "VNSigAllNodes" SG_ 201 CrsCntEnbld 1;
BA_ "SignalLongName" SG_ 201 CrsCntEnbld "Cruise Control Enabled";
BA_ "SignalType" SG_ 201 CrsCntEnbld "BLN";
BA_ "VNSigAllNodes" SG_ 201 CrsCntAtv 1;
BA_ "SignalLongName" SG_ 201 CrsCntAtv "Cruise Control Active";
BA_ "SignalType" SG_ 201 CrsCntAtv "BLN";
BA_ "VNSigAllNodes" SG_ 201 DrvThrottlOvrrdDet 1;
BA_ "SignalLongName" SG_ 201 DrvThrottlOvrrdDet "Driver Throttle Override Detected";
BA_ "SignalType" SG_ 201 DrvThrottlOvrrdDet "BLN";
BA_ "VNSigAllNodes" SG_ 201 PT_CrnkAct 1;
BA_ "SignalLongName" SG_ 201 PT_CrnkAct "Powertrain Crank Active";
BA_ "SignalType" SG_ 201 PT_CrnkAct "BLN";
BA_ "VNSigAllNodes" SG_ 201 PTRunAbrt 1;
BA_ "SignalLongName" SG_ 201 PTRunAbrt "Powertrain Run Aborted";
BA_ "SignalType" SG_ 201 PTRunAbrt "BLN";
BA_ "VNSigAllNodes" SG_ 201 PTO_PT_RunAbrtd 1;
BA_ "SignalLongName" SG_ 201 PTO_PT_RunAbrtd "Power Take Off Powertrain Run Aborted";
BA_ "SignalType" SG_ 201 PTO_PT_RunAbrtd "BLN";
BA_ "VNSigAllNodes" SG_ 201 PTCrnkAbrted 1;
BA_ "SignalLongName" SG_ 201 PTCrnkAbrted "Powertrain Crank Aborted";
BA_ "SignalType" SG_ 201 PTCrnkAbrted "BLN";
BA_ "VNSigAllNodes" SG_ 201 EngSpdStat 1;
BA_ "SignalLongName" SG_ 201 EngSpdStat "Engine Speed Status";
BA_ "SignalType" SG_ 201 EngSpdStat "ENM";
BA_ "VNSigAllNodes" SG_ 201 EngSpd 1;
BA_ "SignalLongName" SG_ 201 EngSpd "Engine Speed";
BA_ "SignalType" SG_ 201 EngSpd "UNM";
BA_ "VNSigAllNodes" SG_ 201 EngRunAtv 1;
BA_ "SignalLongName" SG_ 201 EngRunAtv "Engine Run Active";
BA_ "SignalType" SG_ 201 EngRunAtv "BLN";
BA_ "VNSigAllNodes" SG_ 201 EngIdlAtv 1;
BA_ "SignalLongName" SG_ 201 EngIdlAtv "Engine Idle Active";
BA_ "SignalType" SG_ 201 EngIdlAtv "BLN";
BA_ "VNSigAllNodes" SG_ 201 AccActPosV 1;
BA_ "SignalLongName" SG_ 201 AccActPosV "Accelerator Actual Position Validity";
BA_ "SignalType" SG_ 201 AccActPosV "ENM";
BA_ "Prio" BO_ 501 0;
BA_ "GenMsgSendType" BO_ 501 0;
BA_ "GenMsgCycleTime" BO_ 501 25;
BA_ "MessageSubnet" BO_ 501 2;
BA_ "VNSigAllNodes" SG_ 501 EngRecDwnshftIO 1;
BA_ "SignalLongName" SG_ 501 EngRecDwnshftIO "Engine Recommended Downshift Indication On";
BA_ "SignalType" SG_ 501 EngRecDwnshftIO "BLN";
BA_ "VNSigAllNodes" SG_ 501 TrnsPattSelEcnMdOCm 1;
BA_ "SignalLongName" SG_ 501 TrnsPattSelEcnMdOCm "Transmission Pattern Selection Economy Mode Override Commanded";
BA_ "SignalType" SG_ 501 TrnsPattSelEcnMdOCm "BLN";
BA_ "VNSigAllNodes" SG_ 501 CltStartSwAtvV 1;
BA_ "SignalLongName" SG_ 501 CltStartSwAtvV "Clutch Start Switch Active Validity";
BA_ "SignalType" SG_ 501 CltStartSwAtvV "ENM";
BA_ "VNSigAllNodes" SG_ 501 CltStartSwAtv 1;
BA_ "SignalLongName" SG_ 501 CltStartSwAtv "Clutch Start Switch Active";
BA_ "GenSigStartValue" SG_ 501 CltStartSwAtv 1;
BA_ "SignalType" SG_ 501 CltStartSwAtv "BLN";
BA_ "VNSigAllNodes" SG_ 501 CltchPdlActPosV 1;
BA_ "SignalLongName" SG_ 501 CltchPdlActPosV "Clutch Pedal Actual Position Validity";
BA_ "SignalType" SG_ 501 CltchPdlActPosV "ENM";
BA_ "VNSigAllNodes" SG_ 501 CltchPdlActPos 1;
BA_ "SignalLongName" SG_ 501 CltchPdlActPos "Clutch Pedal Actual Position";
BA_ "SignalType" SG_ 501 CltchPdlActPos "UNM";
BA_ "VNSigAllNodes" SG_ 501 TrnsEngdStateV 1;
BA_ "SignalLongName" SG_ 501 TrnsEngdStateV "Transmission Engaged State Validity";
BA_ "SignalType" SG_ 501 TrnsEngdStateV "ENM";
BA_ "VNSigAllNodes" SG_ 501 TrnsEngdState 1;
BA_ "SignalLongName" SG_ 501 TrnsEngdState "Transmission Engaged State";
BA_ "SignalType" SG_ 501 TrnsEngdState "ENM";
BA_ "VNSigAllNodes" SG_ 501 TrnsShftLvrLckRqd 1;
BA_ "SignalLongName" SG_ 501 TrnsShftLvrLckRqd "Transmission Shift Lever Lock Requested";
BA_ "SignalType" SG_ 501 TrnsShftLvrLckRqd "BLN";
BA_ "VNSigAllNodes" SG_ 501 TransTUDMdStat 1;
BA_ "SignalLongName" SG_ 501 TransTUDMdStat "Transmission Tap Up/Tap Down Mode Status";
BA_ "SignalType" SG_ 501 TransTUDMdStat "ENM";
BA_ "VNSigAllNodes" SG_ 501 TrnCrpMdAtv 1;
BA_ "SignalLongName" SG_ 501 TrnCrpMdAtv "Transmission Creep Mode Active";
BA_ "SignalType" SG_ 501 TrnCrpMdAtv "BLN";
BA_ "VNSigAllNodes" SG_ 501 TrnsSkpShftIO 1;
BA_ "SignalLongName" SG_ 501 TrnsSkpShftIO "Transmission Skip Shift Indication On";
BA_ "SignalType" SG_ 501 TrnsSkpShftIO "BLN";
BA_ "VNSigAllNodes" SG_ 501 TrnsSftMdStat 1;
BA_ "SignalLongName" SG_ 501 TrnsSftMdStat "Transmission Shift Mode Status";
BA_ "SignalType" SG_ 501 TrnsSftMdStat "ENM";
BA_ "VNSigAllNodes" SG_ 501 TrnsRngInhbtStat 1;
BA_ "SignalLongName" SG_ 501 TrnsRngInhbtStat "Transmission Range Inhibit Status";
BA_ "SignalType" SG_ 501 TrnsRngInhbtStat "ENM";
BA_ "VNSigAllNodes" SG_ 501 TopTrvlCltchSwActV 1;
BA_ "SignalLongName" SG_ 501 TopTrvlCltchSwActV "Top of Travel Clutch Switch Active Validity";
BA_ "SignalType" SG_ 501 TopTrvlCltchSwActV "ENM";
BA_ "VNSigAllNodes" SG_ 501 TopTrvlCltchSwAct 1;
BA_ "SignalLongName" SG_ 501 TopTrvlCltchSwAct "Top of Travel Clutch Switch Active";
BA_ "SignalType" SG_ 501 TopTrvlCltchSwAct "BLN";
BA_ "VNSigAllNodes" SG_ 501 EngRecmndUpshftIO 1;
BA_ "SignalLongName" SG_ 501 EngRecmndUpshftIO "Engine Recommended Upshift Indication On";
BA_ "SignalType" SG_ 501 EngRecmndUpshftIO "BLN";
BA_ "VNSigAllNodes" SG_ 501 DrvtShftCntrlTrgtGear 1;
BA_ "SignalLongName" SG_ 501 DrvtShftCntrlTrgtGear "Driver Shift Control Target Gear";
BA_ "SignalType" SG_ 501 DrvtShftCntrlTrgtGear "ENM";
BA_ "VNSigAllNodes" SG_ 501 DrShftCntrlReqDndIO 1;
BA_ "SignalLongName" SG_ 501 DrShftCntrlReqDndIO "Driver Shift Control Request Denied Indication On";
BA_ "SignalType" SG_ 501 DrShftCntrlReqDndIO "BLN";
BA_ "VNSigAllNodes" SG_ 501 TrnShftPtrnActStat 1;
BA_ "SignalLongName" SG_ 501 TrnShftPtrnActStat "Transmission Shift Pattern Active Status";
BA_ "SignalType" SG_ 501 TrnShftPtrnActStat "ENM";
BA_ "VNSigAllNodes" SG_ 501 TrnsFldPrsPrsnt 1;
BA_ "SignalLongName" SG_ 501 TrnsFldPrsPrsnt "Transmission Fluid Pressure Present";
BA_ "SignalType" SG_ 501 TrnsFldPrsPrsnt "BLN";
BA_ "VNSigAllNodes" SG_ 501 TrnsShftLvrPos 1;
BA_ "SignalLongName" SG_ 501 TrnsShftLvrPos "Transmission Shift Lever Position";
BA_ "SignalType" SG_ 501 TrnsShftLvrPos "ENM";
BA_ "VNSigAllNodes" SG_ 501 TrnsShftLvrPosV 1;
BA_ "SignalLongName" SG_ 501 TrnsShftLvrPosV "Transmission Shift Lever Position Validity";
BA_ "SignalType" SG_ 501 TrnsShftLvrPosV "ENM";
BA_ "VNSigAllNodes" SG_ 501 TrnsTrqCnvCltCmndMd 1;
BA_ "SignalLongName" SG_ 501 TrnsTrqCnvCltCmndMd "Transmission Torque Converter Clutch Commanded Mode";
BA_ "GenSigStartValue" SG_ 501 TrnsTrqCnvCltCmndMd 7;
BA_ "SignalType" SG_ 501 TrnsTrqCnvCltCmndMd "ENM";
BA_ "VNSigAllNodes" SG_ 501 AutoTransComndGear 1;
BA_ "SignalLongName" SG_ 501 AutoTransComndGear "Automatic Transmission Commanded Gear";
BA_ "GenSigStartValue" SG_ 501 AutoTransComndGear 15;
BA_ "SignalType" SG_ 501 AutoTransComndGear "ENM";
BA_ "VNSigAllNodes" SG_ 501 AutoTransGrSftDirect 1;
BA_ "SignalLongName" SG_ 501 AutoTransGrSftDirect "Automatic Transmission Gear Shift Direction";
BA_ "SignalType" SG_ 501 AutoTransGrSftDirect "ENM";
BA_ "VNSigAllNodes" SG_ 501 TransEstGear 1;
BA_ "SignalLongName" SG_ 501 TransEstGear "Transmission Estimated Gear";
BA_ "GenSigStartValue" SG_ 501 TransEstGear 15;
BA_ "SignalType" SG_ 501 TransEstGear "ENM";
BA_ "VNSigAllNodes" SG_ 501 TransEstGearV 1;
BA_ "SignalLongName" SG_ 501 TransEstGearV "Transmission Estimated Gear Validity";
BA_ "SignalType" SG_ 501 TransEstGearV "ENM";
BA_ "Prio" BO_ 1225 0;
BA_ "GenMsgSendType" BO_ 1225 0;
BA_ "GenMsgCycleTime" BO_ 1225 500;
BA_ "MessageSubnet" BO_ 1225 2;
BA_ "VNSigAllNodes" SG_ 1225 TCTPIR_TnsEsClCDwT 1;
BA_ "PacketOrder" SG_ 1225 TCTPIR_TnsEsClCDwT 3;
BA_ "SignalLongName" SG_ 1225 TCTPIR_TnsEsClCDwT "Transmission Clutch Thermal Protection Indication Request : Transmission Estimated Clutch Cool-down Temperature Target Display";
BA_ "SignalType" SG_ 1225 TCTPIR_TnsEsClCDwT "UNM";
BA_ "VNSigAllNodes" SG_ 1225 TCTPIR_TnsEsClTmpD 1;
BA_ "PacketOrder" SG_ 1225 TCTPIR_TnsEsClTmpD 2;
BA_ "SignalLongName" SG_ 1225 TCTPIR_TnsEsClTmpD "Transmission Clutch Thermal Protection Indication Request : Transmission Estimated Clutch Temperature Display";
BA_ "SignalType" SG_ 1225 TCTPIR_TnsEsClTmpD "UNM";
BA_ "VNSigAllNodes" SG_ 1225 TCTPIR_DrvNotfn 1;
BA_ "PacketOrder" SG_ 1225 TCTPIR_DrvNotfn 1;
BA_ "SignalLongName" SG_ 1225 TCTPIR_DrvNotfn "Transmission Clutch Thermal Protection Indication Request : Driver Notification";
BA_ "SignalType" SG_ 1225 TCTPIR_DrvNotfn "ENM";
BA_ "VNSigAllNodes" SG_ 1225 GrdBrkgAct 1;
BA_ "SignalLongName" SG_ 1225 GrdBrkgAct "Grade Braking Active";
BA_ "SignalType" SG_ 1225 GrdBrkgAct "BLN";
BA_ "VNSigAllNodes" SG_ 1225 RrPTCoolFanRatFltStat 1;
BA_ "SignalLongName" SG_ 1225 RrPTCoolFanRatFltStat "Rear Powertrain Cooling Fan Rationality Fault Status";
BA_ "SignalType" SG_ 1225 RrPTCoolFanRatFltStat "ENM";
BA_ "VNSigAllNodes" SG_ 1225 TrnsThrmlMngmntStat 1;
BA_ "SignalLongName" SG_ 1225 TrnsThrmlMngmntStat "Transmission Thermal Management Status";
BA_ "SignalType" SG_ 1225 TrnsThrmlMngmntStat "ENM";
BA_ "VNSigAllNodes" SG_ 1225 TrnsNEmsRltMalfActv 1;
BA_ "SignalLongName" SG_ 1225 TrnsNEmsRltMalfActv "Transmission Non Emissions Related Malfunction Active";
BA_ "SignalType" SG_ 1225 TrnsNEmsRltMalfActv "BLN";
BA_ "VNSigAllNodes" SG_ 1225 TransOilTempSensPres 1;
BA_ "SignalLongName" SG_ 1225 TransOilTempSensPres "Transmission Oil Temperature Sensor Present";
BA_ "SignalType" SG_ 1225 TransOilTempSensPres "BLN";
BA_ "VNSigAllNodes" SG_ 1225 TrnEmsMlfAtv 1;
BA_ "SignalLongName" SG_ 1225 TrnEmsMlfAtv "Transmission Emissions Related Malfunction Active";
BA_ "SignalType" SG_ 1225 TrnEmsMlfAtv "BLN";
BA_ "VNSigAllNodes" SG_ 1225 TrnOilTmp 1;
BA_ "SignalLongName" SG_ 1225 TrnOilTmp "Transmission Oil Temperature";
BA_ "SignalType" SG_ 1225 TrnOilTmp "UNM";
BA_ "VNSigAllNodes" SG_ 1225 TrnOilTmpV 1;
BA_ "SignalLongName" SG_ 1225 TrnOilTmpV "Transmission Oil Temperature Validity";
BA_ "SignalType" SG_ 1225 TrnOilTmpV "ENM";
BA_ "VNSigAllNodes" SG_ 1225 TERDTC_SysDes 1;
BA_ "PacketOrder" SG_ 1225 TERDTC_SysDes 1;
BA_ "SignalLongName" SG_ 1225 TERDTC_SysDes "Transmission Emissions Related DTC : System Designator";
BA_ "SignalType" SG_ 1225 TERDTC_SysDes "ENM";
BA_ "VNSigAllNodes" SG_ 1225 TERDTC_CdNum 1;
BA_ "PacketOrder" SG_ 1225 TERDTC_CdNum 2;
BA_ "SignalLongName" SG_ 1225 TERDTC_CdNum "Transmission Emissions Related DTC : Code Number";
BA_ "SignalType" SG_ 1225 TERDTC_CdNum "UNM";
BA_ "Prio" BO_ 409 0;
BA_ "GenMsgSendType" BO_ 409 0;
BA_ "GenMsgCycleTime" BO_ 409 25;
BA_ "MessageSubnet" BO_ 409 2;
BA_ "VNSigAllNodes" SG_ 409 TrnsAliveRC_199 1;
BA_ "SignalLongName" SG_ 409 TrnsAliveRC_199 "Transmission Alive Rolling Count 199";
BA_ "SignalType" SG_ 409 TrnsAliveRC_199 "UNM";
BA_ "VNSigAllNodes" SG_ 409 TDslPrtFltrIdlRgtnMdAtv 1;
BA_ "SignalLongName" SG_ 409 TDslPrtFltrIdlRgtnMdAtv "Transmission Diesel Particulate Filter Idle Regeneration Mode Active";
BA_ "SignalType" SG_ 409 TDslPrtFltrIdlRgtnMdAtv "BLN";
BA_ "VNSigAllNodes" SG_ 409 TransMinVoltReq 1;
BA_ "SignalLongName" SG_ 409 TransMinVoltReq "Transmission Minimum Voltage Request";
BA_ "SignalType" SG_ 409 TransMinVoltReq "UNM";
BA_ "VNSigAllNodes" SG_ 409 TransVehTopSpdLim 1;
BA_ "SignalLongName" SG_ 409 TransVehTopSpdLim "Transmission Vehicle Top Speed Limit Value";
BA_ "SignalType" SG_ 409 TransVehTopSpdLim "UNM";
BA_ "VNSigAllNodes" SG_ 409 TrnsTrqRqProt 1;
BA_ "SignalLongName" SG_ 409 TrnsTrqRqProt "Transmission Torque Request Protection";
BA_ "SignalType" SG_ 409 TrnsTrqRqProt "UNM";
BA_ "VNSigAllNodes" SG_ 409 TTRLT_TorqReqVal 1;
BA_ "PacketOrder" SG_ 409 TTRLT_TorqReqVal 3;
BA_ "SignalLongName" SG_ 409 TTRLT_TorqReqVal "Transmission Torque Request Long-term : Torque Request Value";
BA_ "SignalType" SG_ 409 TTRLT_TorqReqVal "UNM";
BA_ "VNSigAllNodes" SG_ 409 TTRLT_TqRdnRlznSgg 1;
BA_ "PacketOrder" SG_ 409 TTRLT_TqRdnRlznSgg 2;
BA_ "SignalLongName" SG_ 409 TTRLT_TqRdnRlznSgg "Transmission Torque Request Long-term : Torque Reduction Realization Suggestion";
BA_ "SignalType" SG_ 409 TTRLT_TqRdnRlznSgg "ENM";
BA_ "VNSigAllNodes" SG_ 409 TTRLT_TorqInvntnTyp 1;
BA_ "PacketOrder" SG_ 409 TTRLT_TorqInvntnTyp 1;
BA_ "SignalLongName" SG_ 409 TTRLT_TorqInvntnTyp "Transmission Torque Request Long-term : Torque Intervention Type";
BA_ "SignalType" SG_ 409 TTRLT_TorqInvntnTyp "ENM";
BA_ "VNSigAllNodes" SG_ 409 TTRST_TorqReqVal 1;
BA_ "PacketOrder" SG_ 409 TTRST_TorqReqVal 2;
BA_ "SignalLongName" SG_ 409 TTRST_TorqReqVal "Transmission Torque Request Short-term : Torque Request Value";
BA_ "SignalType" SG_ 409 TTRST_TorqReqVal "UNM";
BA_ "VNSigAllNodes" SG_ 409 TTRST_TorqInvntnTyp 1;
BA_ "PacketOrder" SG_ 409 TTRST_TorqInvntnTyp 1;
BA_ "SignalLongName" SG_ 409 TTRST_TorqInvntnTyp "Transmission Torque Request Short-term : Torque Intervention Type";
BA_ "SignalType" SG_ 409 TTRST_TorqInvntnTyp "ENM";
BA_ "Prio" BO_ 413 0;
BA_ "GenMsgSendType" BO_ 413 0;
BA_ "GenMsgCycleTime" BO_ 413 25;
BA_ "MessageSubnet" BO_ 413 2;
BA_ "VNSigAllNodes" SG_ 413 TrnsCyDactTransStat 1;
BA_ "SignalLongName" SG_ 413 TrnsCyDactTransStat "Transmission Cylinder Deactivation Transition Status";
BA_ "SignalType" SG_ 413 TrnsCyDactTransStat "ENM";
BA_ "VNSigAllNodes" SG_ 413 EngBrkDsblReqd 1;
BA_ "SignalLongName" SG_ 413 EngBrkDsblReqd "Engine Brake Disable Requested";
BA_ "SignalType" SG_ 413 EngBrkDsblReqd "BLN";
BA_ "VNSigAllNodes" SG_ 413 TransNtrlCntrlMdStat 1;
BA_ "SignalLongName" SG_ 413 TransNtrlCntrlMdStat "Transmission Neutral Control Mode Status";
BA_ "SignalType" SG_ 413 TransNtrlCntrlMdStat "ENM";
BA_ "VNSigAllNodes" SG_ 413 TrnsRtoCntlSysFlt 1;
BA_ "SignalLongName" SG_ 413 TrnsRtoCntlSysFlt "Transmission Ratio Control System Fault";
BA_ "SignalType" SG_ 413 TrnsRtoCntlSysFlt "BLN";
BA_ "VNSigAllNodes" SG_ 413 TrnTrbAngVl 1;
BA_ "SignalLongName" SG_ 413 TrnTrbAngVl "Transmission Turbine Angular Velocity";
BA_ "SignalType" SG_ 413 TrnTrbAngVl "UNM";
BA_ "VNSigAllNodes" SG_ 413 TrnTrbAngVlV 1;
BA_ "SignalLongName" SG_ 413 TrnTrbAngVlV "Transmission Turbine Angular Velocity Validity";
BA_ "SignalType" SG_ 413 TrnTrbAngVlV "ENM";
BA_ "VNSigAllNodes" SG_ 413 TrnGrRat 1;
BA_ "SignalLongName" SG_ 413 TrnGrRat "Transmission Gear Ratio";
BA_ "SignalType" SG_ 413 TrnGrRat "UNM";
BA_ "VNSigAllNodes" SG_ 413 TrnGrRatV 1;
BA_ "SignalLongName" SG_ 413 TrnGrRatV "Transmission Gear Ratio Validity";
BA_ "SignalType" SG_ 413 TrnGrRatV "ENM";
BA_ "VNSigAllNodes" SG_ 413 TrnPrfAlgShfAtv 1;
BA_ "SignalLongName" SG_ 413 TrnPrfAlgShfAtv "Transmission Performance Algorithm Shift Mode Active";
BA_ "SignalType" SG_ 413 TrnPrfAlgShfAtv "BLN";
BA_ "VNSigAllNodes" SG_ 413 TrnsAliveRC 1;
BA_ "SignalLongName" SG_ 413 TrnsAliveRC "Transmission Alive Rolling Count";
BA_ "SignalType" SG_ 413 TrnsAliveRC "UNM";
BA_ "VNSigAllNodes" SG_ 413 TrnsEngSpdRqProt 1;
BA_ "SignalLongName" SG_ 413 TrnsEngSpdRqProt "Transmission Engine Speed Request Protection";
BA_ "SignalType" SG_ 413 TrnsEngSpdRqProt "UNM";
BA_ "VNSigAllNodes" SG_ 413 TESR_EngSpdCntlRsp 1;
BA_ "PacketOrder" SG_ 413 TESR_EngSpdCntlRsp 2;
BA_ "SignalLongName" SG_ 413 TESR_EngSpdCntlRsp "Transmission Engine Speed Request : Engine Speed Control Response";
BA_ "SignalType" SG_ 413 TESR_EngSpdCntlRsp "ENM";
BA_ "VNSigAllNodes" SG_ 413 TESR_EngSpdRqVal 1;
BA_ "PacketOrder" SG_ 413 TESR_EngSpdRqVal 3;
BA_ "SignalLongName" SG_ 413 TESR_EngSpdRqVal "Transmission Engine Speed Request : Engine Speed Request Value";
BA_ "SignalType" SG_ 413 TESR_EngSpdRqVal "UNM";
BA_ "VNSigAllNodes" SG_ 413 TESR_EngSpdIntTyp 1;
BA_ "PacketOrder" SG_ 413 TESR_EngSpdIntTyp 1;
BA_ "SignalLongName" SG_ 413 TESR_EngSpdIntTyp "Transmission Engine Speed Request : Engine Speed Intervention Type";
BA_ "SignalType" SG_ 413 TESR_EngSpdIntTyp "ENM";
BA_ "VNSigAllNodes" SG_ 413 TrnsGrgShftAct 1;
BA_ "SignalLongName" SG_ 413 TrnsGrgShftAct "Transmission Garage Shift Active";
BA_ "SignalType" SG_ 413 TrnsGrgShftAct "BLN";
BA_ "GenMsgILSupport" BO_ 257 0;
BA_ "Prio" BO_ 257 0;
BA_ "DiagState" BO_ 257 1;
BA_ "MessageSubnet" BO_ 257 2;
BA_ "VNSigAllNodes" SG_ 257 DgnInf 1;
BA_ "VNSigSLHSSharedDiagnostic" SG_ 257 DgnInf 1;
BA_ "SignalLongName" SG_ 257 DgnInf "Diagnostic Information";
BA_ "SignalType" SG_ 257 DgnInf "UNM";
BA_ "GenMsgILSupport" BO_ 2015 0;
BA_ "Prio" BO_ 2015 0;
BA_ "MessageSubnet" BO_ 2015 2;
BA_ "VNSigAllNodes" SG_ 2015 DgnInf 1;
BA_ "VNSigSLHSSharedDiagnostic" SG_ 2015 DgnInf 1;
BA_ "SignalLongName" SG_ 2015 DgnInf "Diagnostic Information";
BA_ "SignalType" SG_ 2015 DgnInf "UNM";
BA_ "DiagRequest" BO_ 2016 1;
BA_ "Prio" BO_ 2016 0;
BA_ "MessageSubnet" BO_ 2016 2;
BA_ "VNSigAllNodes" SG_ 2016 DgnInf 1;
BA_ "VNSigSLHSSharedDiagnostic" SG_ 2016 DgnInf 1;
BA_ "SignalLongName" SG_ 2016 DgnInf "Diagnostic Information";
BA_ "SignalType" SG_ 2016 DgnInf "UNM";
BA_ "Prio" BO_ 197 0;
BA_ "GenMsgSendType" BO_ 197 0;
BA_ "GenMsgCycleTime" BO_ 197 10;
BA_ "MessageSubnet" BO_ 197 2;
BA_ "VNSigAllNodes" SG_ 197 WRSLNDWhlDisTpRC 1;
BA_ "PacketOrder" SG_ 197 WRSLNDWhlDisTpRC 1;
BA_ "SignalLongName" SG_ 197 WRSLNDWhlDisTpRC "Wheel Rotational Status Left Non Driven : Wheel Distance Timestamp Rollover Counter";
BA_ "SignalType" SG_ 197 WRSLNDWhlDisTpRC "UNM";
BA_ "VNSigAllNodes" SG_ 197 WRSLNDWhlRotStRst 1;
BA_ "PacketOrder" SG_ 197 WRSLNDWhlRotStRst 3;
BA_ "SignalLongName" SG_ 197 WRSLNDWhlRotStRst "Wheel Rotational Status Left Non Driven : Wheel Rotational Status Reset Occurred";
BA_ "SignalType" SG_ 197 WRSLNDWhlRotStRst "BLN";
BA_ "VNSigAllNodes" SG_ 197 WRSLNDWhlDistVal 1;
BA_ "PacketOrder" SG_ 197 WRSLNDWhlDistVal 4;
BA_ "SignalLongName" SG_ 197 WRSLNDWhlDistVal "Wheel Rotational Status Left Non Driven : Wheel Distance Validity";
BA_ "SignalType" SG_ 197 WRSLNDWhlDistVal "ENM";
BA_ "VNSigAllNodes" SG_ 197 WRSLNDWhlDistTstm 1;
BA_ "PacketOrder" SG_ 197 WRSLNDWhlDistTstm 6;
BA_ "SignalLongName" SG_ 197 WRSLNDWhlDistTstm "Wheel Rotational Status Left Non Driven : Wheel Distance Timestamp";
BA_ "SignalType" SG_ 197 WRSLNDWhlDistTstm "UNM";
BA_ "VNSigAllNodes" SG_ 197 WRSLNDWhlDistPCntr 1;
BA_ "PacketOrder" SG_ 197 WRSLNDWhlDistPCntr 5;
BA_ "SignalLongName" SG_ 197 WRSLNDWhlDistPCntr "Wheel Rotational Status Left Non Driven : Wheel Distance Pulse Counter";
BA_ "SignalType" SG_ 197 WRSLNDWhlDistPCntr "UNM";
BA_ "VNSigAllNodes" SG_ 197 WRSLNDSeqNum 1;
BA_ "PacketOrder" SG_ 197 WRSLNDSeqNum 2;
BA_ "SignalLongName" SG_ 197 WRSLNDSeqNum "Wheel Rotational Status Left Non Driven : Sequence Number";
BA_ "SignalType" SG_ 197 WRSLNDSeqNum "UNM";
BA_ "VNSigAllNodes" SG_ 197 WRSRNDWhlDisTpRC 1;
BA_ "PacketOrder" SG_ 197 WRSRNDWhlDisTpRC 1;
BA_ "SignalLongName" SG_ 197 WRSRNDWhlDisTpRC "Wheel Rotational Status Right Non Driven : Wheel Distance Timestamp Rollover Counter";
BA_ "SignalType" SG_ 197 WRSRNDWhlDisTpRC "UNM";
BA_ "VNSigAllNodes" SG_ 197 WRSRNDWhlRotStRst 1;
BA_ "PacketOrder" SG_ 197 WRSRNDWhlRotStRst 3;
BA_ "SignalLongName" SG_ 197 WRSRNDWhlRotStRst "Wheel Rotational Status Right Non Driven : Wheel Rotational Status Reset Occurred";
BA_ "SignalType" SG_ 197 WRSRNDWhlRotStRst "BLN";
BA_ "VNSigAllNodes" SG_ 197 WRSRNDWhlDistVal 1;
BA_ "PacketOrder" SG_ 197 WRSRNDWhlDistVal 4;
BA_ "SignalLongName" SG_ 197 WRSRNDWhlDistVal "Wheel Rotational Status Right Non Driven : Wheel Distance Validity";
BA_ "SignalType" SG_ 197 WRSRNDWhlDistVal "ENM";
BA_ "VNSigAllNodes" SG_ 197 WRSRNDWhlDistTstm 1;
BA_ "PacketOrder" SG_ 197 WRSRNDWhlDistTstm 6;
BA_ "SignalLongName" SG_ 197 WRSRNDWhlDistTstm "Wheel Rotational Status Right Non Driven : Wheel Distance Timestamp";
BA_ "SignalType" SG_ 197 WRSRNDWhlDistTstm "UNM";
BA_ "VNSigAllNodes" SG_ 197 WRSRNDWhlDistPCntr 1;
BA_ "PacketOrder" SG_ 197 WRSRNDWhlDistPCntr 5;
BA_ "SignalLongName" SG_ 197 WRSRNDWhlDistPCntr "Wheel Rotational Status Right Non Driven : Wheel Distance Pulse Counter";
BA_ "SignalType" SG_ 197 WRSRNDWhlDistPCntr "UNM";
BA_ "VNSigAllNodes" SG_ 197 WRSRNDSeqNum 1;
BA_ "PacketOrder" SG_ 197 WRSRNDSeqNum 2;
BA_ "SignalLongName" SG_ 197 WRSRNDSeqNum "Wheel Rotational Status Right Non Driven : Sequence Number";
BA_ "SignalType" SG_ 197 WRSRNDSeqNum "UNM";
BA_ "Prio" BO_ 249 0;
BA_ "GenMsgSendType" BO_ 249 0;
BA_ "GenMsgCycleTime" BO_ 249 12;
BA_ "MessageSubnet" BO_ 249 2;
BA_ "VNSigAllNodes" SG_ 249 TrnsDrvlneTqShpDisRq 1;
BA_ "SignalLongName" SG_ 249 TrnsDrvlneTqShpDisRq "Transmission Driveline Torque Shaping Disable Requested";
BA_ "SignalType" SG_ 249 TrnsDrvlneTqShpDisRq "BLN";
BA_ "VNSigAllNodes" SG_ 249 TnCCVehSpShftEvTh 1;
BA_ "SignalLongName" SG_ 249 TnCCVehSpShftEvTh "Transmission Cruise Control Vehicle Speed Shift Event Threshold";
BA_ "SignalType" SG_ 249 TnCCVehSpShftEvTh "UNM";
BA_ "VNSigAllNodes" SG_ 249 TrnsOtptRotRC 1;
BA_ "SignalLongName" SG_ 249 TrnsOtptRotRC "Transmission Output Rotations Rolling Count";
BA_ "SignalType" SG_ 249 TrnsOtptRotRC "UNM";
BA_ "VNSigAllNodes" SG_ 249 TrnsOtptRotRCRstOcc 1;
BA_ "SignalLongName" SG_ 249 TrnsOtptRotRCRstOcc "Transmission Output Rotations Rolling Count Reset Occurred";
BA_ "SignalType" SG_ 249 TrnsOtptRotRCRstOcc "BLN";
BA_ "VNSigAllNodes" SG_ 249 TrnsOtptRotRCV 1;
BA_ "SignalLongName" SG_ 249 TrnsOtptRotRCV "Transmission Output Rotations Rolling Count Validity";
BA_ "SignalType" SG_ 249 TrnsOtptRotRCV "ENM";
BA_ "VNSigAllNodes" SG_ 249 TrnsOtptShftAngVelSnrPr 1;
BA_ "SignalLongName" SG_ 249 TrnsOtptShftAngVelSnrPr "Transmission Output Shaft Angular Velocity Sensor Present";
BA_ "SignalType" SG_ 249 TrnsOtptShftAngVelSnrPr "BLN";
BA_ "VNSigAllNodes" SG_ 249 TrnsOutShftAngVel 1;
BA_ "SignalLongName" SG_ 249 TrnsOutShftAngVel "Transmission Output Shaft Angular Velocity";
BA_ "SignalType" SG_ 249 TrnsOutShftAngVel "UNM";
BA_ "VNSigAllNodes" SG_ 249 TrnsOutShftAngVelV 1;
BA_ "SignalLongName" SG_ 249 TrnsOutShftAngVelV "Transmission Output Shaft Angular Velocity Validity";
BA_ "SignalType" SG_ 249 TrnsOutShftAngVelV "ENM";
BA_ "VNSigAllNodes" SG_ 249 TrnsOvrallEstTorqRatio 1;
BA_ "SignalLongName" SG_ 249 TrnsOvrallEstTorqRatio "Transmission Overall Estimated Torque Ratio";
BA_ "SignalType" SG_ 249 TrnsOvrallEstTorqRatio "SNM";
BA_ "VNSigAllNodes" SG_ 249 TrnsOvrallEstTorqRatioV 1;
BA_ "SignalLongName" SG_ 249 TrnsOvrallEstTorqRatioV "Transmission Overall Estimated Torque Ratio Validity";
BA_ "SignalType" SG_ 249 TrnsOvrallEstTorqRatioV "ENM";
BA_ "Prio" BO_ 1009 0;
BA_ "GenMsgSendType" BO_ 1009 0;
BA_ "GenMsgCycleTime" BO_ 1009 250;
BA_ "MessageSubnet" BO_ 1009 2;
BA_ "VNSigAllNodes" SG_ 1009 ClmtCtrlHtrEngRunRq 1;
BA_ "SignalLongName" SG_ 1009 ClmtCtrlHtrEngRunRq "Climate Control Heater Engine Run Request";
BA_ "SignalType" SG_ 1009 ClmtCtrlHtrEngRunRq "ENM";
BA_ "VNSigAllNodes" SG_ 1009 OtsAirTmpCrValMsk 1;
BA_ "SignalLongName" SG_ 1009 OtsAirTmpCrValMsk "Outside Air Temperature Corrected Value Mask";
BA_ "SignalType" SG_ 1009 OtsAirTmpCrValMsk "ENM";
BA_ "VNSigAllNodes" SG_ 1009 ACCmEngRunReq 1;
BA_ "SignalLongName" SG_ 1009 ACCmEngRunReq "Air Conditioning Compressor Engine Run Request";
BA_ "SignalType" SG_ 1009 ACCmEngRunReq "ENM";
BA_ "VNSigAllNodes" SG_ 1009 OutAirTempVDA 1;
BA_ "SignalLongName" SG_ 1009 OutAirTempVDA "Outside Air Temperature Virtual Device Availability";
BA_ "GenSigStartValue" SG_ 1009 OutAirTempVDA 1;
BA_ "SignalType" SG_ 1009 OutAirTempVDA "ENM";
BA_ "VNSigAllNodes" SG_ 1009 OtsAirTmpCrValV 1;
BA_ "SignalLongName" SG_ 1009 OtsAirTmpCrValV "Outside Air Temperature Corrected Value Validity";
BA_ "SignalType" SG_ 1009 OtsAirTmpCrValV "ENM";
BA_ "VNSigAllNodes" SG_ 1009 OtsAirTmpCrVal 1;
BA_ "SignalLongName" SG_ 1009 OtsAirTmpCrVal "Outside Air Temperature Corrected Value";
BA_ "SignalType" SG_ 1009 OtsAirTmpCrVal "UNM";
BA_ "VNSigAllNodes" SG_ 1009 EngOffTmVDA 1;
BA_ "SignalLongName" SG_ 1009 EngOffTmVDA "Engine Off Time Virtual Device Availability";
BA_ "GenSigStartValue" SG_ 1009 EngOffTmVDA 1;
BA_ "SignalType" SG_ 1009 EngOffTmVDA "ENM";
BA_ "VNSigAllNodes" SG_ 1009 ClntCircPmpRq 1;
BA_ "SignalLongName" SG_ 1009 ClntCircPmpRq "Coolant Circulation Pump Request";
BA_ "SignalType" SG_ 1009 ClntCircPmpRq "ENM";
BA_ "VNSigAllNodes" SG_ 1009 IntDimDspLvl 1;
BA_ "SignalLongName" SG_ 1009 IntDimDspLvl "Interior Dimming Display Level";
BA_ "SignalType" SG_ 1009 IntDimDspLvl "UNM";
BA_ "VNSigAllNodes" SG_ 1009 EngOffTmExtRngV 1;
BA_ "SignalLongName" SG_ 1009 EngOffTmExtRngV "Engine Off Time Extended Range Validity";
BA_ "SignalType" SG_ 1009 EngOffTmExtRngV "ENM";
BA_ "VNSigAllNodes" SG_ 1009 EngOffTmExtRng 1;
BA_ "SignalLongName" SG_ 1009 EngOffTmExtRng "Engine Off Time Extended Range";
BA_ "SignalType" SG_ 1009 EngOffTmExtRng "UNM";
BA_ "VNSigAllNodes" SG_ 1009 PF_MinIdlBstLvlReq 1;
BA_ "SignalLongName" SG_ 1009 PF_MinIdlBstLvlReq "Platform Minimum Idle Boost Level Request";
BA_ "SignalType" SG_ 1009 PF_MinIdlBstLvlReq "ENM";
BA_ "VNSigAllNodes" SG_ 1009 GenRgSPDtyCycRq 1;
BA_ "SignalLongName" SG_ 1009 GenRgSPDtyCycRq "Generator Regulator Setpoint Duty Cycle Request";
BA_ "SignalType" SG_ 1009 GenRgSPDtyCycRq "UNM";
BA_ "VNSigAllNodes" SG_ 1009 VehTopSpdLmtReq 1;
BA_ "SignalLongName" SG_ 1009 VehTopSpdLmtReq "Vehicle Top Speed Limit Request";
BA_ "SignalType" SG_ 1009 VehTopSpdLmtReq "UNM";
BA_ "VNSigAllNodes" SG_ 1009 EngCoolFanSpAdj 1;
BA_ "SignalLongName" SG_ 1009 EngCoolFanSpAdj "Engine Cooling Fan Speed Adjustment";
BA_ "SignalType" SG_ 1009 EngCoolFanSpAdj "SNM";
BA_ "Prio" BO_ 1257 0;
BA_ "GenMsgSendType" BO_ 1257 0;
BA_ "GenMsgCycleTime" BO_ 1257 1000;
BA_ "MessageSubnet" BO_ 1257 2;
BA_ "VNSigAllNodes" SG_ 1257 EngPrfID 1;
BA_ "SignalLongName" SG_ 1257 EngPrfID "Engine Performance Identifier";
BA_ "SignalType" SG_ 1257 EngPrfID "UNM";
BA_ "VNSigAllNodes" SG_ 1257 ElpsdTimeCntRstOcc 1;
BA_ "SignalLongName" SG_ 1257 ElpsdTimeCntRstOcc "Elapsed Time Count Reset Occurred";
BA_ "SignalType" SG_ 1257 ElpsdTimeCntRstOcc "BLN";
BA_ "VNSigAllNodes" SG_ 1257 ElpsdTimeCnt 1;
BA_ "SignalLongName" SG_ 1257 ElpsdTimeCnt "Elapsed Time Count";
BA_ "SignalType" SG_ 1257 ElpsdTimeCnt "UNM";
BA_ "VNSigAllNodes" SG_ 1257 ACCompType 1;
BA_ "SignalLongName" SG_ 1257 ACCompType "Air Conditioning Compressor Type";
BA_ "SignalType" SG_ 1257 ACCompType "ENM";
BA_ "VNSigAllNodes" SG_ 1257 VSESysPrs 1;
BA_ "SignalLongName" SG_ 1257 VSESysPrs "Vehicle Stability Enhancement System Present";
BA_ "SignalType" SG_ 1257 VSESysPrs "BLN";
BA_ "VNSigAllNodes" SG_ 1257 ABSPr 1;
BA_ "SignalLongName" SG_ 1257 ABSPr "Antilock Brake System Present";
BA_ "SignalType" SG_ 1257 ABSPr "BLN";
BA_ "VNSigAllNodes" SG_ 1257 TCSysPr 1;
BA_ "SignalLongName" SG_ 1257 TCSysPr "Traction Control System Present";
BA_ "SignalType" SG_ 1257 TCSysPr "BLN";
BA_ "VNSigAllNodes" SG_ 1257 VehSpdCntlSystmType 1;
BA_ "SignalLongName" SG_ 1257 VehSpdCntlSystmType "Vehicle Speed Control System Type";
BA_ "SignalType" SG_ 1257 VehSpdCntlSystmType "ENM";
BA_ "VNSigAllNodes" SG_ 1257 PltfrmEngSpdCmdSysTp 1;
BA_ "SignalLongName" SG_ 1257 PltfrmEngSpdCmdSysTp "Platform Engine Speed Command System Type";
BA_ "SignalType" SG_ 1257 PltfrmEngSpdCmdSysTp "ENM";
BA_ "Prio" BO_ 505 0;
BA_ "GenMsgSendType" BO_ 505 0;
BA_ "GenMsgCycleTime" BO_ 505 30;
BA_ "MessageSubnet" BO_ 505 2;
BA_ "VNSigAllNodes" SG_ 505 AllNodesVNA_1F9 1;
BA_ "SignalLongName" SG_ 505 AllNodesVNA_1F9 "All Nodes Virtual Network Activation";
BA_ "VNSigSLHS_VNReq" SG_ 505 AllNodesVNA_1F9 1;
BA_ "SignalType" SG_ 505 AllNodesVNA_1F9 "ENM";
BA_ "VNSigAllNodes" SG_ 505 PTOVehTopSpdLimVal 1;
BA_ "SignalLongName" SG_ 505 PTOVehTopSpdLimVal "Power Take Off Vehicle Top Speed Limit Value";
BA_ "SignalType" SG_ 505 PTOVehTopSpdLimVal "UNM";
BA_ "VNSigAllNodes" SG_ 505 AccPdlPwrTkOffOvrAct 1;
BA_ "SignalLongName" SG_ 505 AccPdlPwrTkOffOvrAct "Accelerator Pedal Power Take Off Override Active";
BA_ "SignalType" SG_ 505 AccPdlPwrTkOffOvrAct "BLN";
BA_ "VNSigAllNodes" SG_ 505 PTOTGRReqdGear 1;
BA_ "PacketOrder" SG_ 505 PTOTGRReqdGear 2;
BA_ "SignalLongName" SG_ 505 PTOTGRReqdGear "Power Take Off Transmission Gear Request : Requested Gear";
BA_ "SignalType" SG_ 505 PTOTGRReqdGear "ENM";
BA_ "VNSigAllNodes" SG_ 505 PTOTGRReqType 1;
BA_ "PacketOrder" SG_ 505 PTOTGRReqType 1;
BA_ "SignalLongName" SG_ 505 PTOTGRReqType "Power Take Off Transmission Gear Request : Request Type";
BA_ "SignalType" SG_ 505 PTOTGRReqType "ENM";
BA_ "VNSigAllNodes" SG_ 505 PTORmtEngStrtReq 1;
BA_ "SignalLongName" SG_ 505 PTORmtEngStrtReq "Power Take Off Remote Engine Start Request";
BA_ "SignalType" SG_ 505 PTORmtEngStrtReq "ENM";
BA_ "VNSigAllNodes" SG_ 505 TrnsPTOCltchRelRqd 1;
BA_ "SignalLongName" SG_ 505 TrnsPTOCltchRelRqd "Transmission Power Take Off Clutch Release Requested";
BA_ "SignalType" SG_ 505 TrnsPTOCltchRelRqd "BLN";
BA_ "VNSigAllNodes" SG_ 505 FstIdlMdAct 1;
BA_ "SignalLongName" SG_ 505 FstIdlMdAct "Fast Idle Mode Active";
BA_ "SignalType" SG_ 505 FstIdlMdAct "BLN";
BA_ "VNSigAllNodes" SG_ 505 PTOMdAct 1;
BA_ "SignalLongName" SG_ 505 PTOMdAct "Power Take Off Mode Active";
BA_ "SignalType" SG_ 505 PTOMdAct "BLN";
BA_ "VNSigAllNodes" SG_ 505 PTOEngTrqLmtRchd 1;
BA_ "SignalLongName" SG_ 505 PTOEngTrqLmtRchd "Power Take Off Engine Torque Limit Requested";
BA_ "SignalType" SG_ 505 PTOEngTrqLmtRchd "BLN";
BA_ "VNSigAllNodes" SG_ 505 PTOEngTrqLmtValER 1;
BA_ "SignalLongName" SG_ 505 PTOEngTrqLmtValER "Power Take Off Engine Torque Limit Value Extended Range";
BA_ "SignalType" SG_ 505 PTOEngTrqLmtValER "UNM";
BA_ "VNSigAllNodes" SG_ 505 PltfrmEngSpdCmdMdAct 1;
BA_ "PacketOrder" SG_ 505 PltfrmEngSpdCmdMdAct 1;
BA_ "SignalLongName" SG_ 505 PltfrmEngSpdCmdMdAct "Platform Engine Speed Command : Platform Engine Speed Command Mode Active";
BA_ "SignalType" SG_ 505 PltfrmEngSpdCmdMdAct "BLN";
BA_ "VNSigAllNodes" SG_ 505 PltfrmEngSpdReq 1;
BA_ "PacketOrder" SG_ 505 PltfrmEngSpdReq 2;
BA_ "SignalLongName" SG_ 505 PltfrmEngSpdReq "Platform Engine Speed Command : Platform Engine Speed Request";
BA_ "SignalType" SG_ 505 PltfrmEngSpdReq "UNM";
BA_ "VNSigAllNodes" SG_ 505 PFESpdCmdOnSwAct 1;
BA_ "SignalLongName" SG_ 505 PFESpdCmdOnSwAct "Platform Engine Speed Command On Switch Active";
BA_ "SignalType" SG_ 505 PFESpdCmdOnSwAct "BLN";
BA_ "VNSigAllNodes" SG_ 505 PFESpdCmdDeSwAct 1;
BA_ "SignalLongName" SG_ 505 PFESpdCmdDeSwAct "Platform Engine Speed Command Speed Decrease Switch Active";
BA_ "SignalType" SG_ 505 PFESpdCmdDeSwAct "BLN";
BA_ "VNSigAllNodes" SG_ 505 PFESpdCmdInSwAct 1;
BA_ "SignalLongName" SG_ 505 PFESpdCmdInSwAct "Platform Engine Speed Command Speed Increase Switch Active";
BA_ "SignalType" SG_ 505 PFESpdCmdInSwAct "BLN";
BA_ "VNSigAllNodes" SG_ 505 PFESpdCmdSwDIntg 1;
BA_ "SignalLongName" SG_ 505 PFESpdCmdSwDIntg "Platform Engine Speed Command Switch Data Integrity";
BA_ "SignalType" SG_ 505 PFESpdCmdSwDIntg "ENM";
BA_ "VNSigAllNodes" SG_ 505 PFEngSpdCmdAlvRlgCnt 1;
BA_ "SignalLongName" SG_ 505 PFEngSpdCmdAlvRlgCnt "Platform Engine Speed Command Alive Rolling Count";
BA_ "SignalType" SG_ 505 PFEngSpdCmdAlvRlgCnt "UNM";
BA_ "VNSigAllNodes" SG_ 505 PltfrmEngSpdCmdProtVal 1;
BA_ "SignalLongName" SG_ 505 PltfrmEngSpdCmdProtVal "Platform Engine Speed Command Protection Value";
BA_ "SignalType" SG_ 505 PltfrmEngSpdCmdProtVal "UNM";
BA_ "VNSigAllNodes" SG_ 505 PTORmtEngShtdwnReqd 1;
BA_ "SignalLongName" SG_ 505 PTORmtEngShtdwnReqd "Power Take Off Remote Engine Shutdown Requested";
BA_ "SignalType" SG_ 505 PTORmtEngShtdwnReqd "BLN";
BA_ "GenMsgDelayTime" BO_ 497 30;
BA_ "Prio" BO_ 497 0;
BA_ "GenMsgSendType" BO_ 497 0;
BA_ "GenMsgCycleTime" BO_ 497 100;
BA_ "MessageSubnet" BO_ 497 2;
BA_ "VNSigAllNodes" SG_ 497 FuelFltLfRstRqd 1;
BA_ "GenSigSendType" SG_ 497 FuelFltLfRstRqd 10;
BA_ "SignalLongName" SG_ 497 FuelFltLfRstRqd "Fuel Filter Life Reset Requested";
BA_ "SignalType" SG_ 497 FuelFltLfRstRqd "BLN";
BA_ "VNSigAllNodes" SG_ 497 ACCompSysVDA 1;
BA_ "GenSigSendType" SG_ 497 ACCompSysVDA 10;
BA_ "SignalLongName" SG_ 497 ACCompSysVDA "Air Conditioning Compressor System Virtual Device Availability";
BA_ "GenSigStartValue" SG_ 497 ACCompSysVDA 1;
BA_ "SignalType" SG_ 497 ACCompSysVDA "ENM";
BA_ "VNSigAllNodes" SG_ 497 BkupPwrModeMstrVDA 1;
BA_ "GenSigSendType" SG_ 497 BkupPwrModeMstrVDA 10;
BA_ "SignalLongName" SG_ 497 BkupPwrModeMstrVDA "Backup Power Mode Master Virtual Device Availability";
BA_ "GenSigStartValue" SG_ 497 BkupPwrModeMstrVDA 1;
BA_ "SignalType" SG_ 497 BkupPwrModeMstrVDA "ENM";
BA_ "VNSigAllNodes" SG_ 497 PrkBrkVDA 1;
BA_ "GenSigSendType" SG_ 497 PrkBrkVDA 10;
BA_ "SignalLongName" SG_ 497 PrkBrkVDA "Park Brake Virtual Device Availability";
BA_ "GenSigStartValue" SG_ 497 PrkBrkVDA 1;
BA_ "SignalType" SG_ 497 PrkBrkVDA "ENM";
BA_ "VNSigAllNodes" SG_ 497 PrkBrkVDM 1;
BA_ "GenSigSendType" SG_ 497 PrkBrkVDM 10;
BA_ "SignalLongName" SG_ 497 PrkBrkVDM "Park Brake Virtual Device Mask";
BA_ "GenSigStartValue" SG_ 497 PrkBrkVDM 1;
BA_ "SignalType" SG_ 497 PrkBrkVDM "ENM";
BA_ "VNSigAllNodes" SG_ 497 BkupPwrModeMstrVDM 1;
BA_ "GenSigSendType" SG_ 497 BkupPwrModeMstrVDM 10;
BA_ "SignalLongName" SG_ 497 BkupPwrModeMstrVDM "Backup Power Mode Master Virtual Device Mask";
BA_ "SignalType" SG_ 497 BkupPwrModeMstrVDM "ENM";
BA_ "VNSigAllNodes" SG_ 497 ACCompSysVDM 1;
BA_ "GenSigSendType" SG_ 497 ACCompSysVDM 10;
BA_ "SignalLongName" SG_ 497 ACCompSysVDM "Air Conditioning Compressor System Virtual Device Mask";
BA_ "SignalType" SG_ 497 ACCompSysVDM "ENM";
BA_ "VNSigAllNodes" SG_ 497 AirbgVDA 1;
BA_ "GenSigSendType" SG_ 497 AirbgVDA 10;
BA_ "SignalLongName" SG_ 497 AirbgVDA "Airbag Virtual Device Availability";
BA_ "GenSigStartValue" SG_ 497 AirbgVDA 1;
BA_ "SignalType" SG_ 497 AirbgVDA "ENM";
BA_ "VNSigAllNodes" SG_ 497 SysBkupPwrMdEn 1;
BA_ "GenSigSendType" SG_ 497 SysBkupPwrMdEn 10;
BA_ "SignalLongName" SG_ 497 SysBkupPwrMdEn "System Backup Power Mode Enabled";
BA_ "SignalType" SG_ 497 SysBkupPwrMdEn "BLN";
BA_ "VNSigAllNodes" SG_ 497 SysBkUpPwrMd 1;
BA_ "GenSigSendType" SG_ 497 SysBkUpPwrMd 10;
BA_ "SignalLongName" SG_ 497 SysBkUpPwrMd "System Backup Power Mode";
BA_ "SignalType" SG_ 497 SysBkUpPwrMd "ENM";
BA_ "VNSigAllNodes" SG_ 497 SysPwrMd 1;
BA_ "GenSigSendType" SG_ 497 SysPwrMd 10;
BA_ "SignalLongName" SG_ 497 SysPwrMd "System Power Mode";
BA_ "SignalType" SG_ 497 SysPwrMd "ENM";
BA_ "VNSigAllNodes" SG_ 497 TrStLgMdAtv 1;
BA_ "GenSigSendType" SG_ 497 TrStLgMdAtv 10;
BA_ "SignalLongName" SG_ 497 TrStLgMdAtv "Transport Storage Logistic Mode Active";
BA_ "SignalType" SG_ 497 TrStLgMdAtv "BLN";
BA_ "VNSigAllNodes" SG_ 497 DispMeasSys 1;
BA_ "GenSigSendType" SG_ 497 DispMeasSys 10;
BA_ "SignalLongName" SG_ 497 DispMeasSys "Display Measurement System";
BA_ "SignalType" SG_ 497 DispMeasSys "ENM";
BA_ "VNSigAllNodes" SG_ 497 ACCmpsrFldOn 1;
BA_ "GenSigSendType" SG_ 497 ACCmpsrFldOn 10;
BA_ "SignalLongName" SG_ 497 ACCmpsrFldOn "Air Conditioning Compressor Failed On";
BA_ "SignalType" SG_ 497 ACCmpsrFldOn "BLN";
BA_ "VNSigAllNodes" SG_ 497 ACCompModReq 1;
BA_ "GenSigSendType" SG_ 497 ACCompModReq 10;
BA_ "SignalLongName" SG_ 497 ACCompModReq "Air Conditioning Compressor Mode Request";
BA_ "SignalType" SG_ 497 ACCompModReq "ENM";
BA_ "GenSigDeltaValue" SG_ 497 ACCompNormLd 1;
BA_ "VNSigAllNodes" SG_ 497 ACCompNormLd 1;
BA_ "GenSigSendType" SG_ 497 ACCompNormLd 12;
BA_ "SignalLongName" SG_ 497 ACCompNormLd "Air Conditioning Compressor Normalized Load";
BA_ "SignalType" SG_ 497 ACCompNormLd "UNM";
BA_ "VNSigAllNodes" SG_ 497 ACCompNormLdV 1;
BA_ "GenSigSendType" SG_ 497 ACCompNormLdV 10;
BA_ "SignalLongName" SG_ 497 ACCompNormLdV "Air Conditioning Compressor Normalized Load Validity";
BA_ "SignalType" SG_ 497 ACCompNormLdV "ENM";
BA_ "VNSigAllNodes" SG_ 497 PTORSMstrEngShtReq 1;
BA_ "GenSigSendType" SG_ 497 PTORSMstrEngShtReq 10;
BA_ "SignalLongName" SG_ 497 PTORSMstrEngShtReq "Power Take Off Remote Start Master Engine Shutdown Requested";
BA_ "SignalType" SG_ 497 PTORSMstrEngShtReq "BLN";
BA_ "VNSigAllNodes" SG_ 497 EngOilLfRstRq 1;
BA_ "GenSigSendType" SG_ 497 EngOilLfRstRq 10;
BA_ "SignalLongName" SG_ 497 EngOilLfRstRq "Engine Oil Life Reset Request";
BA_ "SignalType" SG_ 497 EngOilLfRstRq "BLN";
BA_ "VNSigAllNodes" SG_ 497 SIRDpl 1;
BA_ "GenSigSendType" SG_ 497 SIRDpl 10;
BA_ "SignalLongName" SG_ 497 SIRDpl "Airbag Deployed";
BA_ "SignalType" SG_ 497 SIRDpl "BLN";
BA_ "VNSigAllNodes" SG_ 497 PTORmStMsEngStRq 1;
BA_ "GenSigSendType" SG_ 497 PTORmStMsEngStRq 10;
BA_ "SignalLongName" SG_ 497 PTORmStMsEngStRq "Power Take Off Remote Start Master Engine Start Request";
BA_ "SignalType" SG_ 497 PTORmStMsEngStRq "ENM";
BA_ "VNSigAllNodes" SG_ 497 RmVehStrRq 1;
BA_ "GenSigSendType" SG_ 497 RmVehStrRq 10;
BA_ "SignalLongName" SG_ 497 RmVehStrRq "Remote Vehicle Start Request";
BA_ "SignalType" SG_ 497 RmVehStrRq "ENM";
BA_ "VNSigAllNodes" SG_ 497 ThrtlPrgrsnReq 1;
BA_ "GenSigSendType" SG_ 497 ThrtlPrgrsnReq 10;
BA_ "SignalLongName" SG_ 497 ThrtlPrgrsnReq "Throttle Progression Request";
BA_ "SignalType" SG_ 497 ThrtlPrgrsnReq "ENM";
BA_ "VNSigAllNodes" SG_ 497 PrkBrkSwAtv 1;
BA_ "GenSigSendType" SG_ 497 PrkBrkSwAtv 10;
BA_ "SignalLongName" SG_ 497 PrkBrkSwAtv "Park Brake Switch Active";
BA_ "SignalType" SG_ 497 PrkBrkSwAtv "BLN";
BA_ "VNSigAllNodes" SG_ 497 PMMAccTrmSt 1;
BA_ "GenSigSendType" SG_ 497 PMMAccTrmSt 10;
BA_ "SignalLongName" SG_ 497 PMMAccTrmSt "Power Mode Master Accessory Terminal Status";
BA_ "SignalType" SG_ 497 PMMAccTrmSt "ENM";
BA_ "VNSigAllNodes" SG_ 497 PMMRunCrkTrmSt 1;
BA_ "GenSigSendType" SG_ 497 PMMRunCrkTrmSt 10;
BA_ "SignalLongName" SG_ 497 PMMRunCrkTrmSt "Power Mode Master Run Crank Terminal Status";
BA_ "SignalType" SG_ 497 PMMRunCrkTrmSt "ENM";
BA_ "VNSigAllNodes" SG_ 497 ImmblzrPreRelPswdStat 1;
BA_ "GenSigSendType" SG_ 497 ImmblzrPreRelPswdStat 10;
BA_ "SignalLongName" SG_ 497 ImmblzrPreRelPswdStat "Immobilizer Pre Release Password Status";
BA_ "SignalType" SG_ 497 ImmblzrPreRelPswdStat "ENM";
BA_ "GenSigDeltaValue" SG_ 497 ImmblzrPreRelPswrd 1;
BA_ "VNSigAllNodes" SG_ 497 ImmblzrPreRelPswrd 1;
BA_ "GenSigSendType" SG_ 497 ImmblzrPreRelPswrd 12;
BA_ "SignalLongName" SG_ 497 ImmblzrPreRelPswrd "Immobilizer Pre Release Password";
BA_ "SignalType" SG_ 497 ImmblzrPreRelPswrd "UNM";
BA_ "Prio" BO_ 969 0;
BA_ "GenMsgSendType" BO_ 969 0;
BA_ "GenMsgCycleTime" BO_ 969 100;
BA_ "MessageSubnet" BO_ 969 2;
BA_ "VNSigAllNodes" SG_ 969 ImoInf 1;
BA_ "SignalLongName" SG_ 969 ImoInf "Immobilizer Information";
BA_ "SignalType" SG_ 969 ImoInf "UNM";
BA_ "Prio" BO_ 1249 0;
BA_ "GenMsgSendType" BO_ 1249 0;
BA_ "GenMsgCycleTime" BO_ 1249 1000;
BA_ "MessageSubnet" BO_ 1249 2;
BA_ "VNSigAllNodes" SG_ 1249 VehIdNmDig10_17 1;
BA_ "SignalLongName" SG_ 1249 VehIdNmDig10_17 "Vehicle Identification Number Digits 10-17";
BA_ "SignalType" SG_ 1249 VehIdNmDig10_17 "ASC";
BA_ "DiagResponse" BO_ 2024 1;
BA_ "Prio" BO_ 2024 0;
BA_ "MessageSubnet" BO_ 2024 2;
BA_ "VNSigAllNodes" SG_ 2024 DgnInf 1;
BA_ "VNSigSLHSSharedDiagnostic" SG_ 2024 DgnInf 1;
BA_ "SignalLongName" SG_ 2024 DgnInf "Diagnostic Information";
BA_ "SignalType" SG_ 2024 DgnInf "UNM";
BA_ "GenMsgILSupport" BO_ 1512 0;
BA_ "Prio" BO_ 1512 0;
BA_ "TpApplType" BO_ 1512 "DiagUUDTResponse";
BA_ "MessageSubnet" BO_ 1512 2;
BA_ "VNSigAllNodes" SG_ 1512 DgnInf 1;
BA_ "VNSigSLHSSharedDiagnostic" SG_ 1512 DgnInf 1;
BA_ "SignalLongName" SG_ 1512 DgnInf "Diagnostic Information";
BA_ "SignalType" SG_ 1512 DgnInf "UNM";
BA_ "Prio" BO_ 840 0;
BA_ "GenMsgSendType" BO_ 840 0;
BA_ "GenMsgCycleTime" BO_ 840 50;
BA_ "MessageSubnet" BO_ 840 2;
BA_ "VNSigAllNodes" SG_ 840 WhlRotDrctnlStLftDrvn 1;
BA_ "SignalLongName" SG_ 840 WhlRotDrctnlStLftDrvn "Wheel Rotational Directional Status Left Driven";
BA_ "SignalType" SG_ 840 WhlRotDrctnlStLftDrvn "ENM";
BA_ "VNSigAllNodes" SG_ 840 WhlRotDrctnlStRtDrvn 1;
BA_ "SignalLongName" SG_ 840 WhlRotDrctnlStRtDrvn "Wheel Rotational Directional Status Right Driven";
BA_ "SignalType" SG_ 840 WhlRotDrctnlStRtDrvn "ENM";
BA_ "VNSigAllNodes" SG_ 840 WhlGrndVlctyRtDrvnV 1;
BA_ "SignalLongName" SG_ 840 WhlGrndVlctyRtDrvnV "Wheel Ground Velocity Right Driven Validity";
BA_ "SignalType" SG_ 840 WhlGrndVlctyRtDrvnV "ENM";
BA_ "VNSigAllNodes" SG_ 840 WhlGrndVlctyRtDrvn 1;
BA_ "SignalLongName" SG_ 840 WhlGrndVlctyRtDrvn "Wheel Ground Velocity Right Driven";
BA_ "SignalType" SG_ 840 WhlGrndVlctyRtDrvn "UNM";
BA_ "VNSigAllNodes" SG_ 840 WhlGrndVlctyLftDrvnV 1;
BA_ "SignalLongName" SG_ 840 WhlGrndVlctyLftDrvnV "Wheel Ground Velocity Left Driven Validity";
BA_ "SignalType" SG_ 840 WhlGrndVlctyLftDrvnV "ENM";
BA_ "VNSigAllNodes" SG_ 840 WhlGrndVlctyLftDrvn 1;
BA_ "SignalLongName" SG_ 840 WhlGrndVlctyLftDrvn "Wheel Ground Velocity Left Driven";
BA_ "SignalType" SG_ 840 WhlGrndVlctyLftDrvn "UNM";
BA_ "Prio" BO_ 193 0;
BA_ "GenMsgSendType" BO_ 193 0;
BA_ "GenMsgCycleTime" BO_ 193 10;
BA_ "MessageSubnet" BO_ 193 2;
BA_ "VNSigAllNodes" SG_ 193 WRSLDWhlDisTpRC 1;
BA_ "PacketOrder" SG_ 193 WRSLDWhlDisTpRC 1;
BA_ "SignalLongName" SG_ 193 WRSLDWhlDisTpRC "Wheel Rotational Status Left Driven : Wheel Distance Timestamp Rollover Counter";
BA_ "SignalType" SG_ 193 WRSLDWhlDisTpRC "UNM";
BA_ "VNSigAllNodes" SG_ 193 WRSLDSeqNum 1;
BA_ "PacketOrder" SG_ 193 WRSLDSeqNum 2;
BA_ "SignalLongName" SG_ 193 WRSLDSeqNum "Wheel Rotational Status Left Driven : Sequence Number";
BA_ "SignalType" SG_ 193 WRSLDSeqNum "UNM";
BA_ "VNSigAllNodes" SG_ 193 WRSLDWhlDistVal 1;
BA_ "PacketOrder" SG_ 193 WRSLDWhlDistVal 4;
BA_ "SignalLongName" SG_ 193 WRSLDWhlDistVal "Wheel Rotational Status Left Driven : Wheel Distance Validity";
BA_ "SignalType" SG_ 193 WRSLDWhlDistVal "ENM";
BA_ "VNSigAllNodes" SG_ 193 WRSLDWhlRotStatRst 1;
BA_ "PacketOrder" SG_ 193 WRSLDWhlRotStatRst 3;
BA_ "SignalLongName" SG_ 193 WRSLDWhlRotStatRst "Wheel Rotational Status Left Driven : Wheel Rotational Status Reset Occurred";
BA_ "SignalType" SG_ 193 WRSLDWhlRotStatRst "BLN";
BA_ "VNSigAllNodes" SG_ 193 WRSLDWhlDistTmstm 1;
BA_ "PacketOrder" SG_ 193 WRSLDWhlDistTmstm 6;
BA_ "SignalLongName" SG_ 193 WRSLDWhlDistTmstm "Wheel Rotational Status Left Driven : Wheel Distance Timestamp";
BA_ "SignalType" SG_ 193 WRSLDWhlDistTmstm "UNM";
BA_ "VNSigAllNodes" SG_ 193 WRSLDWhlDistPlsCntr 1;
BA_ "PacketOrder" SG_ 193 WRSLDWhlDistPlsCntr 5;
BA_ "SignalLongName" SG_ 193 WRSLDWhlDistPlsCntr "Wheel Rotational Status Left Driven : Wheel Distance Pulse Counter";
BA_ "SignalType" SG_ 193 WRSLDWhlDistPlsCntr "UNM";
BA_ "VNSigAllNodes" SG_ 193 WRSRDWhlDisTpRC 1;
BA_ "PacketOrder" SG_ 193 WRSRDWhlDisTpRC 1;
BA_ "SignalLongName" SG_ 193 WRSRDWhlDisTpRC "Wheel Rotational Status Right Driven : Wheel Distance Timestamp Rollover Counter";
BA_ "SignalType" SG_ 193 WRSRDWhlDisTpRC "UNM";
BA_ "VNSigAllNodes" SG_ 193 WRSRDSeqNum 1;
BA_ "PacketOrder" SG_ 193 WRSRDSeqNum 2;
BA_ "SignalLongName" SG_ 193 WRSRDSeqNum "Wheel Rotational Status Right Driven : Sequence Number";
BA_ "SignalType" SG_ 193 WRSRDSeqNum "UNM";
BA_ "VNSigAllNodes" SG_ 193 WRSRDWhlRotStatRst 1;
BA_ "PacketOrder" SG_ 193 WRSRDWhlRotStatRst 3;
BA_ "SignalLongName" SG_ 193 WRSRDWhlRotStatRst "Wheel Rotational Status Right Driven : Wheel Rotational Status Reset Occurred";
BA_ "SignalType" SG_ 193 WRSRDWhlRotStatRst "BLN";
BA_ "VNSigAllNodes" SG_ 193 WRSRDWhlDistVal 1;
BA_ "PacketOrder" SG_ 193 WRSRDWhlDistVal 4;
BA_ "SignalLongName" SG_ 193 WRSRDWhlDistVal "Wheel Rotational Status Right Driven : Wheel Distance Validity";
BA_ "SignalType" SG_ 193 WRSRDWhlDistVal "ENM";
BA_ "VNSigAllNodes" SG_ 193 WRSRDWhlDistTmstm 1;
BA_ "PacketOrder" SG_ 193 WRSRDWhlDistTmstm 6;
BA_ "SignalLongName" SG_ 193 WRSRDWhlDistTmstm "Wheel Rotational Status Right Driven : Wheel Distance Timestamp";
BA_ "SignalType" SG_ 193 WRSRDWhlDistTmstm "UNM";
BA_ "VNSigAllNodes" SG_ 193 WRSRDWhlDistPlsCntr 1;
BA_ "PacketOrder" SG_ 193 WRSRDWhlDistPlsCntr 5;
BA_ "SignalLongName" SG_ 193 WRSRDWhlDistPlsCntr "Wheel Rotational Status Right Driven : Wheel Distance Pulse Counter";
BA_ "SignalType" SG_ 193 WRSRDWhlDistPlsCntr "UNM";
BA_ "Prio" BO_ 481 0;
BA_ "GenMsgSendType" BO_ 481 0;
BA_ "GenMsgCycleTime" BO_ 481 30;
BA_ "MessageSubnet" BO_ 481 2;
BA_ "VNSigAllNodes" SG_ 481 CrsSecSwStatPVal 1;
BA_ "SignalLongName" SG_ 481 CrsSecSwStatPVal "Cruise Secondary Switch Status Protection Value";
BA_ "SignalType" SG_ 481 CrsSecSwStatPVal "UNM";
BA_ "VNSigAllNodes" SG_ 481 CrsSecSwStatARC 1;
BA_ "SignalLongName" SG_ 481 CrsSecSwStatARC "Cruise Secondary Switch Status Alive Rolling Count";
BA_ "SignalType" SG_ 481 CrsSecSwStatARC "UNM";
BA_ "VNSigAllNodes" SG_ 481 CrsSecSwStat 1;
BA_ "SignalLongName" SG_ 481 CrsSecSwStat "Cruise Secondary Switch Status";
BA_ "SignalType" SG_ 481 CrsSecSwStat "ENM";
BA_ "VNSigAllNodes" SG_ 481 DrvSelMdSw3Sta 1;
BA_ "SignalLongName" SG_ 481 DrvSelMdSw3Sta "Driver Selected Mode Switch 3 State";
BA_ "SignalType" SG_ 481 DrvSelMdSw3Sta "ENM";
BA_ "VNSigAllNodes" SG_ 481 DrvSelMdSw2Sta 1;
BA_ "SignalLongName" SG_ 481 DrvSelMdSw2Sta "Driver Selected Mode Switch 2 State";
BA_ "SignalType" SG_ 481 DrvSelMdSw2Sta "ENM";
BA_ "VNSigAllNodes" SG_ 481 AuxHtrRq 1;
BA_ "SignalLongName" SG_ 481 AuxHtrRq "Auxiliary Heater Request";
BA_ "SignalType" SG_ 481 AuxHtrRq "ENM";
BA_ "VNSigAllNodes" SG_ 481 AuxHtrAtv 1;
BA_ "SignalLongName" SG_ 481 AuxHtrAtv "Auxiliary Heater Active";
BA_ "SignalType" SG_ 481 AuxHtrAtv "BLN";
BA_ "VNSigAllNodes" SG_ 481 DrvSelMdSwStaARC 1;
BA_ "SignalLongName" SG_ 481 DrvSelMdSwStaARC "Driver Selected Mode Switch State Alive Rolling Count";
BA_ "SignalType" SG_ 481 DrvSelMdSwStaARC "UNM";
BA_ "VNSigAllNodes" SG_ 481 DrvSelMdSw1Sta 1;
BA_ "SignalLongName" SG_ 481 DrvSelMdSw1Sta "Driver Selected Mode Switch 1 State";
BA_ "SignalType" SG_ 481 DrvSelMdSw1Sta "ENM";
BA_ "VNSigAllNodes" SG_ 481 CrsSpdLmtrSwStatPVal 1;
BA_ "SignalLongName" SG_ 481 CrsSpdLmtrSwStatPVal "Cruise and Speed Limiter Switch Status Protection Value";
BA_ "SignalType" SG_ 481 CrsSpdLmtrSwStatPVal "UNM";
BA_ "VNSigAllNodes" SG_ 481 CrsSpdLmtrSwStatARC 1;
BA_ "SignalLongName" SG_ 481 CrsSpdLmtrSwStatARC "Cruise and Speed Limiter Switch Status Alive Rolling Count";
BA_ "SignalType" SG_ 481 CrsSpdLmtrSwStatARC "UNM";
BA_ "VNSigAllNodes" SG_ 481 FuelMdSwActV 1;
BA_ "SignalLongName" SG_ 481 FuelMdSwActV "Fuel Mode Switch Active Validity";
BA_ "SignalType" SG_ 481 FuelMdSwActV "ENM";
BA_ "VNSigAllNodes" SG_ 481 FuelMdSwAct 1;
BA_ "SignalLongName" SG_ 481 FuelMdSwAct "Fuel Mode Switch Active";
BA_ "SignalType" SG_ 481 FuelMdSwAct "ENM";
BA_ "VNSigAllNodes" SG_ 481 CrsSpdLmtrSwStat 1;
BA_ "SignalLongName" SG_ 481 CrsSpdLmtrSwStat "Cruise and Speed Limiter Switch Status";
BA_ "SignalType" SG_ 481 CrsSpdLmtrSwStat "ENM";
BA_ "VNSigAllNodes" SG_ 481 AdptCrsGapSwAct 1;
BA_ "SignalLongName" SG_ 481 AdptCrsGapSwAct "Adaptive Cruise Control Gap Switch Activation";
BA_ "SignalType" SG_ 481 AdptCrsGapSwAct "ENM";
BA_ "VNSigAllNodes" SG_ 481 CrsCntrlSwStCanSwAct 1;
BA_ "PacketOrder" SG_ 481 CrsCntrlSwStCanSwAct 1;
BA_ "SignalLongName" SG_ 481 CrsCntrlSwStCanSwAct "Cruise Control Switch Status : Cancel Switch Active";
BA_ "SignalType" SG_ 481 CrsCntrlSwStCanSwAct "BLN";
BA_ "VNSigAllNodes" SG_ 481 CrsCntrlSwStSwDataIntgty 1;
BA_ "PacketOrder" SG_ 481 CrsCntrlSwStSwDataIntgty 7;
BA_ "SignalLongName" SG_ 481 CrsCntrlSwStSwDataIntgty "Cruise Control Switch Status : Switch Data Integrity";
BA_ "SignalType" SG_ 481 CrsCntrlSwStSwDataIntgty "ENM";
BA_ "VNSigAllNodes" SG_ 481 CrsCntrlSwStSpdInSwAct 1;
BA_ "PacketOrder" SG_ 481 CrsCntrlSwStSpdInSwAct 5;
BA_ "SignalLongName" SG_ 481 CrsCntrlSwStSpdInSwAct "Cruise Control Switch Status : Speed Increase Switch Active";
BA_ "SignalType" SG_ 481 CrsCntrlSwStSpdInSwAct "BLN";
BA_ "VNSigAllNodes" SG_ 481 CrsCntrlSwStSpDcSwAct 1;
BA_ "PacketOrder" SG_ 481 CrsCntrlSwStSpDcSwAct 6;
BA_ "SignalLongName" SG_ 481 CrsCntrlSwStSpDcSwAct "Cruise Control Switch Status : Speed Decrease Switch Active";
BA_ "SignalType" SG_ 481 CrsCntrlSwStSpDcSwAct "BLN";
BA_ "VNSigAllNodes" SG_ 481 CrsCntrlSwStSetSwAct 1;
BA_ "PacketOrder" SG_ 481 CrsCntrlSwStSetSwAct 4;
BA_ "SignalLongName" SG_ 481 CrsCntrlSwStSetSwAct "Cruise Control Switch Status : Set Switch Active";
BA_ "SignalType" SG_ 481 CrsCntrlSwStSetSwAct "BLN";
BA_ "VNSigAllNodes" SG_ 481 CrsCntrlSwStResSwAct 1;
BA_ "PacketOrder" SG_ 481 CrsCntrlSwStResSwAct 3;
BA_ "SignalLongName" SG_ 481 CrsCntrlSwStResSwAct "Cruise Control Switch Status : Resume Switch Active";
BA_ "SignalType" SG_ 481 CrsCntrlSwStResSwAct "BLN";
BA_ "VNSigAllNodes" SG_ 481 CrsCntrlSwStOnSwAct 1;
BA_ "PacketOrder" SG_ 481 CrsCntrlSwStOnSwAct 2;
BA_ "SignalLongName" SG_ 481 CrsCntrlSwStOnSwAct "Cruise Control Switch Status : On Switch Active";
BA_ "SignalType" SG_ 481 CrsCntrlSwStOnSwAct "BLN";
BA_ "VNSigAllNodes" SG_ 481 CrsCntrlSwStatProtValue 1;
BA_ "SignalLongName" SG_ 481 CrsCntrlSwStatProtValue "Cruise Control Switch Status Protection Value";
BA_ "SignalType" SG_ 481 CrsCntrlSwStatProtValue "UNM";
BA_ "VNSigAllNodes" SG_ 481 CrsCntrlSwStAlvRollCnt 1;
BA_ "SignalLongName" SG_ 481 CrsCntrlSwStAlvRollCnt "Cruise Control Switch Status Alive Rolling Count";
BA_ "SignalType" SG_ 481 CrsCntrlSwStAlvRollCnt "UNM";
BA_ "VNSigAllNodes" SG_ 481 CrsCntCncRq 1;
BA_ "SignalLongName" SG_ 481 CrsCntCncRq "Cruise Control Cancel Request";
BA_ "SignalType" SG_ 481 CrsCntCncRq "ENM";
BA_ "Prio" BO_ 455 0;
BA_ "GenMsgSendType" BO_ 455 0;
BA_ "GenMsgCycleTime" BO_ 455 20;
BA_ "MessageSubnet" BO_ 455 2;
BA_ "VNSigAllNodes" SG_ 455 CSETRER_TorqReqVal 1;
BA_ "PacketOrder" SG_ 455 CSETRER_TorqReqVal 2;
BA_ "SignalLongName" SG_ 455 CSETRER_TorqReqVal "Chassis System Engine Torque Request Extended Range : Torque Request Value";
BA_ "SignalType" SG_ 455 CSETRER_TorqReqVal "UNM";
BA_ "VNSigAllNodes" SG_ 455 CSETRER_TqIntvnTyp 1;
BA_ "PacketOrder" SG_ 455 CSETRER_TqIntvnTyp 1;
BA_ "SignalLongName" SG_ 455 CSETRER_TqIntvnTyp "Chassis System Engine Torque Request Extended Range : Torque Intervention Type";
BA_ "SignalType" SG_ 455 CSETRER_TqIntvnTyp "ENM";
BA_ "VNSigAllNodes" SG_ 455 TracCntrlMaxTorqIncRt 1;
BA_ "SignalLongName" SG_ 455 TracCntrlMaxTorqIncRt "Traction Control Maximum Torque Increase Rate";
BA_ "SignalType" SG_ 455 TracCntrlMaxTorqIncRt "UNM";
BA_ "VNSigAllNodes" SG_ 455 TCAliveRC 1;
BA_ "SignalLongName" SG_ 455 TCAliveRC "Traction Control Alive Rolling Count";
BA_ "SignalType" SG_ 455 TCAliveRC "UNM";
BA_ "VNSigAllNodes" SG_ 455 ChsSysEngTrqReqProt 1;
BA_ "SignalLongName" SG_ 455 ChsSysEngTrqReqProt "Chassis System Engine Torque Request Protection";
BA_ "SignalType" SG_ 455 ChsSysEngTrqReqProt "UNM";
BA_ "Prio" BO_ 761 0;
BA_ "GenMsgSendType" BO_ 761 0;
BA_ "GenMsgCycleTime" BO_ 761 50;
BA_ "MessageSubnet" BO_ 761 2;
BA_ "VNSigAllNodes" SG_ 761 AutoBrkFeatInhbtPVal 1;
BA_ "SignalLongName" SG_ 761 AutoBrkFeatInhbtPVal "Automatic Braking Feature Inhibit Protection Value";
BA_ "SignalType" SG_ 761 AutoBrkFeatInhbtPVal "UNM";
BA_ "VNSigAllNodes" SG_ 761 AutoBrkFeatInhbtARC 1;
BA_ "SignalLongName" SG_ 761 AutoBrkFeatInhbtARC "Automatic Braking Feature Inhibit Alive Rolling Count";
BA_ "SignalType" SG_ 761 AutoBrkFeatInhbtARC "UNM";
BA_ "VNSigAllNodes" SG_ 761 ABFI_CollPrepSysInhbt 1;
BA_ "PacketOrder" SG_ 761 ABFI_CollPrepSysInhbt 2;
BA_ "SignalLongName" SG_ 761 ABFI_CollPrepSysInhbt "Automatic Braking Feature Inhibit : Collision Preparation System Inhibit";
BA_ "SignalType" SG_ 761 ABFI_CollPrepSysInhbt "BLN";
BA_ "VNSigAllNodes" SG_ 761 ABFI_RrVirtlBmprInh 1;
BA_ "PacketOrder" SG_ 761 ABFI_RrVirtlBmprInh 1;
BA_ "SignalLongName" SG_ 761 ABFI_RrVirtlBmprInh "Automatic Braking Feature Inhibit : Rear Virtual Bumper Inhibit";
BA_ "SignalType" SG_ 761 ABFI_RrVirtlBmprInh "BLN";
BA_ "VNSigAllNodes" SG_ 761 BrkPdlDrvApplPresV 1;
BA_ "SignalLongName" SG_ 761 BrkPdlDrvApplPresV "Brake Pedal Driver Applied Pressure Validity";
BA_ "SignalType" SG_ 761 BrkPdlDrvApplPresV "ENM";
BA_ "VNSigAllNodes" SG_ 761 BrkPdlDrvApplPres 1;
BA_ "SignalLongName" SG_ 761 BrkPdlDrvApplPres "Brake Pedal Driver Applied Pressure";
BA_ "SignalType" SG_ 761 BrkPdlDrvApplPres "UNM";
BA_ "VNSigAllNodes" SG_ 761 AutoBrkPTReqStat 1;
BA_ "SignalLongName" SG_ 761 AutoBrkPTReqStat "Automatic Braking Powertrain Request Status";
BA_ "SignalType" SG_ 761 AutoBrkPTReqStat "ENM";
BA_ "VNSigAllNodes" SG_ 761 WhlSpdSnsgDTCIndex 1;
BA_ "PacketOrder" SG_ 761 WhlSpdSnsgDTCIndex 1;
BA_ "SignalLongName" SG_ 761 WhlSpdSnsgDTCIndex "Wheel Speed Sensing Legislated Diagnostic Status : Diagnostic Trouble Code Index";
BA_ "SignalType" SG_ 761 WhlSpdSnsgDTCIndex "UNM";
BA_ "VNSigAllNodes" SG_ 761 WhlSpdSnsgDTCStat 1;
BA_ "PacketOrder" SG_ 761 WhlSpdSnsgDTCStat 2;
BA_ "SignalLongName" SG_ 761 WhlSpdSnsgDTCStat "Wheel Speed Sensing Legislated Diagnostic Status : Diagnostic Trouble Code Status";
BA_ "SignalType" SG_ 761 WhlSpdSnsgDTCStat "ENM";
BA_ "VNSigAllNodes" SG_ 761 SprTireSt 1;
BA_ "SignalLongName" SG_ 761 SprTireSt "Spare Tire Status";
BA_ "SignalType" SG_ 761 SprTireSt "ENM";
BA_ "Prio" BO_ 489 0;
BA_ "GenMsgSendType" BO_ 489 0;
BA_ "GenMsgCycleTime" BO_ 489 20;
BA_ "MessageSubnet" BO_ 489 2;
BA_ "VNSigAllNodes" SG_ 489 EnhDrvMdSwChUseRq 1;
BA_ "SignalLongName" SG_ 489 EnhDrvMdSwChUseRq "Enhanced Driver Selected Mode Switch Chassis Use Requested";
BA_ "SignalType" SG_ 489 EnhDrvMdSwChUseRq "BLN";
BA_ "VNSigAllNodes" SG_ 489 IMUDataMsk 1;
BA_ "SignalLongName" SG_ 489 IMUDataMsk "Inertial Measurement Unit Data Mask";
BA_ "SignalType" SG_ 489 IMUDataMsk "BLN";
BA_ "VNSigAllNodes" SG_ 489 DrvIndpntBrkAppAct 1;
BA_ "SignalLongName" SG_ 489 DrvIndpntBrkAppAct "Driver Independent Brake Apply Active";
BA_ "SignalType" SG_ 489 DrvIndpntBrkAppAct "BLN";
BA_ "VNSigAllNodes" SG_ 489 WhlSlpSt 1;
BA_ "SignalLongName" SG_ 489 WhlSlpSt "Wheel Slip Status";
BA_ "SignalType" SG_ 489 WhlSlpSt "ENM";
BA_ "VNSigAllNodes" SG_ 489 BSTGRReqdGear 1;
BA_ "PacketOrder" SG_ 489 BSTGRReqdGear 2;
BA_ "SignalLongName" SG_ 489 BSTGRReqdGear "Brake System Transmission Gear Request : Requested Gear";
BA_ "SignalType" SG_ 489 BSTGRReqdGear "ENM";
BA_ "VNSigAllNodes" SG_ 489 BSTGRReqType 1;
BA_ "PacketOrder" SG_ 489 BSTGRReqType 1;
BA_ "SignalLongName" SG_ 489 BSTGRReqType "Brake System Transmission Gear Request : Request Type";
BA_ "SignalType" SG_ 489 BSTGRReqType "ENM";
BA_ "VNSigAllNodes" SG_ 489 VehDynOvrUndrStr 1;
BA_ "SignalLongName" SG_ 489 VehDynOvrUndrStr "Vehicle Dynamics Over Under Steer";
BA_ "SignalType" SG_ 489 VehDynOvrUndrStr "SNM";
BA_ "VNSigAllNodes" SG_ 489 VSELatAccV 1;
BA_ "SignalLongName" SG_ 489 VSELatAccV "Vehicle Stability Enhancement Lateral Acceleration Validity";
BA_ "SignalType" SG_ 489 VSELatAccV "ENM";
BA_ "VNSigAllNodes" SG_ 489 VSELatAcc 1;
BA_ "SignalLongName" SG_ 489 VSELatAcc "Vehicle Stability Enhancement Lateral Acceleration";
BA_ "SignalType" SG_ 489 VSELatAcc "SNM";
BA_ "VNSigAllNodes" SG_ 489 VSEAct 1;
BA_ "SignalLongName" SG_ 489 VSEAct "Vehicle Stability Enhancement System Active";
BA_ "SignalType" SG_ 489 VSEAct "BLN";
BA_ "VNSigAllNodes" SG_ 489 VhDynCntlSysSt 1;
BA_ "SignalLongName" SG_ 489 VhDynCntlSysSt "Vehicle Dynamics Control System Status";
BA_ "SignalType" SG_ 489 VhDynCntlSysSt "ENM";
BA_ "VNSigAllNodes" SG_ 489 VehDynYawRateV 1;
BA_ "SignalLongName" SG_ 489 VehDynYawRateV "Vehicle Dynamics Yaw Rate Validity";
BA_ "SignalType" SG_ 489 VehDynYawRateV "ENM";
BA_ "VNSigAllNodes" SG_ 489 VehDynYawRate 1;
BA_ "SignalLongName" SG_ 489 VehDynYawRate "Vehicle Dynamics Yaw Rate";
BA_ "SignalType" SG_ 489 VehDynYawRate "SNM";
BA_ "VNSigAllNodes" SG_ 489 TrnsBrkSysCltchRelRqd 1;
BA_ "SignalLongName" SG_ 489 TrnsBrkSysCltchRelRqd "Transmission Brake System Clutch Release Requested";
BA_ "SignalType" SG_ 489 TrnsBrkSysCltchRelRqd "BLN";
BA_ "VNSigAllNodes" SG_ 489 TracCntrlSysDrIntnt 1;
BA_ "SignalLongName" SG_ 489 TracCntrlSysDrIntnt "Traction Control System Driver Intent";
BA_ "SignalType" SG_ 489 TracCntrlSysDrIntnt "ENM";
BA_ "VNSigAllNodes" SG_ 489 VehDynOvrUndrStrV 1;
BA_ "SignalLongName" SG_ 489 VehDynOvrUndrStrV "Vehicle Dynamics Over Under Steer Validity";
BA_ "SignalType" SG_ 489 VehDynOvrUndrStrV "ENM";
BA_ "VNSigAllNodes" SG_ 489 TCSysEnbld 1;
BA_ "SignalLongName" SG_ 489 TCSysEnbld "Traction Control System Enabled";
BA_ "SignalType" SG_ 489 TCSysEnbld "BLN";
BA_ "VNSigAllNodes" SG_ 489 TCSysAtv 1;
BA_ "SignalLongName" SG_ 489 TCSysAtv "Traction Control System Active";
BA_ "SignalType" SG_ 489 TCSysAtv "BLN";
BA_ "VNSigAllNodes" SG_ 489 BrkPdlDrvAppPrsDetcdV 1;
BA_ "SignalLongName" SG_ 489 BrkPdlDrvAppPrsDetcdV "Brake Pedal Driver Applied Pressure Detected Validity";
BA_ "SignalType" SG_ 489 BrkPdlDrvAppPrsDetcdV "ENM";
BA_ "VNSigAllNodes" SG_ 489 BrkPdlDrvAppPrsDetcd 1;
BA_ "SignalLongName" SG_ 489 BrkPdlDrvAppPrsDetcd "Brake Pedal Driver Applied Pressure Detected";
BA_ "GenSigStartValue" SG_ 489 BrkPdlDrvAppPrsDetcd 1;
BA_ "SignalType" SG_ 489 BrkPdlDrvAppPrsDetcd "BLN";
BA_ "VNSigAllNodes" SG_ 489 ACCBrkngAct 1;
BA_ "SignalLongName" SG_ 489 ACCBrkngAct "Adaptive Cruise Control Braking Active";
BA_ "SignalType" SG_ 489 ACCBrkngAct "BLN";
BA_ "VNSigAllNodes" SG_ 489 ABSFld 1;
BA_ "SignalLongName" SG_ 489 ABSFld "Antilock Brake System Failed";
BA_ "SignalType" SG_ 489 ABSFld "BLN";
BA_ "VNSigAllNodes" SG_ 489 ABSAtv 1;
BA_ "SignalLongName" SG_ 489 ABSAtv "Antilock Brake System Active";
BA_ "SignalType" SG_ 489 ABSAtv "BLN";
BA_ "Prio" BO_ 381 0;
BA_ "GenMsgSendType" BO_ 381 0;
BA_ "GenMsgCycleTime" BO_ 381 100;
BA_ "MessageSubnet" BO_ 381 2;
BA_ "VNSigAllNodes" SG_ 381 HillDesCtrlRedVehSpIO 1;
BA_ "SignalLongName" SG_ 381 HillDesCtrlRedVehSpIO "Hill Descent Control Reduce Vehicle Speed Indication On";
BA_ "SignalType" SG_ 381 HillDesCtrlRedVehSpIO "BLN";
BA_ "VNSigAllNodes" SG_ 381 EBDFailed 1;
BA_ "SignalLongName" SG_ 381 EBDFailed "Electronic Brake Distribution Failed";
BA_ "SignalType" SG_ 381 EBDFailed "BLN";
BA_ "VNSigAllNodes" SG_ 381 StWhAnVDA 1;
BA_ "SignalLongName" SG_ 381 StWhAnVDA "Steering Wheel Angle Virtual Device Availability";
BA_ "GenSigStartValue" SG_ 381 StWhAnVDA 1;
BA_ "SignalType" SG_ 381 StWhAnVDA "ENM";
BA_ "VNSigAllNodes" SG_ 381 TirePrsLowIO 1;
BA_ "SignalLongName" SG_ 381 TirePrsLowIO "Tire Pressure Low Indication On";
BA_ "SignalType" SG_ 381 TirePrsLowIO "BLN";
BA_ "VNSigAllNodes" SG_ 381 VaccBoostFailure 1;
BA_ "SignalLongName" SG_ 381 VaccBoostFailure "Vaccum Boost Failure";
BA_ "SignalType" SG_ 381 VaccBoostFailure "BLN";
BA_ "VNSigAllNodes" SG_ 381 VSESysPrs 1;
BA_ "SignalLongName" SG_ 381 VSESysPrs "Vehicle Stability Enhancement System Present";
BA_ "SignalType" SG_ 381 VSESysPrs "BLN";
BA_ "VNSigAllNodes" SG_ 381 HalfSysFail 1;
BA_ "SignalLongName" SG_ 381 HalfSysFail "Half System Failure";
BA_ "SignalType" SG_ 381 HalfSysFail "BLN";
BA_ "VNSigAllNodes" SG_ 381 ActVehAccel 1;
BA_ "SignalLongName" SG_ 381 ActVehAccel "Actual Vehicle Acceleration";
BA_ "SignalType" SG_ 381 ActVehAccel "SNM";
BA_ "VNSigAllNodes" SG_ 381 ActVehAccelV 1;
BA_ "SignalLongName" SG_ 381 ActVehAccelV "Actual Vehicle Acceleration Validity";
BA_ "SignalType" SG_ 381 ActVehAccelV "ENM";
BA_ "VNSigAllNodes" SG_ 381 BksOvht 1;
BA_ "SignalLongName" SG_ 381 BksOvht "Brakes Overheated";
BA_ "SignalType" SG_ 381 BksOvht "BLN";
BA_ "VNSigAllNodes" SG_ 381 TCSysPr 1;
BA_ "SignalLongName" SG_ 381 TCSysPr "Traction Control System Present";
BA_ "SignalType" SG_ 381 TCSysPr "BLN";
BA_ "VNSigAllNodes" SG_ 381 ABSPr 1;
BA_ "SignalLongName" SG_ 381 ABSPr "Antilock Brake System Present";
BA_ "SignalType" SG_ 381 ABSPr "BLN";
BA_ "VNSigAllNodes" SG_ 381 TreInfMonSysRstPrfmd 1;
BA_ "SignalLongName" SG_ 381 TreInfMonSysRstPrfmd "Tire Inflation Monitoring System Reset Performed";
BA_ "SignalType" SG_ 381 TreInfMonSysRstPrfmd "BLN";
BA_ "VNSigAllNodes" SG_ 381 ABSIO 1;
BA_ "SignalLongName" SG_ 381 ABSIO "Antilock Brake System Indication On";
BA_ "SignalType" SG_ 381 ABSIO "BLN";
BA_ "VNSigAllNodes" SG_ 381 BrkPadWrnIO 1;
BA_ "SignalLongName" SG_ 381 BrkPadWrnIO "Brake Pad Worn Indication On";
BA_ "SignalType" SG_ 381 BrkPadWrnIO "BLN";
BA_ "VNSigAllNodes" SG_ 381 VehStabEnhmntMd 1;
BA_ "SignalLongName" SG_ 381 VehStabEnhmntMd "Vehicle Stability Enhancement Mode";
BA_ "SignalType" SG_ 381 VehStabEnhmntMd "ENM";
BA_ "VNSigAllNodes" SG_ 381 VehStabEnhmntStat 1;
BA_ "SignalLongName" SG_ 381 VehStabEnhmntStat "Vehicle Stability Enhancement Status";
BA_ "SignalType" SG_ 381 VehStabEnhmntStat "ENM";
BA_ "VNSigAllNodes" SG_ 381 TCSysOpMd 1;
BA_ "SignalLongName" SG_ 381 TCSysOpMd "Traction Control System Operating Mode";
BA_ "SignalType" SG_ 381 TCSysOpMd "ENM";
BA_ "VNSigAllNodes" SG_ 381 TCSysOpStat 1;
BA_ "SignalLongName" SG_ 381 TCSysOpStat "Traction Control System Operating Status";
BA_ "SignalType" SG_ 381 TCSysOpStat "ENM";
BA_ "VNSigAllNodes" SG_ 381 BrkSysVTopSpdLimVal 1;
BA_ "SignalLongName" SG_ 381 BrkSysVTopSpdLimVal "Braking System Vehicle Top Speed Limit Value";
BA_ "GenSigStartValue" SG_ 381 BrkSysVTopSpdLimVal 255;
BA_ "SignalType" SG_ 381 BrkSysVTopSpdLimVal "UNM";
BA_ "VNSigAllNodes" SG_ 381 BrkSysRedBrkTlltlReq 1;
BA_ "SignalLongName" SG_ 381 BrkSysRedBrkTlltlReq "Brake System Red Brake Telltale Request";
BA_ "SignalType" SG_ 381 BrkSysRedBrkTlltlReq "BLN";
BA_ "VNSigAllNodes" SG_ 381 BrkSysBrkLtsReqd 1;
BA_ "SignalLongName" SG_ 381 BrkSysBrkLtsReqd "Brake System Brake Lights Requested";
BA_ "SignalType" SG_ 381 BrkSysBrkLtsReqd "BLN";
BA_ "Prio" BO_ 241 0;
BA_ "GenMsgSendType" BO_ 241 0;
BA_ "GenMsgCycleTime" BO_ 241 10;
BA_ "MessageSubnet" BO_ 241 2;
BA_ "VNSigAllNodes" SG_ 241 NotEventStat 1;
BA_ "SignalLongName" SG_ 241 NotEventStat "Notification Event Status";
BA_ "SignalType" SG_ 241 NotEventStat "ENM";
BA_ "VNSigAllNodes" SG_ 241 BrkPdlChkData 1;
BA_ "SignalLongName" SG_ 241 BrkPdlChkData "Brake Pedal Check Data";
BA_ "SignalType" SG_ 241 BrkPdlChkData "UNM";
BA_ "VNSigAllNodes" SG_ 241 BrkAppSnsrHmPosLrnd 1;
BA_ "SignalLongName" SG_ 241 BrkAppSnsrHmPosLrnd "Brake Apply Sensor Home Position Learned";
BA_ "SignalType" SG_ 241 BrkAppSnsrHmPosLrnd "BLN";
BA_ "VNSigAllNodes" SG_ 241 BrkPedTrvlAchvd 1;
BA_ "PacketOrder" SG_ 241 BrkPedTrvlAchvd 1;
BA_ "SignalLongName" SG_ 241 BrkPedTrvlAchvd "Brake Pedal Initial Travel Achieved Status : Brake Pedal Initial Travel Achieved";
BA_ "SignalType" SG_ 241 BrkPedTrvlAchvd "BLN";
BA_ "VNSigAllNodes" SG_ 241 BrkPedTrvlAchvdV 1;
BA_ "PacketOrder" SG_ 241 BrkPedTrvlAchvdV 2;
BA_ "SignalLongName" SG_ 241 BrkPedTrvlAchvdV "Brake Pedal Initial Travel Achieved Status : Brake Pedal Initial Travel Achieved Validity";
BA_ "SignalType" SG_ 241 BrkPedTrvlAchvdV "ENM";
BA_ "VNSigAllNodes" SG_ 241 BrkPdlPosGrad 1;
BA_ "SignalLongName" SG_ 241 BrkPdlPosGrad "Brake Pedal Position Gradient";
BA_ "SignalType" SG_ 241 BrkPdlPosGrad "SNM";
BA_ "VNSigAllNodes" SG_ 241 BrkPdlPos 1;
BA_ "SignalLongName" SG_ 241 BrkPdlPos "Brake Pedal Position";
BA_ "SignalType" SG_ 241 BrkPdlPos "UNM";
BA_ "VNSigAllNodes" SG_ 241 BrkPedPosAlvRolngCnt 1;
BA_ "SignalLongName" SG_ 241 BrkPedPosAlvRolngCnt "Brake Pedal Position Alive Rolling Count";
BA_ "SignalType" SG_ 241 BrkPedPosAlvRolngCnt "UNM";
BA_ "VNSigAllNodes" SG_ 241 BrkPdlModTrvlV 1;
BA_ "SignalLongName" SG_ 241 BrkPdlModTrvlV "Brake Pedal Moderate Travel Achieved Validity";
BA_ "SignalType" SG_ 241 BrkPdlModTrvlV "ENM";
BA_ "VNSigAllNodes" SG_ 241 BrkPdlModTrvl 1;
BA_ "SignalLongName" SG_ 241 BrkPdlModTrvl "Brake Pedal Moderate Travel Achieved";
BA_ "SignalType" SG_ 241 BrkPdlModTrvl "BLN";
BA_ "VNSigAllNodes" SG_ 241 BrkPdlInTrvPrt 1;
BA_ "SignalLongName" SG_ 241 BrkPdlInTrvPrt "Brake Pedal Initial Travel Achieved Protection";
BA_ "SignalType" SG_ 241 BrkPdlInTrvPrt "UNM";
BA_ "DiagResponse" BO_ 2025 1;
BA_ "Prio" BO_ 2025 0;
BA_ "MessageSubnet" BO_ 2025 2;
BA_ "VNSigAllNodes" SG_ 2025 DgnInf 1;
BA_ "VNSigSLHSSharedDiagnostic" SG_ 2025 DgnInf 1;
BA_ "SignalLongName" SG_ 2025 DgnInf "Diagnostic Information";
BA_ "SignalType" SG_ 2025 DgnInf "UNM";
BA_ "DiagResponse" BO_ 2029 1;
BA_ "Prio" BO_ 2029 0;
BA_ "MessageSubnet" BO_ 2029 2;
BA_ "VNSigAllNodes" SG_ 2029 DgnInf 1;
BA_ "VNSigSLHSSharedDiagnostic" SG_ 2029 DgnInf 1;
BA_ "SignalLongName" SG_ 2029 DgnInf "Diagnostic Information";
BA_ "SignalType" SG_ 2029 DgnInf "UNM";
BA_ "DiagResponse" BO_ 2031 1;
BA_ "Prio" BO_ 2031 0;
BA_ "MessageSubnet" BO_ 2031 2;
BA_ "VNSigAllNodes" SG_ 2031 DgnInf 1;
BA_ "VNSigSLHSSharedDiagnostic" SG_ 2031 DgnInf 1;
BA_ "SignalLongName" SG_ 2031 DgnInf "Diagnostic Information";
BA_ "SignalType" SG_ 2031 DgnInf "UNM";
BA_ "GenMsgILSupport" BO_ 1513 0;
BA_ "Prio" BO_ 1513 0;
BA_ "TpApplType" BO_ 1513 "DiagUUDTResponse";
BA_ "MessageSubnet" BO_ 1513 2;
BA_ "VNSigAllNodes" SG_ 1513 DgnInf 1;
BA_ "VNSigSLHSSharedDiagnostic" SG_ 1513 DgnInf 1;
BA_ "SignalLongName" SG_ 1513 DgnInf "Diagnostic Information";
BA_ "SignalType" SG_ 1513 DgnInf "UNM";
BA_ "GenMsgILSupport" BO_ 1517 0;
BA_ "Prio" BO_ 1517 0;
BA_ "TpApplType" BO_ 1517 "DiagUUDTResponse";
BA_ "MessageSubnet" BO_ 1517 2;
BA_ "VNSigAllNodes" SG_ 1517 DgnInf 1;
BA_ "VNSigSLHSSharedDiagnostic" SG_ 1517 DgnInf 1;
BA_ "SignalLongName" SG_ 1517 DgnInf "Diagnostic Information";
BA_ "SignalType" SG_ 1517 DgnInf "UNM";
BA_ "GenMsgILSupport" BO_ 1519 0;
BA_ "Prio" BO_ 1519 0;
BA_ "TpApplType" BO_ 1519 "DiagUUDTResponse";
BA_ "MessageSubnet" BO_ 1519 2;
BA_ "VNSigAllNodes" SG_ 1519 DgnInf 1;
BA_ "VNSigSLHSSharedDiagnostic" SG_ 1519 DgnInf 1;
BA_ "SignalLongName" SG_ 1519 DgnInf "Diagnostic Information";
BA_ "SignalType" SG_ 1519 DgnInf "UNM";
BA_ "DiagResponse" BO_ 2030 1;
BA_ "Prio" BO_ 2030 0;
BA_ "MessageSubnet" BO_ 2030 2;
BA_ "VNSigAllNodes" SG_ 2030 DgnInf 1;
BA_ "VNSigSLHSSharedDiagnostic" SG_ 2030 DgnInf 1;
BA_ "SignalLongName" SG_ 2030 DgnInf "Diagnostic Information";
BA_ "SignalType" SG_ 2030 DgnInf "UNM";
BA_ "GenMsgILSupport" BO_ 1518 0;
BA_ "Prio" BO_ 1518 0;
BA_ "TpApplType" BO_ 1518 "DiagUUDTResponse";
BA_ "MessageSubnet" BO_ 1518 2;
BA_ "VNSigAllNodes" SG_ 1518 DgnInf 1;
BA_ "VNSigSLHSSharedDiagnostic" SG_ 1518 DgnInf 1;
BA_ "SignalLongName" SG_ 1518 DgnInf "Diagnostic Information";
BA_ "SignalType" SG_ 1518 DgnInf "UNM";
BA_ "GenMsgILSupport" BO_ 1346 0;
BA_ "Prio" BO_ 1346 0;
BA_ "TpApplType" BO_ 1346 "DiagUUDTResponse";
BA_ "MessageSubnet" BO_ 1346 2;
BA_ "VNSigAllNodes" SG_ 1346 DgnInf_HS542 1;
BA_ "VNSigSLHSSharedDiagnostic" SG_ 1346 DgnInf_HS542 1;
BA_ "SignalLongName" SG_ 1346 DgnInf_HS542 "Diagnostic Information HS542";
BA_ "SignalType" SG_ 1346 DgnInf_HS542 "UNM";
BA_ "GenMsgILSupport" BO_ 1353 0;
BA_ "Prio" BO_ 1353 0;
BA_ "TpApplType" BO_ 1353 "DiagUUDTResponse";
BA_ "MessageSubnet" BO_ 1353 2;
BA_ "VNSigAllNodes" SG_ 1353 DgnInf_HS549 1;
BA_ "VNSigSLHSSharedDiagnostic" SG_ 1353 DgnInf_HS549 1;
BA_ "SignalLongName" SG_ 1353 DgnInf_HS549 "Diagnostic Information HS549";
BA_ "SignalType" SG_ 1353 DgnInf_HS549 "UNM";
BA_ "DiagResponse" BO_ 1609 1;
BA_ "Prio" BO_ 1609 0;
BA_ "MessageSubnet" BO_ 1609 2;
BA_ "VNSigAllNodes" SG_ 1609 DgnInf 1;
BA_ "VNSigSLHSSharedDiagnostic" SG_ 1609 DgnInf 1;
BA_ "SignalLongName" SG_ 1609 DgnInf "Diagnostic Information";
BA_ "SignalType" SG_ 1609 DgnInf "UNM";
BA_ "DiagResponse" BO_ 1602 1;
BA_ "Prio" BO_ 1602 0;
BA_ "MessageSubnet" BO_ 1602 2;
BA_ "VNSigAllNodes" SG_ 1602 DgnInf 1;
BA_ "VNSigSLHSSharedDiagnostic" SG_ 1602 DgnInf 1;
BA_ "SignalLongName" SG_ 1602 DgnInf "Diagnostic Information";
BA_ "SignalType" SG_ 1602 DgnInf "UNM";
BA_ "DiagResponse" BO_ 2027 1;
BA_ "Prio" BO_ 2027 0;
BA_ "MessageSubnet" BO_ 2027 2;
BA_ "VNSigAllNodes" SG_ 2027 DgnInf 1;
BA_ "VNSigSLHSSharedDiagnostic" SG_ 2027 DgnInf 1;
BA_ "SignalLongName" SG_ 2027 DgnInf "Diagnostic Information";
BA_ "SignalType" SG_ 2027 DgnInf "UNM";
BA_ "GenMsgILSupport" BO_ 1515 0;
BA_ "Prio" BO_ 1515 0;
BA_ "TpApplType" BO_ 1515 "DiagUUDTResponse";
BA_ "MessageSubnet" BO_ 1515 2;
BA_ "VNSigAllNodes" SG_ 1515 DgnInf 1;
BA_ "VNSigSLHSSharedDiagnostic" SG_ 1515 DgnInf 1;
BA_ "SignalLongName" SG_ 1515 DgnInf "Diagnostic Information";
BA_ "SignalType" SG_ 1515 DgnInf "UNM";
BA_ "DiagResponse" BO_ 1614 1;
BA_ "Prio" BO_ 1614 0;
BA_ "MessageSubnet" BO_ 1614 2;
BA_ "VNSigAllNodes" SG_ 1614 DgnInf 1;
BA_ "VNSigSLHSSharedDiagnostic" SG_ 1614 DgnInf 1;
BA_ "SignalLongName" SG_ 1614 DgnInf "Diagnostic Information";
BA_ "SignalType" SG_ 1614 DgnInf "UNM";
BA_ "GenMsgILSupport" BO_ 1348 0;
BA_ "Prio" BO_ 1348 0;
BA_ "TpApplType" BO_ 1348 "DiagUUDTResponse";
BA_ "MessageSubnet" BO_ 1348 2;
BA_ "VNSigAllNodes" SG_ 1348 DgnInf_HS544 1;
BA_ "VNSigSLHSSharedDiagnostic" SG_ 1348 DgnInf_HS544 1;
BA_ "SignalLongName" SG_ 1348 DgnInf_HS544 "Diagnostic Information HS544";
BA_ "SignalType" SG_ 1348 DgnInf_HS544 "UNM";
BA_ "GenMsgILSupport" BO_ 1349 0;
BA_ "Prio" BO_ 1349 0;
BA_ "TpApplType" BO_ 1349 "DiagUUDTResponse";
BA_ "MessageSubnet" BO_ 1349 2;
BA_ "VNSigAllNodes" SG_ 1349 DgnInf_HS545 1;
BA_ "VNSigSLHSSharedDiagnostic" SG_ 1349 DgnInf_HS545 1;
BA_ "SignalLongName" SG_ 1349 DgnInf_HS545 "Diagnostic Information HS545";
BA_ "SignalType" SG_ 1349 DgnInf_HS545 "UNM";
BA_ "GenMsgILSupport" BO_ 1352 0;
BA_ "Prio" BO_ 1352 0;
BA_ "TpApplType" BO_ 1352 "DiagUUDTResponse";
BA_ "MessageSubnet" BO_ 1352 2;
BA_ "VNSigAllNodes" SG_ 1352 DgnInf_HS548 1;
BA_ "VNSigSLHSSharedDiagnostic" SG_ 1352 DgnInf_HS548 1;
BA_ "SignalLongName" SG_ 1352 DgnInf_HS548 "Diagnostic Information HS548";
BA_ "SignalType" SG_ 1352 DgnInf_HS548 "UNM";
BA_ "GenMsgILSupport" BO_ 1354 0;
BA_ "Prio" BO_ 1354 0;
BA_ "TpApplType" BO_ 1354 "DiagUUDTResponse";
BA_ "MessageSubnet" BO_ 1354 2;
BA_ "VNSigAllNodes" SG_ 1354 DgnInf_HS54A 1;
BA_ "VNSigSLHSSharedDiagnostic" SG_ 1354 DgnInf_HS54A 1;
BA_ "SignalLongName" SG_ 1354 DgnInf_HS54A "Diagnostic Information HS54A";
BA_ "SignalType" SG_ 1354 DgnInf_HS54A "UNM";
BA_ "DiagResponse" BO_ 1605 1;
BA_ "Prio" BO_ 1605 0;
BA_ "MessageSubnet" BO_ 1605 2;
BA_ "VNSigAllNodes" SG_ 1605 DgnInf 1;
BA_ "VNSigSLHSSharedDiagnostic" SG_ 1605 DgnInf 1;
BA_ "SignalLongName" SG_ 1605 DgnInf "Diagnostic Information";
BA_ "SignalType" SG_ 1605 DgnInf "UNM";
BA_ "DiagResponse" BO_ 1620 1;
BA_ "Prio" BO_ 1620 0;
BA_ "MessageSubnet" BO_ 1620 2;
BA_ "VNSigAllNodes" SG_ 1620 DgnInf 1;
BA_ "VNSigSLHSSharedDiagnostic" SG_ 1620 DgnInf 1;
BA_ "SignalLongName" SG_ 1620 DgnInf "Diagnostic Information";
BA_ "SignalType" SG_ 1620 DgnInf "UNM";
BA_ "DiagResponse" BO_ 1604 1;
BA_ "Prio" BO_ 1604 0;
BA_ "MessageSubnet" BO_ 1604 2;
BA_ "VNSigAllNodes" SG_ 1604 DgnInf 1;
BA_ "VNSigSLHSSharedDiagnostic" SG_ 1604 DgnInf 1;
BA_ "SignalLongName" SG_ 1604 DgnInf "Diagnostic Information";
BA_ "SignalType" SG_ 1604 DgnInf "UNM";
BA_ "GenMsgILSupport" BO_ 1612 0;
BA_ "DiagResponse" BO_ 1612 1;
BA_ "Prio" BO_ 1612 0;
BA_ "MessageSubnet" BO_ 1612 2;
BA_ "VNSigAllNodes" SG_ 1612 DgnInf 1;
BA_ "VNSigSLHSSharedDiagnostic" SG_ 1612 DgnInf 1;
BA_ "SignalLongName" SG_ 1612 DgnInf "Diagnostic Information";
BA_ "SignalType" SG_ 1612 DgnInf "UNM";
BA_ "DiagResponse" BO_ 1615 1;
BA_ "Prio" BO_ 1615 0;
BA_ "MessageSubnet" BO_ 1615 2;
BA_ "VNSigAllNodes" SG_ 1615 DgnInf 1;
BA_ "VNSigSLHSSharedDiagnostic" SG_ 1615 DgnInf 1;
BA_ "SignalLongName" SG_ 1615 DgnInf "Diagnostic Information";
BA_ "SignalType" SG_ 1615 DgnInf "UNM";
